[part 1 of 4: package /COM/VECTOR/CFG/WORKFLOW/SYSDESC/SYNC]
AUTOSAR XML (schema 4-3-0)
package /COM/VECTOR/CFG/WORKFLOW/SYSDESC/SYNC
  system SYSTEM: category=ECU_EXTRACT
    system mapping MAPPINGS
      data-mappings:
        sender-receiver-to-signal-mapping={data-element=COMPOSITIONTYPE.NO_VECH_{1..7}.NO_VECH_{1..7}, system-signal=NO_VECH_{1..7}}
        sender-receiver-to-signal-mapping={data-element=COMPOSITIONTYPE.ANFRAGE_ID2.requestedMsgID, system-signal=ANFRAGE_ID2}
        sender-receiver-to-signal-mapping={data-element=COMPOSITIONTYPE.ST_ENERG_FZM.energyState, system-signal=ST_ENERG_FZM}
        sender-receiver-to-signal-mapping={data-element=COMPOSITIONTYPE.ST_ILK_ERRM_FZM.centralErrorLock, system-signal=ST_ILK_ERRM_FZM}
        sender-receiver-to-signal-mapping={data-element=COMPOSITIONTYPE.T_SEC_COU_REL.timeSignal, system-signal=T_SEC_COU_REL}
        sender-receiver-to-signal-group-mapping={data-element=COMPOSITIONTYPE.sigGroup_CON_VEH.sigGroup_CON_VEH, signal-group=sigGroup_CON_VEH, type-mapping=sender-rec-record-type-mapping=record-element-mappings=[{implementation-record-element=ST_CON_VEH, system-signal=ST_CON_VEH}, {implementation-record-element=QU_ST_CON_VEH, system-signal=QU_ST_CON_VEH}, {implementation-record-element=CTR_FKTN_PRTNT, system-signal=CTR_FKTN_PRTNT}, {implementation-record-element=CTR_BS_PRTNT, system-signal=CTR_BS_PRTNT}, {implementation-record-element=CRC_CON_VEH, system-signal=CRC_CON_VEH}, {implementation-record-element=CON_VEH_dummy_56_63, system-signal=CON_VEH_dummy_56_63}, {implementation-record-element=ALIV_CON_VEH, system-signal=ALIV_CON_VEH}]}
        sender-receiver-to-signal-group-mapping={data-element=COMPOSITIONTYPE.sigGroup_OFFS_QUAD_EPS.sigGroup_OFFS_QUAD_EPS, signal-group=sigGroup_OFFS_QUAD_EPS, type-mapping=sender-rec-record-type-mapping=record-element-mappings=[{implementation-record-element=ST_OFFS_QUAD_EPS, system-signal=ST_OFFS_QUAD_EPS}, {implementation-record-element=OFFS_QUAD_RTR_EPS, system-signal=OFFS_QUAD_RTR_EPS}, {implementation-record-element=CRC_OFFS_QUAD_EPS, system-signal=CRC_OFFS_QUAD_EPS}, {implementation-record-element=AVL_PO_IDX_ICM, system-signal=AVL_PO_IDX_ICM}, {implementation-record-element=ALIV_OFFS_QUAD_EPS, system-signal=ALIV_OFFS_QUAD_EPS}]}
        sender-receiver-to-signal-group-mapping={data-element=COMPOSITIONTYPE.sigGroup_V_VEH.sigGroup_V_VEH, signal-group=sigGroup_V_VEH, type-mapping=sender-rec-record-type-mapping=record-element-mappings=[{implementation-record-element=V_VEH_dummy_39_39, system-signal=V_VEH_dummy_39_39}, {implementation-record-element=V_VEH_COG, system-signal=V_VEH_COG}, {implementation-record-element=ST_V_VEH_NSS, system-signal=ST_V_VEH_NSS}, {implementation-record-element=QU_V_VEH_COG, system-signal=QU_V_VEH_COG}, {implementation-record-element=DVCO_VEH, system-signal=DVCO_VEH}, {implementation-record-element=CRC_V_VEH, system-signal=CRC_V_VEH}, {implementation-record-element=ALIV_V_VEH, system-signal=ALIV_V_VEH}]}
        sender-receiver-to-signal-group-mapping={data-element=COMPOSITIONTYPE.sigGroup_DISP_CC_EPS.sigGroup_DISP_CC_EPS, signal-group=sigGroup_DISP_CC_EPS, type-mapping=sender-rec-record-type-mapping=record-element-mappings=[{implementation-record-element=TRANF_CC_EPS, system-signal=TRANF_CC_EPS}, {implementation-record-element=ST_IDC_CC_EPS, system-signal=ST_IDC_CC_EPS}, {implementation-record-element=ST_CC_EPS, system-signal=ST_CC_EPS}, {implementation-record-element=NO_CC_EPS, system-signal=NO_CC_EPS}, {implementation-record-element=CRC_DISP_CC_EPS, system-signal=CRC_DISP_CC_EPS}, {implementation-record-element=CHL_DISP_CC_EPS, system-signal=CHL_DISP_CC_EPS}, {implementation-record-element=ALIV_DISP_CC_EPS, system-signal=ALIV_DISP_CC_EPS}]}
        sender-receiver-to-signal-group-mapping={data-element=COMPOSITIONTYPE.sigGroup_AVL_PO_EPS.sigGroup_AVL_PO_EPS, signal-group=sigGroup_AVL_PO_EPS, type-mapping=sender-rec-record-type-mapping=record-element-mappings=[{implementation-record-element=UN_PO_EPS, system-signal=UN_PO_EPS}, {implementation-record-element=QU_AVL_PO_EPS, system-signal=QU_AVL_PO_EPS}, {implementation-record-element=OFFS_GRD_MID_EPS, system-signal=OFFS_GRD_MID_EPS}, {implementation-record-element=IDX_TORQ_SEN, system-signal=IDX_TORQ_SEN}, {implementation-record-element=CRC_AVL_PO_EPS, system-signal=CRC_AVL_PO_EPS}, {implementation-record-element=AVL_PO_IDX_EPS, system-signal=AVL_PO_IDX_EPS}, {implementation-record-element=AVL_PO_EPS, system-signal=AVL_PO_EPS}, {implementation-record-element=ALIV_AVL_PO_EPS, system-signal=ALIV_AVL_PO_EPS}]}
        sender-receiver-to-signal-mapping={data-element=COMPOSITIONTYPE.TRGG_ENGTORQ_EPS.TRGG_ENGTORQ_EPS, system-signal=TRGG_ENGTORQ_EPS}
        sender-receiver-to-signal-mapping={data-element=COMPOSITIONTYPE.FACT_MO_STE_SO_DXP.FACT_MO_STE_SO_DXP, system-signal=FACT_MO_STE_SO_DXP}
        sender-receiver-to-signal-mapping={data-element=COMPOSITIONTYPE.SU_CLU_STMOM_SFE_DXP.SU_CLU_STMOM_SFE_DXP, system-signal=SU_CLU_STMOM_SFE_DXP}
        sender-receiver-to-signal-group-mapping={data-element=COMPOSITIONTYPE.sigGroup_ST_EST.sigGroup_ST_EST, signal-group=sigGroup_ST_EST, type-mapping=sender-rec-record-type-mapping=record-element-mappings=[{implementation-record-element=ST_EST_dummy_16_23, system-signal=ST_EST_dummy_16_23}, {implementation-record-element=QU_SER_STMOM_DV_ACT, system-signal=QU_SER_STMOM_DV_ACT}, {implementation-record-element=QU_FN_VIB_EPS, system-signal=QU_FN_VIB_EPS}, {implementation-record-element=QU_FN_EST, system-signal=QU_FN_EST}, {implementation-record-element=CRC_ST_EST_FTAX, system-signal=CRC_ST_EST_FTAX}, {implementation-record-element=ALIV_ST_EST_FTAX, system-signal=ALIV_ST_EST_FTAX}]}
        sender-receiver-to-signal-group-mapping={data-element=COMPOSITIONTYPE.sigGroup_SU_EPS.sigGroup_SU_EPS, signal-group=sigGroup_SU_EPS, type-mapping=sender-rec-record-type-mapping=record-element-mappings=[{implementation-record-element=UN_TOT_STR_EPS, system-signal=UN_TOT_STR_EPS}, {implementation-record-element=TOT_STR_EPS, system-signal=TOT_STR_EPS}, {implementation-record-element=SU_EPS_dummy_20_51, system-signal=SU_EPS_dummy_20_51}, {implementation-record-element=SU_EPS_dummy_14_19, system-signal=SU_EPS_dummy_14_19}, {implementation-record-element=CRC_SU_EPS, system-signal=CRC_SU_EPS}, {implementation-record-element=ALIV_SU_EPS, system-signal=ALIV_SU_EPS}]}
        sender-receiver-to-signal-group-mapping={data-element=COMPOSITIONTYPE.sigGroup_ACLNY_MASSCNTR.sigGroup_ACLNY_MASSCNTR, signal-group=sigGroup_ACLNY_MASSCNTR, type-mapping=sender-rec-record-type-mapping=record-element-mappings=[{implementation-record-element=QU_ACLNY_COG, system-signal=QU_ACLNY_COG}, {implementation-record-element=CRC_ACLNY_COG, system-signal=CRC_ACLNY_COG}, {implementation-record-element=ALIV_ACLNY_COG, system-signal=ALIV_ACLNY_COG}, {implementation-record-element=ACLNY_MASSCNTR_dummy_12_15, system-signal=ACLNY_MASSCNTR_dummy_12_15}, {implementation-record-element=ACLNY_COG_ERR_AMP, system-signal=ACLNY_COG_ERR_AMP}, {implementation-record-element=ACLNY_COG, system-signal=ACLNY_COG}]}
        sender-receiver-to-signal-group-mapping={data-element=COMPOSITIONTYPE.sigGroup_TAR_QTA_STRMOM_DV.sigGroup_TAR_QTA_STRMOM_DV, signal-group=sigGroup_TAR_QTA_STRMOM_DV, type-mapping=sender-rec-record-type-mapping=record-element-mappings=[{implementation-record-element=TAR_QTA_STRMOM_DV_dummy_12_15, system-signal=TAR_QTA_STRMOM_DV_dummy_12_15}, {implementation-record-element=TAR_QTA_STMOM_DV, system-signal=TAR_QTA_STMOM_DV}, {implementation-record-element=QU_TAR_QTA_STMOM_DV, system-signal=QU_TAR_QTA_STMOM_DV}, {implementation-record-element=QU_TAR_FACT_STMOM_FTAX, system-signal=QU_TAR_FACT_STMOM_FTAX}, {implementation-record-element=FACT_DMPNG_STMOM_FTAX, system-signal=FACT_DMPNG_STMOM_FTAX}, {implementation-record-element=FACT_CTRR_STMOM_FTAX, system-signal=FACT_CTRR_STMOM_FTAX}, {implementation-record-element=FACT_ASS_STMOM_FTAX, system-signal=FACT_ASS_STMOM_FTAX}, {implementation-record-element=CTR_DEAC_EPS_FNS, system-signal=CTR_DEAC_EPS_FNS}, {implementation-record-element=CRC_TAR_QTA_STMOM_DV, system-signal=CRC_TAR_QTA_STMOM_DV}, {implementation-record-element=ALIV_TAR_QTA_STMOM_DV, system-signal=ALIV_TAR_QTA_STMOM_DV}]}
        sender-receiver-to-signal-group-mapping={data-element=COMPOSITIONTYPE.sigGroup_TAR_STMOM_DV_ACT.sigGroup_TAR_STMOM_DV_ACT, signal-group=sigGroup_TAR_STMOM_DV_ACT, type-mapping=sender-rec-record-type-mapping=record-element-mappings=[{implementation-record-element=TAR_STMOM_DV_ACT_dummy_32_51, system-signal=TAR_STMOM_DV_ACT_dummy_32_51}, {implementation-record-element=TAR_STMOM_DV_ACT_dummy_12_15, system-signal=TAR_STMOM_DV_ACT_dummy_12_15}, {implementation-record-element=TAR_STMOM_DV_ACT, system-signal=TAR_STMOM_DV_ACT}, {implementation-record-element=QU_TAR_STMOM_DV_ACT, system-signal=QU_TAR_STMOM_DV_ACT}, {implementation-record-element=QU_TAR_DMPNG_ADDON_STMOM_FTAX, system-signal=QU_TAR_DMPNG_ADDON_STMOM_FTAX}, {implementation-record-element=FACT_DMPNG_ADDON_STMOM_FTAX, system-signal=FACT_DMPNG_ADDON_STMOM_FTAX}, {implementation-record-element=CRC_TAR_STMOM_DV_ACT, system-signal=CRC_TAR_STMOM_DV_ACT}, {implementation-record-element=ALIV_TAR_STMOM_DV_ACT, system-signal=ALIV_TAR_STMOM_DV_ACT}]}
        sender-receiver-to-signal-group-mapping={data-element=COMPOSITIONTYPE.sigGroup_VYAW_VEH.sigGroup_VYAW_VEH, signal-group=sigGroup_VYAW_VEH, type-mapping=sender-rec-record-type-mapping=record-element-mappings=[{implementation-record-element=VYAW_VEH_dummy_12_15, system-signal=VYAW_VEH_dummy_12_15}, {implementation-record-element=VYAW_VEH_ERR_AMP, system-signal=VYAW_VEH_ERR_AMP}, {implementation-record-element=VYAW_VEH, system-signal=VYAW_VEH}, {implementation-record-element=QU_VYAW_VEH, system-signal=QU_VYAW_VEH}, {implementation-record-element=CRC_VYAW_VEH, system-signal=CRC_VYAW_VEH}, {implementation-record-element=ALIV_VYAW_VEH, system-signal=ALIV_VYAW_VEH}]}
        sender-receiver-to-signal-group-mapping={data-element=COMPOSITIONTYPE.sigGroup_DT_EST.sigGroup_DT_EST, signal-group=sigGroup_DT_EST, type-mapping=sender-rec-record-type-mapping=record-element-mappings=[{implementation-record-element=ST_CULI_EST, system-signal=ST_CULI_EST}, {implementation-record-element=QU_AVL_I_ACT_EST, system-signal=QU_AVL_I_ACT_EST}, {implementation-record-element=DT_EST_dummy_96_127, system-signal=DT_EST_dummy_96_127}, {implementation-record-element=DT_EST_dummy_64_95, system-signal=DT_EST_dummy_64_95}, {implementation-record-element=DT_EST_dummy_16_47, system-signal=DT_EST_dummy_16_47}, {implementation-record-element=DT_EST_dummy_12_15, system-signal=DT_EST_dummy_12_15}, {implementation-record-element=CRC_DT_EST, system-signal=CRC_DT_EST}, {implementation-record-element=AVL_I_ACT_EST, system-signal=AVL_I_ACT_EST}, {implementation-record-element=ALIV_DT_EST, system-signal=ALIV_DT_EST}]}
        sender-receiver-to-signal-mapping={data-element=COMPOSITIONTYPE.AVL_STEA_PNI_OFFS.AVL_STEA_PNI_OFFS, system-signal=AVL_STEA_PNI_OFFS}
        sender-receiver-to-signal-mapping={data-element=COMPOSITIONTYPE.CTR_WARN_DIR_VIB_EPS.CTR_WARN_DIR_VIB_EPS, system-signal=CTR_WARN_DIR_VIB_EPS}
        sender-receiver-to-signal-mapping={data-element=COMPOSITIONTYPE.CTR_WARN_ILVL_VIB_EPS.CTR_WARN_ILVL_VIB_EPS, system-signal=CTR_WARN_ILVL_VIB_EPS}
        sender-receiver-to-signal-mapping={data-element=COMPOSITIONTYPE.CTR_WARN_PTRN_VIB_EPS.CTR_WARN_PTRN_VIB_EPS, system-signal=CTR_WARN_PTRN_VIB_EPS}
        sender-receiver-to-signal-mapping={data-element=COMPOSITIONTYPE.MILE_KM.MILE_KM, system-signal=MILE_KM}
        sender-receiver-to-signal-group-mapping={data-element=COMPOSITIONTYPE.sigGroup_ENERG_DGR_DRDY.sigGroup_ENERG_DGR_DRDY, signal-group=sigGroup_ENERG_DGR_DRDY, type-mapping=sender-rec-record-type-mapping=record-element-mappings=[{implementation-record-element=RQ_CULI_EST_SFY, system-signal=RQ_CULI_EST_SFY}, {implementation-record-element=QU_DGR_AISP_ENERG, system-signal=QU_DGR_AISP_ENERG}, {implementation-record-element=MAX_I_SPEC_EPS, system-signal=MAX_I_SPEC_EPS}, {implementation-record-element=MAX_I_SPEC_BAX_STE, system-signal=MAX_I_SPEC_BAX_STE}, {implementation-record-element=MAX_I_RECUP_SPEC_ARS, system-signal=MAX_I_RECUP_SPEC_ARS}, {implementation-record-element=MAX_I_LD_SPEC_ARS, system-signal=MAX_I_LD_SPEC_ARS}, {implementation-record-element=ENERG_DGR_DRDY_dummy_12_15, system-signal=ENERG_DGR_DRDY_dummy_12_15}, {implementation-record-element=ENERG_AVAI_ARS, system-signal=ENERG_AVAI_ARS}, {implementation-record-element=CRC_ENERG_DGR_DRDY, system-signal=CRC_ENERG_DGR_DRDY}, {implementation-record-element=ALIV_ENERG_DGR_DRDY, system-signal=ALIV_ENERG_DGR_DRDY}]}
        sender-receiver-to-signal-group-mapping={data-element=COMPOSITIONTYPE.sigGroup_AVL_FORC_GRD.sigGroup_AVL_FORC_GRD, signal-group=sigGroup_AVL_FORC_GRD, type-mapping=sender-rec-record-type-mapping=record-element-mappings=[{implementation-record-element=QU_AVL_FORC_GRD, system-signal=QU_AVL_FORC_GRD}, {implementation-record-element=CRC_AVL_FORC_GRD, system-signal=CRC_AVL_FORC_GRD}, {implementation-record-element=AVL_PWR_EL_EPS_COOD, system-signal=AVL_PWR_EL_EPS_COOD}, {implementation-record-element=AVL_FORC_GRD_dummy_12_15, system-signal=AVL_FORC_GRD_dummy_12_15}, {implementation-record-element=AVL_FORC_GRD, system-signal=AVL_FORC_GRD}, {implementation-record-element=ALIV_AVL_FORC_GRD, system-signal=ALIV_AVL_FORC_GRD}]}
        sender-receiver-to-signal-group-mapping={data-element=COMPOSITIONTYPE.sigGroup_AVL_STMOM_DV_ACT.sigGroup_AVL_STMOM_DV_ACT, signal-group=sigGroup_AVL_STMOM_DV_ACT, type-mapping=sender-rec-record-type-mapping=record-element-mappings=[{implementation-record-element=QU_AVL_STMOM_DV_ACT, system-signal=QU_AVL_STMOM_DV_ACT}, {implementation-record-element=CRC_AVL_STMOM_DV_ACT, system-signal=CRC_AVL_STMOM_DV_ACT}, {implementation-record-element=AVL_STMOM_DV_ACT_dummy_12_15, system-signal=AVL_STMOM_DV_ACT_dummy_12_15}, {implementation-record-element=AVL_STMOM_DV_ACT, system-signal=AVL_STMOM_DV_ACT}, {implementation-record-element=ALIV_AVL_STMOM_DV_ACT, system-signal=ALIV_AVL_STMOM_DV_ACT}]}
        sender-receiver-to-signal-mapping={data-element=COMPOSITIONTYPE.BATT_VLTG_EPS.BATT_VLTG_EPS, system-signal=BATT_VLTG_EPS}
        sender-receiver-to-signal-mapping={data-element=COMPOSITIONTYPE.DBG_EPS_BS_MOD_58_BYTE_ID2.DBG_EPS_BS_MOD_58_BYTE_ID2, system-signal=DBG_EPS_BS_MOD_58_BYTE_ID2}
        sender-receiver-to-signal-mapping={data-element=COMPOSITIONTYPE.ECU_TEMP_EPS.ECU_TEMP_EPS, system-signal=ECU_TEMP_EPS}
        sender-receiver-to-signal-mapping={data-element=COMPOSITIONTYPE.MOT_FET_TEMP_EPS.MOT_FET_TEMP_EPS, system-signal=MOT_FET_TEMP_EPS}
        sender-receiver-to-signal-mapping={data-element=COMPOSITIONTYPE.MOT_MAG_TEMP_EPS.MOT_MAG_TEMP_EPS, system-signal=MOT_MAG_TEMP_EPS}
        sender-receiver-to-signal-mapping={data-element=COMPOSITIONTYPE.MOT_TQ_CMD_EPS.MOT_TQ_CMD_EPS, system-signal=MOT_TQ_CMD_EPS}
        sender-receiver-to-signal-mapping={data-element=COMPOSITIONTYPE.MOT_TQ_CMD_LIMD_EPS.MOT_TQ_CMD_LIMD_EPS, system-signal=MOT_TQ_CMD_LIMD_EPS}
        sender-receiver-to-signal-mapping={data-element=COMPOSITIONTYPE.MOT_VEL_EPS.MOT_VEL_EPS, system-signal=MOT_VEL_EPS}
        sender-receiver-to-signal-mapping={data-element=COMPOSITIONTYPE.MOT_WIDG_TEMP_EPS.MOT_WIDG_TEMP_EPS, system-signal=MOT_WIDG_TEMP_EPS}
        sender-receiver-to-signal-mapping={data-element=COMPOSITIONTYPE.PRIM_HW_TQ_SNSR_VLTG_EPS.PRIM_HW_TQ_SNSR_VLTG_EPS, system-signal=PRIM_HW_TQ_SNSR_VLTG_EPS}
        sender-receiver-to-signal-mapping={data-element=COMPOSITIONTYPE.SECDRY_HW_TQ_SNSR_VLTG_EPS.SECDRY_HW_TQ_SNSR_VLTG_EPS, system-signal=SECDRY_HW_TQ_SNSR_VLTG_EPS}
        sender-receiver-to-signal-mapping={data-element=COMPOSITIONTYPE.VEH_SPD_EPS.VEH_SPD_EPS, system-signal=VEH_SPD_EPS}
    root-software-compositions:
      root sw composition prototype COMPOSITIONTYPE: flat-map=FLATMAP, software-composition=COMPOSITIONTYPE
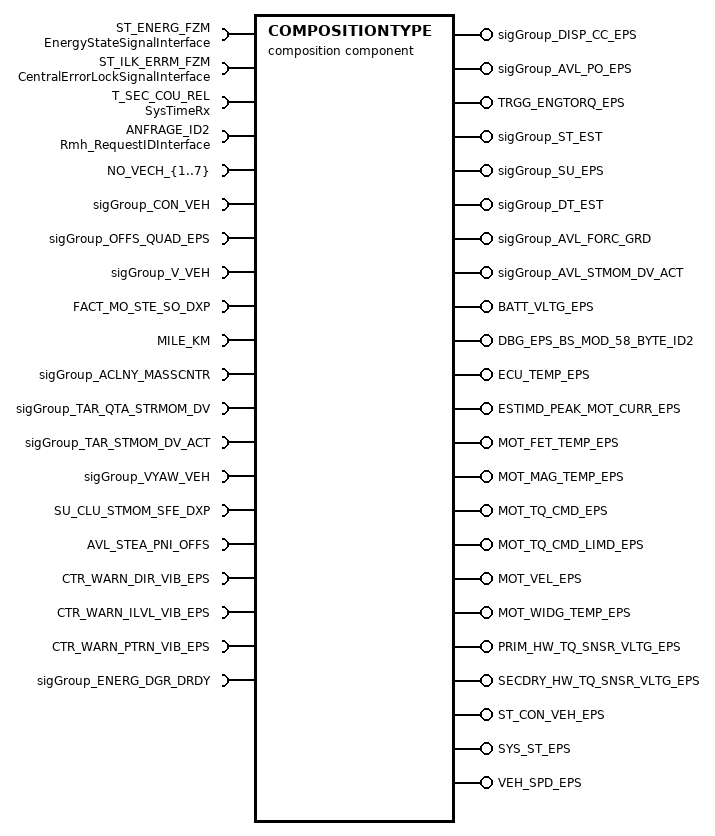
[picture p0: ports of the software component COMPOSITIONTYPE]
  composition sw component type COMPOSITIONTYPE  # UB:Derived from original system description
    14 x require port:
      ST_ENERG_FZM: nonqueued-receiver-com-spec{data-element=energyState, uses-end-to-end-protection=true, alive-timeout=21, enable-update=true, filter=data-filter-type=ALWAYS, init-value=15}, required-interface=EnergyStateSignalInterface
      ST_ILK_ERRM_FZM: nonqueued-receiver-com-spec{data-element=centralErrorLock, alive-timeout=21, filter=data-filter-type=ALWAYS, init-value=3}, required-interface=CentralErrorLockSignalInterface
      T_SEC_COU_REL: nonqueued-receiver-com-spec{data-element=timeSignal, filter=data-filter-type=ALWAYS}, required-interface=SysTimeRx
      ANFRAGE_ID2: nonqueued-receiver-com-spec{data-element=requestedMsgID, filter=data-filter-type=ALWAYS}, required-interface=Rmh_RequestIDInterface
      NO_VECH_{1..7}: nonqueued-receiver-com-spec{data-element=NO_VECH_{1..7}, filter=data-filter-type=ALWAYS}, required-interface=NO_VECH_{1..7}
      sigGroup_CON_VEH: nonqueued-receiver-com-spec{data-element=sigGroup_CON_VEH, uses-end-to-end-protection=true, alive-timeout=0.11, enable-update=true, filter=data-filter-type=ALWAYS, init-value=fields=[0, CON_VEH_dummy_56_63:15, CRC_CON_VEH:0, CTR_BS_PRTNT:15, CTR_FKTN_PRTNT:15, QU_ST_CON_VEH:0, ST_CON_VEH:0]}, required-interface=sigGroup_CON_VEH
      sigGroup_OFFS_QUAD_EPS: nonqueued-receiver-com-spec{data-element=sigGroup_OFFS_QUAD_EPS, uses-end-to-end-protection=true, alive-timeout=1.1, enable-update=true, filter=data-filter-type=ALWAYS, init-value=fields=[AVL_PO_IDX_ICM:65535, ST_OFFS_QUAD_EPS:15, CRC_OFFS_QUAD_EPS:0, OFFS_QUAD_RTR_EPS:255, ALIV_OFFS_QUAD_EPS:0]}, required-interface=sigGroup_OFFS_QUAD_EPS
      sigGroup_V_VEH: nonqueued-receiver-com-spec{data-element=sigGroup_V_VEH, uses-end-to-end-protection=true, alive-timeout=0.02, enable-update=true, filter=data-filter-type=ALWAYS, init-value=fields=[0, CRC_V_VEH:0, DVCO_VEH:0, QU_V_VEH_COG:0, ST_V_VEH_NSS:1, V_VEH_COG:0, V_VEH_dummy_39_39:0]}, required-interface=sigGroup_V_VEH
    5 x provide port:
      sigGroup_DISP_CC_EPS: nonqueued-sender-com-spec{data-element=sigGroup_DISP_CC_EPS, uses-end-to-end-protection=true}, provided-interface=sigGroup_DISP_CC_EPS
      sigGroup_AVL_PO_EPS: nonqueued-sender-com-spec{data-element=sigGroup_AVL_PO_EPS, uses-end-to-end-protection=true}, provided-interface=sigGroup_AVL_PO_EPS
      TRGG_ENGTORQ_EPS: nonqueued-sender-com-spec=data-element=TRGG_ENGTORQ_EPS, provided-interface=TRGG_ENGTORQ_EPS
      sigGroup_ST_EST: nonqueued-sender-com-spec{data-element=sigGroup_ST_EST, uses-end-to-end-protection=true}, provided-interface=sigGroup_ST_EST
      sigGroup_SU_EPS: nonqueued-sender-com-spec{data-element=sigGroup_SU_EPS, uses-end-to-end-protection=true}, provided-interface=sigGroup_SU_EPS
    8 x require port:
      FACT_MO_STE_SO_DXP: nonqueued-receiver-com-spec{data-element=FACT_MO_STE_SO_DXP, alive-timeout=0.045, filter=data-filter-type=ALWAYS, init-value=255}, required-interface=FACT_MO_STE_SO_DXP
      MILE_KM: nonqueued-receiver-com-spec{data-element=MILE_KM, alive-timeout=11, filter=data-filter-type=ALWAYS, init-value=0}, required-interface=MILE_KM
      sigGroup_ACLNY_MASSCNTR: nonqueued-receiver-com-spec{data-element=sigGroup_ACLNY_MASSCNTR, uses-end-to-end-protection=true, alive-timeout=0.015, enable-update=true, filter=data-filter-type=ALWAYS}, required-interface=sigGroup_ACLNY_MASSCNTR
      sigGroup_TAR_QTA_STRMOM_DV: nonqueued-receiver-com-spec{data-element=sigGroup_TAR_QTA_STRMOM_DV, uses-end-to-end-protection=true, alive-timeout=0.015, enable-update=true, filter=data-filter-type=ALWAYS}, required-interface=sigGroup_TAR_QTA_STRMOM_DV
      sigGroup_TAR_STMOM_DV_ACT: nonqueued-receiver-com-spec{data-element=sigGroup_TAR_STMOM_DV_ACT, uses-end-to-end-protection=true, alive-timeout=0.015, enable-update=true, filter=data-filter-type=ALWAYS}, required-interface=sigGroup_TAR_STMOM_DV_ACT
      sigGroup_VYAW_VEH: nonqueued-receiver-com-spec{data-element=sigGroup_VYAW_VEH, uses-end-to-end-protection=true, alive-timeout=0.015, enable-update=true, filter=data-filter-type=ALWAYS}, required-interface=sigGroup_VYAW_VEH
      SU_CLU_STMOM_SFE_DXP: nonqueued-receiver-com-spec{data-element=SU_CLU_STMOM_SFE_DXP, alive-timeout=0.045, filter=data-filter-type=ALWAYS, init-value=15}, required-interface=SU_CLU_STMOM_SFE_DXP
      AVL_STEA_PNI_OFFS: nonqueued-receiver-com-spec{data-element=AVL_STEA_PNI_OFFS, uses-end-to-end-protection=true, alive-timeout=0.11, enable-update=true, filter=data-filter-type=ALWAYS, init-value=2046}, required-interface=AVL_STEA_PNI_OFFS
    provide port sigGroup_DT_EST: nonqueued-sender-com-spec{data-element=sigGroup_DT_EST, uses-end-to-end-protection=true}, provided-interface=sigGroup_DT_EST
    4 x require port:
      CTR_WARN_DIR_VIB_EPS: nonqueued-receiver-com-spec{data-element=CTR_WARN_DIR_VIB_EPS, alive-timeout=0.55, filter=data-filter-type=ALWAYS, init-value=3}, required-interface=CTR_WARN_DIR_VIB_EPS
      CTR_WARN_ILVL_VIB_EPS: nonqueued-receiver-com-spec{data-element=CTR_WARN_ILVL_VIB_EPS, alive-timeout=0.55, filter=data-filter-type=ALWAYS, init-value=15}, required-interface=CTR_WARN_ILVL_VIB_EPS
      CTR_WARN_PTRN_VIB_EPS: nonqueued-receiver-com-spec{data-element=CTR_WARN_PTRN_VIB_EPS, alive-timeout=0.55, filter=data-filter-type=ALWAYS, init-value=15}, required-interface=CTR_WARN_PTRN_VIB_EPS
      sigGroup_ENERG_DGR_DRDY: nonqueued-receiver-com-spec{data-element=sigGroup_ENERG_DGR_DRDY, uses-end-to-end-protection=true, alive-timeout=0.015, enable-update=true, filter=data-filter-type=ALWAYS}, required-interface=sigGroup_ENERG_DGR_DRDY
    17 x provide port:
      sigGroup_AVL_FORC_GRD: nonqueued-sender-com-spec{data-element=sigGroup_AVL_FORC_GRD, uses-end-to-end-protection=true}, provided-interface=sigGroup_AVL_FORC_GRD
      sigGroup_AVL_STMOM_DV_ACT: nonqueued-sender-com-spec{data-element=sigGroup_AVL_STMOM_DV_ACT, uses-end-to-end-protection=true}, provided-interface=sigGroup_AVL_STMOM_DV_ACT
      BATT_VLTG_EPS: nonqueued-sender-com-spec{data-element=BATT_VLTG_EPS, init-value=0}, provided-interface=BATT_VLTG_EPS
      DBG_EPS_BS_MOD_58_BYTE_ID2: nonqueued-sender-com-spec{data-element=DBG_EPS_BS_MOD_58_BYTE_ID2, init-value=SWITCH_CODE:1}, provided-interface=DBG_EPS_BS_MOD_58_BYTE_ID2
      ECU_TEMP_EPS: nonqueued-sender-com-spec=data-element=ECU_TEMP_EPS, provided-interface=ECU_TEMP_EPS
      ESTIMD_PEAK_MOT_CURR_EPS: nonqueued-sender-com-spec=data-element=ESTIMD_PEAK_MOT_CURR_EPS, provided-interface=ESTIMD_PEAK_MOT_CURR_EPS
      MOT_FET_TEMP_EPS: nonqueued-sender-com-spec=data-element=MOT_FET_TEMP_EPS, provided-interface=MOT_FET_TEMP_EPS
      MOT_MAG_TEMP_EPS: nonqueued-sender-com-spec=data-element=MOT_MAG_TEMP_EPS, provided-interface=MOT_MAG_TEMP_EPS
      MOT_TQ_CMD_EPS: nonqueued-sender-com-spec=data-element=MOT_TQ_CMD_EPS, provided-interface=MOT_TQ_CMD_EPS
      MOT_TQ_CMD_LIMD_EPS: nonqueued-sender-com-spec=data-element=MOT_TQ_CMD_LIMD_EPS, provided-interface=MOT_TQ_CMD_LIMD_EPS
      MOT_VEL_EPS: nonqueued-sender-com-spec=data-element=MOT_VEL_EPS, provided-interface=MOT_VEL_EPS
      MOT_WIDG_TEMP_EPS: nonqueued-sender-com-spec=data-element=MOT_WIDG_TEMP_EPS, provided-interface=MOT_WIDG_TEMP_EPS
      PRIM_HW_TQ_SNSR_VLTG_EPS: nonqueued-sender-com-spec=data-element=PRIM_HW_TQ_SNSR_VLTG_EPS, provided-interface=PRIM_HW_TQ_SNSR_VLTG_EPS
      SECDRY_HW_TQ_SNSR_VLTG_EPS: nonqueued-sender-com-spec=data-element=SECDRY_HW_TQ_SNSR_VLTG_EPS, provided-interface=SECDRY_HW_TQ_SNSR_VLTG_EPS
      ST_CON_VEH_EPS: nonqueued-sender-com-spec=data-element=ST_CON_VEH_EPS, provided-interface=ST_CON_VEH_EPS
      SYS_ST_EPS: nonqueued-sender-com-spec=data-element=SYS_ST_EPS, provided-interface=SYS_ST_EPS
      VEH_SPD_EPS: nonqueued-sender-com-spec=data-element=VEH_SPD_EPS, provided-interface=VEH_SPD_EPS
    276 x component:
      BswM: type=BswM
      Det: type=Det
      EcuM: type=EcuM
      Os_OsCore_CORE0_swc: type=Os_OsCore_CORE0_swc
      NvM: type=NvM
      WdgM_Appl10: type=WdgM_Appl10
      McalErrHndlg: type=McalErrHndlg
      CDD_NxtrTi: type=CDD_NxtrTi
      NxtrMath: type=NxtrMath
      McuErrInj: type=McuErrInj
      CDD_ExcpnHndlg: type=CDD_ExcpnHndlg
      DiagcMgr: type=DiagcMgr
      DiagcMgrProxyAppl10: type=DiagcMgrProxyAppl10
      DiagcMgrStub: type=DiagcMgrStub
      SysStMod: type=SysStMod
      CDD_NvMProxy: type=CDD_NvMProxy
      NvMProxy: type=NvMProxy
      CDD_EcmOutpAndDiagc: type=CDD_EcmOutpAndDiagc
      CDD_GuardCfgAndDiagc: type=CDD_GuardCfgAndDiagc
      CDD_SyncCrc: type=CDD_SyncCrc
      FltInj: type=FltInj
      CDD_Adc0CfgAndUse: type=CDD_Adc0CfgAndUse
      CDD_Adc1CfgAndUse: type=CDD_Adc1CfgAndUse
      CDD_AdcDiagc: type=CDD_AdcDiagc
      CDD_DmaCfgAndUse: type=CDD_DmaCfgAndUse
      CDD_MotAg0Meas: type=CDD_MotAg0Meas
      CDD_MotAg1Meas: type=CDD_MotAg1Meas
      CDD_Tauj0CfgAndUse: type=CDD_Tauj0CfgAndUse
      CDD_TSG31CfgAndUse: type=CDD_TSG31CfgAndUse
      CDD_MotCtrlMgr: type=CDD_MotCtrlMgr
      IoHwAb: type=IoHwAb
      CDD_CurrMeas: type=CDD_CurrMeas
      MotAgCorrln: type=MotAgCorrln
      CDD_Bmw5441McuCfg: type=CDD_Bmw5441McuCfg
      BattVltg: type=BattVltg
      BattVltgCorrln: type=BattVltgCorrln
      EcuTMeas: type=EcuTMeas
      CDD_FlsMem: type=CDD_FlsMem
      CDD_RamMem: type=CDD_RamMem
      CDD_ChkPtAppl10: type=CDD_ChkPtAppl10
      ComM: type=ComM
      Dcm: type=Dcm
      Vin: type=Vin
      CmnMfgSrv: type=CmnMfgSrv
      NxtrSwIds: type=NxtrSwIds
      CDD_MotAgCmp: type=CDD_MotAgCmp
      CDD_SinVltgGenn: type=CDD_SinVltgGenn
      GateDrv0Ctrl: type=GateDrv0Ctrl
      PolarityCfg: type=PolarityCfg
      PwrDiscnct: type=PwrDiscnct
      PwrSply: type=PwrSply
      PwrUpSeq: type=PwrUpSeq
      ShtdwnMech: type=ShtdwnMech
      TmplMonr: type=TmplMonr
      CDD_HwTq4Meas: type=CDD_HwTq4Meas
      CDD_HwTq5Meas: type=CDD_HwTq5Meas
      HwTqArbn: type=HwTqArbn
      HwTqCorrln: type=HwTqCorrln
      CDD_MotCurrRegVltgLimr: type=CDD_MotCurrRegVltgLimr
      CDD_MotVel: type=CDD_MotVel
      DutyCycThermProtn: type=DutyCycThermProtn
      ElecPwrCns: type=ElecPwrCns
      HiLoadStallLimr: type=HiLoadStallLimr
      MotCtrlPrmEstimn: type=MotCtrlPrmEstimn
      MotCurrPeakEstimn: type=MotCurrPeakEstimn
      MotCurrRegCfg: type=MotCurrRegCfg
      MotQuadDetn: type=MotQuadDetn
      MotRefMdl: type=MotRefMdl
      PwrLimr: type=PwrLimr
      TEstimn: type=TEstimn
      MotTqCmdSca: type=MotTqCmdSca
      MotTqTranlDampg: type=MotTqTranlDampg
      Swp: type=Swp
      BacComIf: type=BacComIf
      CDD_ChkPtAppl{7..9}: type=CDD_ChkPtAppl{7..9}
      WdgM_Appl9: type=WdgM_Appl9
      WdgM_Appl8: type=WdgM_Appl8
      WdgM_Appl7: type=WdgM_Appl7
      EotProtn: type=EotProtn
      PosnTrakgServo: type=PosnTrakgServo
      StOutpCtrl: type=StOutpCtrl
      SysFricLrng: type=SysFricLrng
      VehSpdLimr: type=VehSpdLimr
      VehSigCdng: type=VehSigCdng
      CmplncErr: type=CmplncErr
      LimrCdng: type=LimrCdng
      TunSelnAuthy: type=TunSelnAuthy
      CDD_CurrMeasArbn: type=CDD_CurrMeasArbn
      CurrMeasCorrln: type=CurrMeasCorrln
      TurnCntrCorrln: type=TurnCntrCorrln
      CDD_McuDiagc: type=CDD_McuDiagc
      MotVelCtrl: type=MotVelCtrl
      CDD_CoreVltgMonr: type=CDD_CoreVltgMonr
      CDD_McuCoreCfgAndDiagc: type=CDD_McuCoreCfgAndDiagc
      CDD_VrfyCritReg: type=CDD_VrfyCritReg
      CDD_DataAndAdrPar: type=CDD_DataAndAdrPar
      BmwMsgSlot107Bas0Repn1BusFrChA: type=BmwMsgSlot107Bas0Repn1BusFrChA
      BmwMsgSlot121Bas1Repn2BusFrChA: type=BmwMsgSlot121Bas1Repn2BusFrChA
      BmwMsgSlot55Bas3Repn4BusFrChA: type=BmwMsgSlot55Bas3Repn4BusFrChA
      DiagcMgrProxyAppl7: type=DiagcMgrProxyAppl7
      BmwHwAgArbnAndEotPosn: type=BmwHwAgArbnAndEotPosn
      LrndRackCentr: type=LrndRackCentr
      LrnPinionCentr: type=LrnPinionCentr
      BmwMsgSlot274Bas2Repn4BusFrChA: type=BmwMsgSlot274Bas2Repn4BusFrChA
      BmwMsgSlot51Bas0Repn2BusFrChA: type=BmwMsgSlot51Bas0Repn2BusFrChA
      BmwFltHndlg: type=BmwFltHndlg
      BmwStReqMgr: type=BmwStReqMgr
      CtrldVelRtn: type=CtrldVelRtn
      DiagcMgrProxyAppl8: type=DiagcMgrProxyAppl8
      DiagcMgrProxyAppl9: type=DiagcMgrProxyAppl9
      BmwDiagcSrvHndlg: type=BmwDiagcSrvHndlg
      CDD_XcpIf: type=CDD_XcpIf
      TunSelnMngt: type=TunSelnMngt
      CDD_XcpIfXcpEve2MilliSecDataAcqn: type=CDD_XcpIfXcpEve2MilliSecDataAcqn
      PhaDiscnct: type=PhaDiscnct
      RvsBattProtn: type=RvsBattProtn
      LoaMgr: type=LoaMgr
      CDD_BattRtnCurr: type=CDD_BattRtnCurr
      BmwVehSpd: type=BmwVehSpd
      Dlog: type=Dlog
      StdDiag: type=StdDiag
      Omc: type=Omc
      Darh: type=Darh
      Stm: type=Stm
      Coding: type=Coding
      Rmh: type=Rmh
      Rmh_Cdd: type=Rmh_Cdd
      SysTime: type=SysTime
      DemMaster_0: type=DemMaster_0
      DemSatellite_0: type=DemSatellite_0
      CmnMfgSrvIf: type=CmnMfgSrvIf
      DemWrapper: type=DemWrapper
      BmwTunSetHndlr: type=BmwTunSetHndlr
      ProgMfgSrv: type=ProgMfgSrv
      CDD_MotAg3Meas: type=CDD_MotAg3Meas
      CDD_MotAg4Meas: type=CDD_MotAg4Meas
      ClsdLoopDampg: type=ClsdLoopDampg
      Effort: type=Effort
      HwRefTqSum: type=HwRefTqSum
      HwTqTrakgCtrl: type=HwTqTrakgCtrl
      MotTqCalcd: type=MotTqCalcd
      SysKineAndEff: type=SysKineAndEff
      TqOscn: type=TqOscn
      EpsStEstimn: type=EpsStEstimn
      BmwMsgSlot234Bas1Repn2BusFrChA: type=BmwMsgSlot234Bas1Repn2BusFrChA
      BmwMsgSlot274Bas0Repn8BusFrChA: type=BmwMsgSlot274Bas0Repn8BusFrChA
      BmwMsgSlot276Bas4Repn8BusFrChA: type=BmwMsgSlot276Bas4Repn8BusFrChA
      BmwMsgSlot53Bas3Repn8BusFrChA: type=BmwMsgSlot53Bas3Repn8BusFrChA
      BmwMsgSlot55Bas0Repn2BusFrChA: type=BmwMsgSlot55Bas0Repn2BusFrChA
      BmwMsgSlot56Bas0Repn2BusFrChA: type=BmwMsgSlot56Bas0Repn2BusFrChA
      BmwMsgSlot68Bas0Repn2BusFrChA: type=BmwMsgSlot68Bas0Repn2BusFrChA
      BmwMsgSlot108Bas0Repn2BusFrChA: type=BmwMsgSlot108Bas0Repn2BusFrChA
      GlbLimr: type=GlbLimr
      BmwMsgSlot269Bas2Repn4BusFrChA: type=BmwMsgSlot269Bas2Repn4BusFrChA
      BmwMsgSlot49Bas1Repn2BusFrChA: type=BmwMsgSlot49Bas1Repn2BusFrChA
      BmwMsgSlot68Bas1Repn2BusFrChA: type=BmwMsgSlot68Bas1Repn2BusFrChA
      BmwDrvgDynStMac: type=BmwDrvgDynStMac
      BmwHwTqOvrlArbn: type=BmwHwTqOvrlArbn
      BmwMotTqOvrlArbn: type=BmwMotTqOvrlArbn
      BmwMsgSlot49Bas0Repn2BusFrChA: type=BmwMsgSlot49Bas0Repn2BusFrChA
      BmwTqOvrlCdngAndDrvgDynFac: type=BmwTqOvrlCdngAndDrvgDynFac
      BmwTrfcJamAssiDampg: type=BmwTrfcJamAssiDampg
      FalbckAssi: type=FalbckAssi
      SteerCmdArbnAndLim: type=SteerCmdArbnAndLim
      ClsdLoopHys: type=ClsdLoopHys
      AAACalRegn01IninOptSetA{00..03}_Dummy: type=AAACalRegn01IninOptSetA01_Dummy
      AAACalRegn02Rt00_Dummy: type=AAACalRegn02Rt01_Dummy
      AAACalRegn02Rt00GroupA_Dummy: type=AAACalRegn02Rt01GroupA_Dummy
      AAACalRegn02Rt00GroupC_Dummy: type=AAACalRegn02Rt01GroupC_Dummy
      AAACalRegn02Rt01_Dummy: type=AAACalRegn02Rt01_Dummy
      AAACalRegn02Rt01GroupA_Dummy: type=AAACalRegn02Rt01GroupA_Dummy
      AAACalRegn02Rt01GroupC_Dummy: type=AAACalRegn02Rt01GroupC_Dummy
      AAACalRegn02Rt02_Dummy: type=AAACalRegn02Rt01_Dummy
      AAACalRegn02Rt02GroupA_Dummy: type=AAACalRegn02Rt01GroupA_Dummy
      AAACalRegn02Rt02GroupC_Dummy: type=AAACalRegn02Rt01GroupC_Dummy
      AAACalRegn02Rt03_Dummy: type=AAACalRegn02Rt01_Dummy
      AAACalRegn02Rt03GroupA_Dummy: type=AAACalRegn02Rt01GroupA_Dummy
      AAACalRegn02Rt03GroupC_Dummy: type=AAACalRegn02Rt01GroupC_Dummy
      CalRegn01Cmn: type=CalRegn01Cmn
      CalRegn01CmnGroupA: type=CalRegn01CmnGroupA
      CalRegn01CmnGroupC: type=CalRegn01CmnGroupC
      CalRegn01CmnGroupD: type=CalRegn01CmnGroupD
      CalRegn01IninOptSetA{00..03}: type=CalRegn01IninOptSetA{00..03}
      CalRegn02Rt00: type=CalRegn02Rt00
      CalRegn02Rt00GroupA: type=CalRegn02Rt00GroupA
      CalRegn02Rt00GroupC: type=CalRegn02Rt00GroupC
      CalRegn02Rt01: type=CalRegn02Rt01
      CalRegn02Rt01GroupA: type=CalRegn02Rt01GroupA
      CalRegn02Rt01GroupC: type=CalRegn02Rt01GroupC
      CalRegn02Rt02: type=CalRegn02Rt02
      CalRegn02Rt02GroupA: type=CalRegn02Rt02GroupA
      CalRegn02Rt02GroupC: type=CalRegn02Rt02GroupC
      CalRegn02Rt03: type=CalRegn02Rt03
      CalRegn02Rt03GroupA: type=CalRegn02Rt03GroupA
      CalRegn02Rt03GroupC: type=CalRegn02Rt03GroupC
      BmwMsgSlot315Bas0Repn1BusFrChA: type=BmwMsgSlot315Bas0Repn1BusFrChA
      BmwHaptcFb: type=BmwHaptcFb
      BmwSplyCurrLim: type=BmwSplyCurrLim
      NxtrCalIds: type=NxtrCalIds
      CalRegn01CmnGroupB: type=CalRegn01CmnGroupB
      BmwPwrPrkgDampg: type=BmwPwrPrkgDampg
      InertiaCmpVel: type=InertiaCmpVel
      PullCmpActv: type=PullCmpActv
      AAACalRegn01Inin00_Dummy: type=AAACalRegn01Inin01_Dummy
      AAACalRegn01Inin00GroupA_Dummy: type=AAACalRegn01Inin01GroupA_Dummy
      AAACalRegn01Inin00GroupC_Dummy: type=AAACalRegn01Inin01GroupC_Dummy
      AAACalRegn01Inin00GroupD_Dummy: type=AAACalRegn01Inin01GroupD_Dummy
      AAACalRegn01Inin01_Dummy: type=AAACalRegn01Inin01_Dummy
      AAACalRegn01Inin01GroupA_Dummy: type=AAACalRegn01Inin01GroupA_Dummy
      AAACalRegn01Inin01GroupC_Dummy: type=AAACalRegn01Inin01GroupC_Dummy
      AAACalRegn01Inin01GroupD_Dummy: type=AAACalRegn01Inin01GroupD_Dummy
      AAACalRegn01Inin02_Dummy: type=AAACalRegn01Inin01_Dummy
      AAACalRegn01Inin02GroupA_Dummy: type=AAACalRegn01Inin01GroupA_Dummy
      AAACalRegn01Inin02GroupC_Dummy: type=AAACalRegn01Inin01GroupC_Dummy
      AAACalRegn01Inin02GroupD_Dummy: type=AAACalRegn01Inin01GroupD_Dummy
      AAACalRegn01Inin03_Dummy: type=AAACalRegn01Inin01_Dummy
      AAACalRegn01Inin03GroupA_Dummy: type=AAACalRegn01Inin01GroupA_Dummy
      AAACalRegn01Inin03GroupC_Dummy: type=AAACalRegn01Inin01GroupC_Dummy
      AAACalRegn01Inin03GroupD_Dummy: type=AAACalRegn01Inin01GroupD_Dummy
      AAACalRegn01Inin04_Dummy: type=AAACalRegn01Inin01_Dummy
      AAACalRegn01Inin04GroupA_Dummy: type=AAACalRegn01Inin01GroupA_Dummy
      AAACalRegn01Inin04GroupC_Dummy: type=AAACalRegn01Inin01GroupC_Dummy
      AAACalRegn01Inin04GroupD_Dummy: type=AAACalRegn01Inin01GroupD_Dummy
      AAACalRegn01Inin05_Dummy: type=AAACalRegn01Inin01_Dummy
      AAACalRegn01Inin05GroupA_Dummy: type=AAACalRegn01Inin01GroupA_Dummy
      AAACalRegn01Inin05GroupC_Dummy: type=AAACalRegn01Inin01GroupC_Dummy
      AAACalRegn01Inin05GroupD_Dummy: type=AAACalRegn01Inin01GroupD_Dummy
      AAACalRegn01Inin06_Dummy: type=AAACalRegn01Inin01_Dummy
      AAACalRegn01Inin06GroupA_Dummy: type=AAACalRegn01Inin01GroupA_Dummy
      AAACalRegn01Inin06GroupC_Dummy: type=AAACalRegn01Inin01GroupC_Dummy
      AAACalRegn01Inin06GroupD_Dummy: type=AAACalRegn01Inin01GroupD_Dummy
      AAACalRegn02Rt{00..03}GroupD_Dummy: type=AAACalRegn02Rt01GroupD_Dummy
      BmwSwFctDi: type=BmwSwFctDi
      CalRegn01Inin00: type=CalRegn01Inin00
      CalRegn01Inin00GroupA: type=CalRegn01Inin00GroupA
      CalRegn01Inin00GroupC: type=CalRegn01Inin00GroupC
      CalRegn01Inin00GroupD: type=CalRegn01Inin00GroupD
      CalRegn01Inin01: type=CalRegn01Inin01
      CalRegn01Inin01GroupA: type=CalRegn01Inin01GroupA
      CalRegn01Inin01GroupC: type=CalRegn01Inin01GroupC
      CalRegn01Inin01GroupD: type=CalRegn01Inin01GroupD
      CalRegn01Inin02: type=CalRegn01Inin02
      CalRegn01Inin02GroupA: type=CalRegn01Inin02GroupA
      CalRegn01Inin02GroupC: type=CalRegn01Inin02GroupC
      CalRegn01Inin02GroupD: type=CalRegn01Inin02GroupD
      CalRegn01Inin03: type=CalRegn01Inin03
      CalRegn01Inin03GroupA: type=CalRegn01Inin03GroupA
      CalRegn01Inin03GroupC: type=CalRegn01Inin03GroupC
      CalRegn01Inin03GroupD: type=CalRegn01Inin03GroupD
      CalRegn01Inin04: type=CalRegn01Inin04
      CalRegn01Inin04GroupA: type=CalRegn01Inin04GroupA
      CalRegn01Inin04GroupC: type=CalRegn01Inin04GroupC
      CalRegn01Inin04GroupD: type=CalRegn01Inin04GroupD
      CalRegn01Inin05: type=CalRegn01Inin05
      CalRegn01Inin05GroupA: type=CalRegn01Inin05GroupA
      CalRegn01Inin05GroupC: type=CalRegn01Inin05GroupC
      CalRegn01Inin05GroupD: type=CalRegn01Inin05GroupD
      CalRegn01Inin06: type=CalRegn01Inin06
      CalRegn01Inin06GroupA: type=CalRegn01Inin06GroupA
      CalRegn01Inin06GroupC: type=CalRegn01Inin06GroupC
      CalRegn01Inin06GroupD: type=CalRegn01Inin06GroupD
      CalRegn02Rt{00..03}GroupD: type=CalRegn02Rt{00..03}GroupD
    connect DiagcMgrProxyAppl10.SetNtcSts10 -> McalErrHndlg.SetNtcSts  # UB:Derived from original system description
    connect NvMProxy.PSProxy_Rte_NvmBlock_DiagcMgr_DiagcMgrApplCrc -> DiagcMgr.DiagcMgrApplCrc
    connect CDD_AdcDiagc.AdcDiagcEndPtrOutp -> CDD_MotCtrlMgr.AdcDiagcEndPtrOutp  # UB:Derived from original system description
    connect CDD_AdcDiagc.AdcDiagcStrtPtrOutp -> CDD_MotCtrlMgr.AdcDiagcStrtPtrOutp  # UB:Derived from original system description
    connect CDD_DmaCfgAndUse.DmaEna2MilliSecToMotCtrlTrf -> CDD_MotCtrlMgr.DmaEna2MilliSecToMotCtrlTrf  # UB:Derived from original system description
    connect CDD_DmaCfgAndUse.DmaWaitForMotCtrlTo2MilliSecTrf -> CDD_MotCtrlMgr.DmaWaitForMotCtrlTo2MilliSecTrf  # UB:Derived from original system description
    connect CDD_MotCtrlMgr.Adc0ScanGroup2Ref1 -> CDD_AdcDiagc.Adc0ScanGroup2Ref1  # UB:Derived from original system description
    connect CDD_MotCtrlMgr.Adc0ScanGroup3Ref0 -> CDD_AdcDiagc.Adc0ScanGroup3Ref0  # UB:Derived from original system description
    connect CDD_MotCtrlMgr.Adc0ScanGroup3Ref1 -> CDD_AdcDiagc.Adc0ScanGroup3Ref1  # UB:Derived from original system description
    connect CDD_MotCtrlMgr.Adc0SelfDiag0 -> CDD_AdcDiagc.Adc0SelfDiag0  # UB:Derived from original system description
    connect CDD_MotCtrlMgr.Adc0SelfDiag2 -> CDD_AdcDiagc.Adc0SelfDiag2  # UB:Derived from original system description
    connect CDD_MotCtrlMgr.Adc0SelfDiag4 -> CDD_AdcDiagc.Adc0SelfDiag4  # UB:Derived from original system description
    connect CDD_MotCtrlMgr.MotAg0ErrReg -> CDD_MotAg0Meas.MotAg0ErrReg  # UB:Derived from original system description
    connect CDD_MotCtrlMgr.MotAg0ParFltCnt -> CDD_MotAg0Meas.MotAg0ParFltCnt  # UB:Derived from original system description
    connect CDD_MotCtrlMgr.MotAg0TurnCntrReg -> CDD_MotAg0Meas.MotAg0TurnCntrReg  # UB:Derived from original system description
    connect CDD_MotCtrlMgr.MotAg0VltgFltCnt -> CDD_MotAg0Meas.MotAg0VltgFltCnt  # UB:Derived from original system description
    connect CDD_MotCtrlMgr.MotAg1ErrReg -> CDD_MotAg1Meas.MotAg1ErrReg  # UB:Derived from original system description
    connect CDD_MotCtrlMgr.MotAg1ParFltCnt -> CDD_MotAg1Meas.MotAg1ParFltCnt  # UB:Derived from original system description
    connect CDD_MotCtrlMgr.MotAg1TurnCntrReg -> CDD_MotAg1Meas.MotAg1TurnCntrReg  # UB:Derived from original system description
    connect CDD_MotCtrlMgr.MotAg1VltgFltCnt -> CDD_MotAg1Meas.MotAg1VltgFltCnt  # UB:Derived from original system description
    connect CDD_MotCtrlMgr.Adc0ScanGroup2Ref0 -> CDD_AdcDiagc.Adc0ScanGroup2Ref0  # UB:Derived from original system description
    connect CDD_MotCtrlMgr.MotCurrAdcVlyA -> CDD_CurrMeas.MotCurrAdcVlyA  # UB:Derived from original system description
    connect CDD_MotCtrlMgr.MotCurrAdcVlyB -> CDD_CurrMeas.MotCurrAdcVlyB  # UB:Derived from original system description
    connect CDD_MotCtrlMgr.MotCurrAdcVlyC -> CDD_CurrMeas.MotCurrAdcVlyC  # UB:Derived from original system description
    connect CDD_MotCtrlMgr.Ntc5DErrCnt -> CDD_CurrMeas.Ntc5DErrCnt  # UB:Derived from original system description
    connect SysStMod.SysSt -> CDD_MotCtrlMgr.SysSt  # UB:Derived from original system description
    connect CDD_NxtrTi.GetRefTmr1MicroSec32bit -> CDD_Bmw5441McuCfg.GetRefTmr1MicroSec32bit  # UB:Derived from original system description
    connect CDD_NxtrTi.GetTiSpan1MicroSec32bit -> CDD_Bmw5441McuCfg.GetTiSpan1MicroSec32bit  # UB:Derived from original system description
    connect CDD_AdcDiagc.Adc0Faild -> CDD_Bmw5441McuCfg.Adc0Faild  # UB:Derived from original system description
    connect CDD_AdcDiagc.Adc1Faild -> CDD_Bmw5441McuCfg.Adc1Faild  # UB:Derived from original system description
    connect CDD_Bmw5441McuCfg.Adc1ScanGroup2Ref1 -> CDD_AdcDiagc.Adc1ScanGroup2Ref1  # UB:Derived from original system description
    connect CDD_Bmw5441McuCfg.Adc1ScanGroup3Ref0 -> CDD_AdcDiagc.Adc1ScanGroup3Ref0  # UB:Derived from original system description
    connect CDD_Bmw5441McuCfg.Adc1ScanGroup3Ref1 -> CDD_AdcDiagc.Adc1ScanGroup3Ref1  # UB:Derived from original system description
    connect CDD_Bmw5441McuCfg.Adc1SelfDiag0 -> CDD_AdcDiagc.Adc1SelfDiag0  # UB:Derived from original system description
    connect CDD_Bmw5441McuCfg.Adc1SelfDiag2 -> CDD_AdcDiagc.Adc1SelfDiag2  # UB:Derived from original system description
    connect CDD_Bmw5441McuCfg.Adc1SelfDiag4 -> CDD_AdcDiagc.Adc1SelfDiag4  # UB:Derived from original system description
    connect CDD_Bmw5441McuCfg.MotCurrAdcVlyAAdcFaild -> CDD_MotCtrlMgr.MotCurrAdcVlyAAdcFaild  # UB:Derived from original system description
    connect CDD_Bmw5441McuCfg.MotCurrAdcVlyBAdcFaild -> CDD_MotCtrlMgr.MotCurrAdcVlyBAdcFaild  # UB:Derived from original system description
    connect CDD_Bmw5441McuCfg.MotCurrAdcVlyCAdcFaild -> CDD_MotCtrlMgr.MotCurrAdcVlyCAdcFaild  # UB:Derived from original system description
    connect CDD_Bmw5441McuCfg.Adc1ScanGroup2Ref0 -> CDD_AdcDiagc.Adc1ScanGroup2Ref0  # UB:Derived from original system description
    connect BattVltg.BrdgVltg -> CDD_MotCtrlMgr.BrdgVltg  # UB:Derived from original system description
    connect EcuTMeas.EcuTFild -> CDD_MotCtrlMgr.EcuTFild  # UB:Derived from original system description
    connect WdgM_Appl10.alive_SE_4ms_Appl10_ChkPt_4ms_Appl10_End -> CDD_ChkPtAppl10.ChkPt_4ms_Appl10_End
    connect WdgM_Appl10.alive_SE_4ms_Appl10_ChkPt_4ms_Appl10_Strt -> CDD_ChkPtAppl10.ChkPt_4ms_Appl10_Strt
    connect WdgM_Appl10.alive_SE_10ms_Appl10_ChkPt_10ms_Appl10_End -> CDD_ChkPtAppl10.ChkPt_10ms_Appl10_End
    connect WdgM_Appl10.alive_SE_10ms_Appl10_ChkPt_10ms_Appl10_Strt -> CDD_ChkPtAppl10.ChkPt_10ms_Appl10_Strt
    connect WdgM_Appl10.alive_SE_100ms_Appl10_ChkPt_100ms_Appl10_End -> CDD_ChkPtAppl10.ChkPt_100ms_Appl10_End
    connect WdgM_Appl10.alive_SE_100ms_Appl10_ChkPt_100ms_Appl10_Strt -> CDD_ChkPtAppl10.ChkPt_100ms_Appl10_Strt
    connect WdgM_Appl10.alive_SE_10msBsw_Appl10_ChkPt_10msBsw_Appl10_End -> CDD_ChkPtAppl10.ChkPt_10msBswAppl10End
    connect WdgM_Appl10.alive_SE_10msBsw_Appl10_ChkPt_10msBsw_Appl10_Strt -> CDD_ChkPtAppl10.ChkPt_10msBswAppl10Strt
    connect BattVltg.BrdgVltg -> CDD_CurrMeas.BrdgVltg  # UB:Derived from original system description
    connect BattVltg.BrdgVltg -> DiagcMgr.BrdgVltg  # UB:Derived from original system description
    connect BattVltgCorrln.BattSwdVltgCorrlnSts -> BattVltg.BattSwdVltgCorrlnSts  # UB:Derived from original system description
    connect CDD_Adc1CfgAndUse.Adc1CfgAndUseAdc1EnaCnvn -> CDD_DmaCfgAndUse.Adc1CfgAndUseAdc1EnaCnvn  # UB:Derived from original system description
    connect CDD_AdcDiagc.AdcDiagcEndPtrOutp -> CDD_Adc1CfgAndUse.AdcDiagcEndPtrOutp  # UB:Derived from original system description
    connect CDD_AdcDiagc.AdcDiagcStrtPtrOutp -> CDD_Adc1CfgAndUse.AdcDiagcStrtPtrOutp  # UB:Derived from original system description
    connect CDD_CurrMeas.CurrMeasWrmIninTestCmpl -> CDD_MotCtrlMgr.CurrMeasWrmIninTestCmpl  # UB:Derived from original system description
    connect CDD_CurrMeas.MotCurrEolCalSt -> CDD_MotCtrlMgr.MotCurrEolCalSt  # UB:Derived from original system description
    connect CDD_CurrMeas.MotCurrEolCalSt -> CDD_TSG31CfgAndUse.MotCurrEolCalSt  # UB:Derived from original system description
    connect CDD_DmaCfgAndUse.MotAg0SnsrCfgDmaStrt -> CDD_MotAg0Meas.MotAg0SnsrCfgDmaStrt  # UB:Derived from original system description
    connect CDD_FlsMem.SwApplCrc -> DiagcMgr.SwApplCrc  # UB:Derived from original system description
    connect CDD_MotAg0Meas.MotAg0SnsrCfgAdr -> CDD_DmaCfgAndUse.MotAg0SnsrCfgAdr  # UB:Derived from original system description
    connect CDD_MotAg1Meas.MotAg1MeclQlfr -> CDD_MotAg0Meas.MotAg1MeclQlfr  # UB:Derived from original system description
    connect CDD_MotAg1Meas.MotAg1TurnCntrQlfr -> CDD_MotAg0Meas.MotAg1TurnCntrQlfr  # UB:Derived from original system description
    connect CDD_NxtrTi.GetRefTmr1MicroSec32bit -> CDD_DmaCfgAndUse.GetRefTmr1MicroSec32bit  # UB:Derived from original system description
    connect CDD_NxtrTi.GetTiSpan1MicroSec32bit -> CDD_DmaCfgAndUse.GetTiSpan1MicroSec32bit  # UB:Derived from original system description
    connect CDD_NxtrTi.GetTiSpan100MicroSec32bit -> CDD_FlsMem.GetTiSpan100MicroSec32bit  # UB:Derived from original system description
    connect CDD_NxtrTi.GetRefTmr100MicroSec32bit -> FltInj.GetRefTmr100MicroSec32bit  # UB:Derived from original system description
    connect CDD_NxtrTi.GetTiSpan100MicroSec32bit -> FltInj.GetTiSpan100MicroSec32bit  # UB:Derived from original system description
    connect CDD_SyncCrc.ResvCrcHwUnit -> CDD_FlsMem.ResvCrcHwUnit  # UB:Derived from original system description
    connect DiagcMgr.ClrDiagcFlgProxy -> DiagcMgrProxyAppl10.ClrDiagcFlgProxy  # UB:Derived from original system description
    connect DiagcMgr.DiagcMgrIninCore -> DiagcMgrProxyAppl10.DiagcMgrIninCore  # UB:Derived from original system description
    connect DiagcMgr.GetNtcActvCore -> DiagcMgrProxyAppl10.GetNtcActvCore  # UB:Derived from original system description
    connect DiagcMgr.GetNtcQlfrStsCore -> DiagcMgrProxyAppl10.GetNtcQlfrStsCore  # UB:Derived from original system description
    connect DiagcMgr.GetNtcStsCore -> DiagcMgrProxyAppl10.GetNtcStsCore  # UB:Derived from original system description
    connect DiagcMgr.SetNtcStsCore -> DiagcMgrProxyAppl10.SetNtcStsCore  # UB:Derived from original system description
    connect DiagcMgr.CnvSnpshtData_f32 -> EcuTMeas.CnvSnpshtData_f32  # UB:Derived from original system description
    connect DiagcMgr.CnvSnpshtData_logl -> EcuTMeas.CnvSnpshtData_logl  # UB:Derived from original system description
    connect DiagcMgrProxyAppl10.SetNtcSts10 -> BattVltgCorrln.SetNtcSts  # UB:Derived from original system description
    connect DiagcMgrProxyAppl10.GetNtcQlfrSts10 -> CDD_AdcDiagc.GetNtcQlfrSts  # UB:Derived from original system description
    connect DiagcMgrProxyAppl10.SetNtcSts10 -> CDD_AdcDiagc.SetNtcSts  # UB:Derived from original system description
    connect DiagcMgrProxyAppl10.SetNtcSts10 -> CDD_CurrMeas.SetNtcSts  # UB:Derived from original system description
    connect DiagcMgrProxyAppl10.SetNtcSts10 -> CDD_ExcpnHndlg.SetNtcSts  # UB:Derived from original system description
    connect DiagcMgrProxyAppl10.SetNtcSts10 -> CDD_FlsMem.SetNtcSts  # UB:Derived from original system description
    connect DiagcMgrProxyAppl10.GetNtcQlfrSts10 -> CDD_MotAg0Meas.GetNtcQlfrSts  # UB:Derived from original system description
    connect DiagcMgrProxyAppl10.GetNtcQlfrSts10 -> CDD_MotAg1Meas.GetNtcQlfrSts  # UB:Derived from original system description
    connect DiagcMgrProxyAppl10.SetNtcSts10 -> CDD_NvMProxy.SetNtcSts  # UB:Derived from original system description
    connect DiagcMgrProxyAppl10.SetNtcSts10 -> CDD_NxtrTi.SetNtcSts  # UB:Derived from original system description
    connect DiagcMgrProxyAppl10.SetNtcSts10 -> CDD_RamMem.SetNtcSts  # UB:Derived from original system description
    connect DiagcMgrProxyAppl10.GetDiagcDataAppl10 -> DiagcMgr.GetDiagcDataAppl10  # UB:Derived from original system description
    connect DiagcMgrProxyAppl10.GetNtcDebCntrAppl10 -> DiagcMgr.GetNtcDebCntrAppl10  # UB:Derived from original system description
    connect DiagcMgrProxyAppl10.GetNtcInfoAppl10 -> DiagcMgr.GetNtcInfoAppl10  # UB:Derived from original system description
    connect DiagcMgrProxyAppl10.GetNtcQlfrSts10 -> MotAgCorrln.GetNtcQlfrSts  # UB:Derived from original system description
    connect DiagcMgrProxyAppl10.SetNtcSts10 -> MotAgCorrln.SetNtcSts  # UB:Derived from original system description
    connect DiagcMgrProxyAppl10.SetNtcSts10 -> NxtrMath.SetNtcSts  # UB:Derived from original system description
    connect EcuTMeas.EcuTFild -> DiagcMgr.EcuTFild  # UB:Derived from original system description
    connect FltInj.FltInj_f32 -> CDD_CurrMeas.FltInj_f32  # UB:Derived from original system description
    connect FltInj.FltInj_u08 -> CDD_CurrMeas.FltInj_u08  # UB:Derived from original system description
    connect FltInj.FltInj_u08 -> MotAgCorrln.FltInj_u08  # UB:Derived from original system description
    connect McuErrInj.ReadErrInjReg -> CDD_AdcDiagc.ReadErrInjReg  # UB:Derived from original system description
    connect McuErrInj.StrtErrInjCntr -> CDD_AdcDiagc.StrtErrInjCntr  # UB:Derived from original system description
    connect McuErrInj.ClrErrInjReg -> CDD_NxtrTi.ClrErrInjReg  # UB:Derived from original system description
    connect McuErrInj.ReadErrInjReg -> CDD_NxtrTi.ReadErrInjReg  # UB:Derived from original system description
    connect SysStMod.SysSt -> BattVltgCorrln.SysSt  # UB:Derived from original system description
    connect SysStMod.SysSt -> CDD_TSG31CfgAndUse.SysSt  # UB:Derived from original system description
    connect SysStMod.SysSt -> DiagcMgr.SysSt  # UB:Derived from original system description
    connect CDD_CurrMeas.CurrMeasEolGainReq -> CmnMfgSrv.CurrMeasEolGainReq  # UB:Derived from original system description
    connect CDD_CurrMeas.CurrMeasEolGainStsReq -> CmnMfgSrv.CurrMeasEolGainStReq  # UB:Derived from original system description
    connect CDD_CurrMeas.CurrMeasEolOffsReq -> CmnMfgSrv.CurrMeasEolOffsReq  # UB:Derived from original system description
    connect CDD_CurrMeas.CurrMeasEolOffsStsReq -> CmnMfgSrv.CurrMeasEolOffsStReq  # UB:Derived from original system description
    connect DiagcMgrProxyAppl10.GetNtcSts10 -> CmnMfgSrv.GetNtcSts  # UB:Derived from original system description
    connect NxtrSwIds.NxtrSwIdsPsrInfoRd -> CmnMfgSrv.NxtrSwIdsPsrInfoRd  # UB:Derived from original system description
    connect NxtrSwIds.NxtrSwIdsSwBuildDateTiRd -> CmnMfgSrv.NxtrSwIdsSwBuildDateTiRd  # UB:Derived from original system description
    connect NxtrSwIds.NxtrSwIdsSwRelInfoRd -> CmnMfgSrv.NxtrSwIdsSwRelInfoRd  # UB:Derived from original system description
    connect NxtrSwIds.NxtrSwIdsSwRelNrRd -> CmnMfgSrv.NxtrSwIdsSwRelNrRd  # UB:Derived from original system description
    connect NxtrSwIds.NxtrSwIdsSwRelVerRd -> CmnMfgSrv.NxtrSwIdsSwRelVerRd  # UB:Derived from original system description
    connect CDD_CurrMeas.CurrMeasWrmIninTestCmpl -> PwrUpSeq.CurrMeasWrmIninTestCmpl  # UB:Derived from original system description
    connect CDD_EcmOutpAndDiagc.CtrlErrOut -> TmplMonr.CtrlErrOut  # UB:Derived from original system description
    connect CDD_FlsMem.CodFlsCrcChkCmpl -> PwrUpSeq.CodFlsCrcChkCmpl  # UB:Derived from original system description
    connect CDD_NxtrTi.GetRefTmr1MicroSec32bit -> TmplMonr.GetRefTmr1MicroSec32bit  # UB:Derived from original system description
    connect CDD_NxtrTi.GetTiSpan1MicroSec32bit -> TmplMonr.GetTiSpan1MicroSec32bit  # UB:Derived from original system description
    connect CDD_Tauj0CfgAndUse.PhaOnTiMeasdA -> GateDrv0Ctrl.PhaOnTiMeasdA  # UB:Derived from original system description
    connect CDD_Tauj0CfgAndUse.PhaOnTiMeasdB -> GateDrv0Ctrl.PhaOnTiMeasdB  # UB:Derived from original system description
    connect CDD_Tauj0CfgAndUse.PhaOnTiMeasdC -> GateDrv0Ctrl.PhaOnTiMeasdC  # UB:Derived from original system description
    connect DiagcMgrProxyAppl10.SetNtcSts10 -> TmplMonr.SetNtcSts  # UB:Derived from original system description
    connect GateDrv0Ctrl.MotDrvr0IninTestCmpl -> PwrUpSeq.MotDrvr0IninTestCmpl  # UB:Derived from original system description
    connect GateDrv0Ctrl.DiagcStsIvtr1Inactv -> ShtdwnMech.DiagcStsIvtr1Inactv  # UB:Derived from original system description
    connect PwrDiscnct.PwrDiscnctATestCmpl -> PwrUpSeq.PwrDiscnctATestCmpl  # UB:Derived from original system description
    connect PwrDiscnct.PwrDiscnctBTestCmpl -> PwrUpSeq.PwrDiscnctBTestCmpl  # UB:Derived from original system description
    connect PwrUpSeq.StrtUpSt -> BattVltgCorrln.StrtUpSt  # UB:Derived from original system description
    connect PwrUpSeq.StrtUpSt -> CDD_CurrMeas.StrtUpSt  # UB:Derived from original system description
    connect PwrUpSeq.StrtUpSt -> GateDrv0Ctrl.StrtUpSt  # UB:Derived from original system description
    connect PwrUpSeq.StrtUpSt -> PwrDiscnct.StrtUpSt  # UB:Derived from original system description
    connect PwrUpSeq.StrtUpSt -> ShtdwnMech.StrtUpSt  # UB:Derived from original system description
    connect PwrUpSeq.StrtUpSt -> SysStMod.StrtUpSt  # UB:Derived from original system description
    connect PwrUpSeq.SysStWrmIninCmpl -> SysStMod.SysStWrmIninCmpl  # UB:Derived from original system description
    connect PwrUpSeq.StrtUpSt -> TmplMonr.StrtUpSt  # UB:Derived from original system description
    connect SysStMod.SysSt -> PwrSply.SysSt  # UB:Derived from original system description
    connect SysStMod.SysSt -> PwrUpSeq.SysSt  # UB:Derived from original system description
    connect SysStMod.SysSt -> TmplMonr.SysSt  # UB:Derived from original system description
    connect TmplMonr.TmplMonrIninTestCmpl -> PwrUpSeq.TmplMonIninTestCmpl  # UB:Derived from original system description
    connect CDD_Bmw5441McuCfg.BattVltgSwd1 -> BattVltg.BattVltgSwd1  # UB:Derived from original system description
    connect CDD_Bmw5441McuCfg.BattVltgAdcFaild -> BattVltgCorrln.BattVltgAdcFaild  # UB:Derived from original system description
    connect CDD_Bmw5441McuCfg.BattVltgSwd1 -> BattVltgCorrln.BattVltgSwd1  # UB:Derived from original system description
    connect CDD_Bmw5441McuCfg.BattVltgSwd1AdcFaild -> BattVltgCorrln.BattVltgSwd1AdcFaild  # UB:Derived from original system description
    connect CDD_Bmw5441McuCfg.EcuT -> EcuTMeas.EcuT  # UB:Derived from original system description
    connect CDD_Bmw5441McuCfg.EcuTAdcFaild -> EcuTMeas.EcuTAdcFaild  # UB:Derived from original system description
    connect CDD_Bmw5441McuCfg.BattVltgSwd1 -> PwrDiscnct.BattVltgSwd1  # UB:Derived from original system description
    connect CDD_MotCtrlMgr.MotAgCumvAlgndMrfRev -> CDD_MotAgCmp.MotAgCumvAlgndMrfRev  # UB:Derived from original system description
    connect CDD_MotCtrlMgr.MotAgCumvInid -> CDD_MotAgCmp.MotAgCumvInid  # UB:Derived from original system description
    connect CDD_MotCtrlMgr.PhaOnTiSumA -> GateDrv0Ctrl.PhaOnTiSumA  # UB:Derived from original system description
    connect CDD_MotCtrlMgr.PhaOnTiSumB -> GateDrv0Ctrl.PhaOnTiSumB  # UB:Derived from original system description
    connect CDD_MotCtrlMgr.PhaOnTiSumC -> GateDrv0Ctrl.PhaOnTiSumC  # UB:Derived from original system description
    connect DiagcMgr.SysStFltOutpReqDi -> SysStMod.SysStFltOutpReqDi  # UB:Derived from original system description
    connect DiagcMgrProxyAppl10.GetNtcQlfrSts10 -> GateDrv0Ctrl.GetNtcQlfrSts  # UB:Derived from original system description
    connect DiagcMgrProxyAppl10.SetNtcSts10 -> GateDrv0Ctrl.SetNtcSts  # UB:Derived from original system description
    connect DiagcMgrProxyAppl10.SetNtcStsAndSnpshtData10 -> GateDrv0Ctrl.SetNtcStsAndSnpshtData  # UB:Derived from original system description
    connect DiagcMgrProxyAppl10.GetNtcQlfrSts10 -> PwrDiscnct.GetNtcQlfrSts  # UB:Derived from original system description
    connect DiagcMgrProxyAppl10.SetNtcSts10 -> PwrDiscnct.SetNtcSts  # UB:Derived from original system description
    connect GateDrv0Ctrl.DiagcStsIvtr1Inactv -> BattVltgCorrln.DiagcStsIvtr1Inactv  # UB:Derived from original system description
    connect GateDrv0Ctrl.DiagcStsIvtr1Inactv -> CDD_CurrMeas.DiagcStsIvtr1Inactv  # UB:Derived from original system description
    connect GateDrv0Ctrl.DiagcStsIvtr1Inactv -> CDD_MotCtrlMgr.DiagcStsIvtr1Inactv  # UB:Derived from original system description
    connect GateDrv0Ctrl.IvtrFetFltPha -> CDD_MotCtrlMgr.IvtrFetFltPha  # UB:Derived from original system description
    connect GateDrv0Ctrl.IvtrFetFltTyp -> CDD_MotCtrlMgr.IvtrFetFltTyp  # UB:Derived from original system description
    connect PolarityCfg.MotAgMecl0Polarity -> CDD_MotAg0Meas.MotAg0Polarity  # UB:Derived from original system description
    connect PolarityCfg.MotAgMecl1Polarity -> CDD_MotAg1Meas.MotAg1Polarity  # UB:Derived from original system description
    connect PolarityCfg.AssiMechPolarity -> CDD_MotAgCmp.AssiMechPolarity  # UB:Derived from original system description
    connect PolarityCfg.MotElecMeclPolarity -> CDD_MotCtrlMgr.MotElecMeclPolarity  # UB:Derived from original system description
    connect PolarityCfg.MotElecMeclPolarity -> CDD_SinVltgGenn.MotElecMeclPolarity  # UB:Derived from original system description
    connect SysStMod.SysSt -> CDD_CurrMeas.SysSt  # UB:Derived from original system description
    connect SysStMod.SysSt -> GateDrv0Ctrl.SysSt  # UB:Derived from original system description
    connect CDD_HwTq4Meas.HwTq4AutTrim -> CmnMfgSrv.HwTq4AutTrim  # UB:Derived from original system description
    connect CDD_HwTq4Meas.HwTq4ClrSnsrSca -> CmnMfgSrv.HwTq4ClrSnsrSca  # UB:Derived from original system description
    connect CDD_HwTq4Meas.HwTq4ClrTrim -> CmnMfgSrv.HwTq4ClrTrim  # UB:Derived from original system description
    connect CDD_HwTq4Meas.HwTq4ReadSnsrSca -> CmnMfgSrv.HwTq4ReadSnsrSca  # UB:Derived from original system description
    connect CDD_HwTq4Meas.HwTq4ReadTrim -> CmnMfgSrv.HwTq4ReadTrim  # UB:Derived from original system description
    connect CDD_HwTq4Meas.HwTq4SnsrScaPrfmdSts -> CmnMfgSrv.HwTq4SnsrScaPrfmdSts  # UB:Derived from original system description
    connect CDD_HwTq4Meas.HwTq4TrimPrfmdSts -> CmnMfgSrv.HwTq4TrimPrfmdSts  # UB:Derived from original system description
    connect CDD_HwTq4Meas.HwTq4WrSnsrSca -> CmnMfgSrv.HwTq4WrSnsrSca  # UB:Derived from original system description
    connect CDD_HwTq4Meas.HwTq4WrTrim -> CmnMfgSrv.HwTq4WrTrim  # UB:Derived from original system description
    connect CDD_HwTq4Meas.HwTq4 -> HwTqArbn.HwTqA  # UB:Derived from original system description
    connect CDD_HwTq4Meas.HwTq4Qlfr -> HwTqArbn.HwTqAQlfr  # UB:Derived from original system description
    connect CDD_HwTq4Meas.HwTq4RollgCntr -> HwTqArbn.HwTqARollgCntr  # UB:Derived from original system description
    connect CDD_HwTq4Meas.HwTq4 -> HwTqCorrln.HwTqA  # UB:Derived from original system description
    connect CDD_HwTq4Meas.HwTq4Qlfr -> HwTqCorrln.HwTqAQlfr  # UB:Derived from original system description
    connect CDD_HwTq4Meas.HwTq4RollgCntr -> HwTqCorrln.HwTqARollgCntr  # UB:Derived from original system description
    connect CDD_HwTq5Meas.HwTq5AutTrim -> CmnMfgSrv.HwTq5AutTrim  # UB:Derived from original system description
    connect CDD_HwTq5Meas.HwTq5ClrSnsrSca -> CmnMfgSrv.HwTq5ClrSnsrSca  # UB:Derived from original system description
    connect CDD_HwTq5Meas.HwTq5ClrTrim -> CmnMfgSrv.HwTq5ClrTrim  # UB:Derived from original system description
    connect CDD_HwTq5Meas.HwTq5ReadSnsrSca -> CmnMfgSrv.HwTq5ReadSnsrSca  # UB:Derived from original system description
    connect CDD_HwTq5Meas.HwTq5ReadTrim -> CmnMfgSrv.HwTq5ReadTrim  # UB:Derived from original system description
    connect CDD_HwTq5Meas.HwTq5SnsrScaPrfmdSts -> CmnMfgSrv.HwTq5SnsrScaPrfmdSts  # UB:Derived from original system description
    connect CDD_HwTq5Meas.HwTq5TrimPrfmdSts -> CmnMfgSrv.HwTq5TrimPrfmdSts  # UB:Derived from original system description
    connect CDD_HwTq5Meas.HwTq5WrSnsrSca -> CmnMfgSrv.HwTq5WrSnsrSca  # UB:Derived from original system description
    connect CDD_HwTq5Meas.HwTq5WrTrim -> CmnMfgSrv.HwTq5WrTrim  # UB:Derived from original system description
    connect CDD_HwTq5Meas.HwTq5 -> HwTqArbn.HwTqB  # UB:Derived from original system description
    connect CDD_HwTq5Meas.HwTq5Qlfr -> HwTqArbn.HwTqBQlfr  # UB:Derived from original system description
    connect CDD_HwTq5Meas.HwTq5RollgCntr -> HwTqArbn.HwTqBRollgCntr  # UB:Derived from original system description
    connect CDD_HwTq5Meas.HwTq5 -> HwTqCorrln.HwTqB  # UB:Derived from original system description
    connect CDD_HwTq5Meas.HwTq5Qlfr -> HwTqCorrln.HwTqBQlfr  # UB:Derived from original system description
    connect CDD_HwTq5Meas.HwTq5RollgCntr -> HwTqCorrln.HwTqBRollgCntr  # UB:Derived from original system description
    connect DiagcMgrProxyAppl10.GetNtcQlfrSts10 -> CDD_HwTq4Meas.GetNtcQlfrSts  # UB:Derived from original system description
    connect DiagcMgrProxyAppl10.SetNtcSts10 -> CDD_HwTq4Meas.SetNtcSts  # UB:Derived from original system description
    connect DiagcMgrProxyAppl10.GetNtcQlfrSts10 -> CDD_HwTq5Meas.GetNtcQlfrSts  # UB:Derived from original system description
    connect DiagcMgrProxyAppl10.SetNtcSts10 -> CDD_HwTq5Meas.SetNtcSts  # UB:Derived from original system description
    connect DiagcMgrProxyAppl10.GetNtcQlfrSts10 -> HwTqCorrln.GetNtcQlfrSts  # UB:Derived from original system description
    connect DiagcMgrProxyAppl10.SetNtcSts10 -> HwTqCorrln.SetNtcSts  # UB:Derived from original system description
    connect FltInj.FltInj_u08 -> HwTqCorrln.FltInj_u08  # UB:Derived from original system description
    connect HwTqCorrln.HwTqCorrlnSts -> HwTqArbn.HwTqCorrlnSts  # UB:Derived from original system description
    connect CDD_MotCtrlMgr.HwTq4RawAdc -> CDD_HwTq4Meas.HwTq4RawAdc  # UB:Derived from original system description
    connect CDD_MotCtrlMgr.HwTq5RawAdc -> CDD_HwTq5Meas.HwTq5RawAdc  # UB:Derived from original system description
    connect NvMProxy.PSProxy_Rte_NvmBlock_CDD_HwTq4Meas_HwTq4Offs_MirrorBlock -> CDD_HwTq4Meas.HwTq4Offs
    connect NvMProxy.PSProxy_Rte_NvmBlock_CDD_HwTq4Meas_HwTq4Sca_MirrorBlock -> CDD_HwTq4Meas.HwTq4Sca
    connect NvMProxy.PSProxy_Rte_NvmBlock_CDD_HwTq5Meas_HwTq5Offs_MirrorBlock -> CDD_HwTq5Meas.HwTq5Offs
    connect NvMProxy.PSProxy_Rte_NvmBlock_CDD_HwTq5Meas_HwTq5Sca_MirrorBlock -> CDD_HwTq5Meas.HwTq5Sca
    connect NvMProxy.PSProxy_Rte_NvmBlock_CmnMfgSrv_CcaHwPartNr -> NxtrSwIds.NvmCcaHwPartNr
    connect NvMProxy.PSProxy_Rte_NvmBlock_CmnMfgSrv_CcaSerlNr -> NxtrSwIds.NvmCcaSerlNr
    connect NvMProxy.PSProxy_Rte_NvmBlock_CmnMfgSrv_DiRestore -> NxtrSwIds.NvmDiRestore
    connect NvMProxy.PSProxy_Rte_NvmBlock_CmnMfgSrv_EpsSysSerlNr -> NxtrSwIds.NvmEpsSysSerlNr
    connect NvMProxy.PSProxy_Rte_NvmBlock_CmnMfgSrv_IgnCntr -> NxtrSwIds.NvmIgnCntr
    connect NvMProxy.PSProxy_Rte_NvmBlock_CmnMfgSrv_NxtrMfgEnaCntr -> NxtrSwIds.NvmMfgEnaCntr
    connect NvMProxy.PSProxy_Rte_NvmBlock_CmnMfgSrv_MfgTmpBuf{0..4} -> NxtrSwIds.NvmMfgTmpBuf{0..4}
    connect NvMProxy.PSProxy_Rte_NvmBlock_CDD_MotAg1Meas_MotAg1CoeffTbl -> CDD_MotAg1Meas.MotAg1CoeffTbl
    connect NvMProxy.PSProxy_Rte_NvmBlock_CDD_MotAg0Meas_MotAg0CoeffTbl -> CDD_MotAg0Meas.MotAg0CoeffTbl
    connect NvMProxy.PSProxy_Rte_NvmBlock_CmnMfgSrv_SeedKey -> CmnMfgSrv.NvmSeedKey
    connect PolarityCfg.HwTq4Polarity -> CDD_HwTq4Meas.HwTq4Polarity  # UB:Derived from original system description
    connect PolarityCfg.HwTq5Polarity -> CDD_HwTq5Meas.HwTq5Polarity  # UB:Derived from original system description
    connect CDD_Bmw5441McuCfg.HwTq4RawAdcAdcFaild -> CDD_HwTq4Meas.HwTq4RawAdcAdcFaild  # UB:Derived from original system description
    connect CDD_Bmw5441McuCfg.HwTq5RawAdcAdcFaild -> CDD_HwTq5Meas.HwTq5RawAdcAdcFaild  # UB:Derived from original system description
    connect BattVltg.BrdgVltg -> CmnMfgSrv.BrdgVltg  # UB:Derived from original system description
    connect BattVltg.BrdgVltg -> ElecPwrCns.BrdgVltg  # UB:Derived from original system description
    connect BattVltg.BrdgVltg -> MotRefMdl.BrdgVltg  # UB:Derived from original system description
    connect BattVltg.BrdgVltg -> PwrLimr.BrdgVltg  # UB:Derived from original system description
    connect CDD_CurrMeas.MotCurrEolCalSt -> MotCurrRegCfg.MotCurrEolCalSt  # UB:Derived from original system description
    connect CDD_MotAgCmp.MotAgCmpBackEmfRead -> CmnMfgSrv.MotAgCmpBackEmfRead  # UB:Derived from original system description
    connect CDD_MotAgCmp.MotAgCmpBackEmfWr -> CmnMfgSrv.MotAgCmpBackEmfWr  # UB:Derived from original system description
    connect CDD_MotAgCmp.MotAgCumvAlgndMrf -> CmnMfgSrv.MotAgCumvAlgndMrf  # UB:Derived from original system description
    connect CDD_MotAgCmp.MotAgCumvAlgndMrf -> MotQuadDetn.MotAgCumvAlgndMrf  # UB:Derived from original system description
    connect CDD_MotCtrlMgr.MotAgBuf -> CDD_MotVel.MotAgBuf  # UB:Derived from original system description
    connect CDD_MotCtrlMgr.MotAgBufIdx -> CDD_MotVel.MotAgBufIdx  # UB:Derived from original system description
    connect CDD_MotCtrlMgr.MotAgTiBuf -> CDD_MotVel.MotAgTiBuf  # UB:Derived from original system description
    connect CDD_MotCtrlMgr.MotAg0Mecl -> CmnMfgSrv.MotAg0Mecl  # UB:Derived from original system description
    connect CDD_MotCtrlMgr.MotAg1Mecl -> CmnMfgSrv.MotAg1Mecl  # UB:Derived from original system description
    connect CDD_MotVel.MotVelMrf -> CDD_CurrMeas.MotVelMrf  # UB:Derived from original system description
    connect CDD_MotVel.MotVelMrf -> CDD_MotCtrlMgr.MotVelMrf  # UB:Derived from original system description
    connect CDD_MotVel.MotVelMrf -> CmnMfgSrv.MotVelMrf  # UB:Derived from original system description
    connect CDD_MotVel.MotVelCrf -> DutyCycThermProtn.MotVelCrf  # UB:Derived from original system description
    connect CDD_MotVel.MotVelCrf -> HiLoadStallLimr.MotVelCrf  # UB:Derived from original system description
    connect CDD_MotVel.MotVelMrf -> MotCurrRegCfg.MotVelMrf  # UB:Derived from original system description
    connect CDD_MotVel.MotVelMrf -> MotRefMdl.MotVelMrf  # UB:Derived from original system description
    connect CDD_MotVel.MotVelMrf -> PwrLimr.MotVelMrf  # UB:Derived from original system description
    connect CDD_NxtrTi.GetRefTmr100MicroSec32bit -> PwrLimr.GetRefTmr100MicroSec32bit  # UB:Derived from original system description
    connect CDD_NxtrTi.GetTiSpan100MicroSec32bit -> PwrLimr.GetTiSpan100MicroSec32bit  # UB:Derived from original system description
    connect CmnMfgSrv.IgnCntr -> DiagcMgr.IgnCntr  # UB:Derived from original system description
    connect CmnMfgSrv.MfgDiagcInhb -> DiagcMgr.MfgDiagcInhb  # UB:Derived from original system description
    connect CmnMfgSrv.MfgEnaSt -> DiagcMgr.MfgEnaSt  # UB:Derived from original system description
    connect CmnMfgSrv.DutyCycThermProtnDi -> DutyCycThermProtn.DutyCycThermProtnDi  # UB:Derived from original system description
    connect CmnMfgSrv.StallMotTqLimDi -> HiLoadStallLimr.StallMotTqLimDi  # UB:Derived from original system description
    connect CmnMfgSrv.SysStImdtTranReqOff -> SysStMod.SysStImdtTranReqOff  # UB:Derived from original system description
    connect CmnMfgSrv.AssiMechTEstimnDi -> TEstimn.AssiMechTEstimnDi  # UB:Derived from original system description
    connect DiagcMgr.ClrAllDiagc -> CmnMfgSrv.ClrAllDiagc  # UB:Derived from original system description
    connect DiagcMgr.ClrSnpshtData -> CmnMfgSrv.ClrSnpshtData  # UB:Derived from original system description
    connect DiagcMgr.ReadNtcFltAry -> CmnMfgSrv.ReadNtcFltAry  # UB:Derived from original system description
    connect DiagcMgr.ReadNtcInfoAndDebCntr -> CmnMfgSrv.ReadNtcInfoAndDebCntr  # UB:Derived from original system description
    connect EcuTMeas.EcuTFild -> CmnMfgSrv.EcuTFild  # UB:Derived from original system description
    connect EcuTMeas.EcuTFild -> DutyCycThermProtn.EcuTFild  # UB:Derived from original system description
    connect EcuTMeas.EcuTFild -> TEstimn.EcuTFild  # UB:Derived from original system description
    connect McuErrInj.UpdErrInjReg -> CmnMfgSrv.UpdErrInjReg  # UB:Derived from original system description
    connect MotAgCorrln.MotAgMeclIdptSig -> CDD_MotVel.MotAgMeclIdptSig  # UB:Derived from original system description
    connect MotCtrlPrmEstimn.MotInduDaxEstimdIvs -> CDD_MotCtrlMgr.MotInduDaxEstimdIvs  # UB:Derived from original system description
    connect MotCtrlPrmEstimn.MotInduQaxEstimdIvs -> CDD_MotCtrlMgr.MotInduQaxEstimdIvs  # UB:Derived from original system description
    connect MotCtrlPrmEstimn.MotREstimd -> CDD_MotCtrlMgr.MotREstimd  # UB:Derived from original system description
    connect MotCtrlPrmEstimn.GetMotPrmNomEol -> CmnMfgSrv.GetMotPrmNomEol  # UB:Derived from original system description
    connect MotCtrlPrmEstimn.SetMotPrmNomEol -> CmnMfgSrv.SetMotPrmNomEol  # UB:Derived from original system description
    connect MotCtrlPrmEstimn.MotInduDaxEstimd -> MotCurrRegCfg.MotInduDaxEstimd  # UB:Derived from original system description
    connect MotCtrlPrmEstimn.MotInduQaxEstimd -> MotCurrRegCfg.MotInduQaxEstimd  # UB:Derived from original system description
    connect MotCtrlPrmEstimn.MotREstimd -> MotCurrRegCfg.MotREstimd  # UB:Derived from original system description
    connect MotCtrlPrmEstimn.MotBackEmfConEstimd -> MotRefMdl.MotBackEmfConEstimd  # UB:Derived from original system description
    connect MotCtrlPrmEstimn.MotInduDaxEstimd -> MotRefMdl.MotInduDaxEstimd  # UB:Derived from original system description
    connect MotCtrlPrmEstimn.MotInduQaxEstimd -> MotRefMdl.MotInduQaxEstimd  # UB:Derived from original system description
    connect MotCtrlPrmEstimn.MotBackEmfConEstimd -> PwrLimr.MotBackEmfConEstimd  # UB:Derived from original system description
    connect MotCurrPeakEstimn.MotCurrPeakEstimd -> DutyCycThermProtn.MotCurrPeakEstimd  # UB:Derived from original system description
    connect MotCurrPeakEstimn.MotCurrPeakEstimdFild -> DutyCycThermProtn.MotCurrPeakEstimdFild  # UB:Derived from original system description
    connect MotCurrPeakEstimn.MotCurrPeakEstimd -> TEstimn.MotCurrPeakEstimd  # UB:Derived from original system description
    connect MotCurrRegCfg.MotAgElecDly -> CDD_MotCtrlMgr.MotAgElecDly  # UB:Derived from original system description
    connect MotCurrRegCfg.MotDampgDax -> CDD_MotCtrlMgr.MotDampgDax  # UB:Derived from original system description
    connect MotCurrRegCfg.MotDampgQax -> CDD_MotCtrlMgr.MotDampgQax  # UB:Derived from original system description
    connect MotCurrRegCfg.MotIntglGainDax -> CDD_MotCtrlMgr.MotIntglGainDax  # UB:Derived from original system description
    connect MotCurrRegCfg.MotIntglGainQax -> CDD_MotCtrlMgr.MotIntglGainQax  # UB:Derived from original system description
    connect MotCurrRegCfg.MotPropGainDax -> CDD_MotCtrlMgr.MotPropGainDax  # UB:Derived from original system description
    connect MotCurrRegCfg.MotPropGainQax -> CDD_MotCtrlMgr.MotPropGainQax  # UB:Derived from original system description
    connect MotQuadDetn.MotQuad -> MotRefMdl.MotQuad  # UB:Derived from original system description
    connect MotRefMdl.MotBackEmfVltg -> CDD_MotCtrlMgr.MotBackEmfVltg  # UB:Derived from original system description
    connect MotRefMdl.MotCurrDaxCmd -> CDD_MotCtrlMgr.MotCurrDaxCmd  # UB:Derived from original system description
    connect MotRefMdl.MotCurrDaxMax -> CDD_MotCtrlMgr.MotCurrDaxMax  # UB:Derived from original system description
    connect MotRefMdl.MotCurrQaxCmd -> CDD_MotCtrlMgr.MotCurrQaxCmd  # UB:Derived from original system description
    connect MotRefMdl.MotReacncDax -> CDD_MotCtrlMgr.MotReacncDax  # UB:Derived from original system description
    connect MotRefMdl.MotReacncQax -> CDD_MotCtrlMgr.MotReacncQax  # UB:Derived from original system description
    connect MotRefMdl.MotVltgDaxFf -> CDD_MotCtrlMgr.MotVltgDaxFf  # UB:Derived from original system description
    connect MotRefMdl.MotVltgQaxFf -> CDD_MotCtrlMgr.MotVltgQaxFf  # UB:Derived from original system description
    connect MotRefMdl.MotCurrDaxCmd -> ElecPwrCns.MotCurrDaxCmd  # UB:Derived from original system description
    connect MotRefMdl.MotCurrQaxCmd -> ElecPwrCns.MotCurrQaxCmd  # UB:Derived from original system description
    connect MotRefMdl.MotCurrDaxCmd -> MotCtrlPrmEstimn.MotCurrDaxCmd  # UB:Derived from original system description
    connect MotRefMdl.MotCurrQaxCmd -> MotCtrlPrmEstimn.MotCurrQaxCmd  # UB:Derived from original system description
    connect MotRefMdl.MotCurrDaxCmd -> MotCurrPeakEstimn.MotCurrDaxCmd  # UB:Derived from original system description
    connect MotRefMdl.MotCurrQaxCmd -> MotCurrPeakEstimn.MotCurrQaxCmd  # UB:Derived from original system description
    connect PolarityCfg.AssiMechPolarity -> CDD_MotVel.AssiMechPolarity  # UB:Derived from original system description
    connect PolarityCfg.PolarityCfgRead -> CmnMfgSrv.PolarityCfgRead  # UB:Derived from original system description
    connect PolarityCfg.PolarityCfgWr -> CmnMfgSrv.PolarityCfgWr  # UB:Derived from original system description
    connect SysStMod.SysSt -> CmnMfgSrv.SysSt  # UB:Derived from original system description
    connect TEstimn.MotFetT -> DutyCycThermProtn.MotFetT  # UB:Derived from original system description
    connect TEstimn.MotMagT -> DutyCycThermProtn.MotMagT  # UB:Derived from original system description
    connect TEstimn.MotWidgT -> DutyCycThermProtn.MotWidgT  # UB:Derived from original system description
    connect TEstimn.MotFetT -> MotCtrlPrmEstimn.MotFetT  # UB:Derived from original system description
    connect TEstimn.MotMagT -> MotCtrlPrmEstimn.MotMagT  # UB:Derived from original system description
    connect TEstimn.MotWidgT -> MotCtrlPrmEstimn.MotWidgT  # UB:Derived from original system description
    connect IoHwAb.SetFctGpioPhaALowrCmd -> CDD_TSG31CfgAndUse.IoHwAb_SetFctGpioPhaALowrCmd  # UB:Derived from original system description
    connect IoHwAb.SetFctGpioPhaAUpprCmd -> CDD_TSG31CfgAndUse.IoHwAb_SetFctGpioPhaAUpprCmd  # UB:Derived from original system description
    connect IoHwAb.SetFctGpioPhaBLowrCmd -> CDD_TSG31CfgAndUse.IoHwAb_SetFctGpioPhaBLowrCmd  # UB:Derived from original system description
    connect IoHwAb.SetFctGpioPhaBUpprCmd -> CDD_TSG31CfgAndUse.IoHwAb_SetFctGpioPhaBUpprCmd  # UB:Derived from original system description
    connect IoHwAb.SetFctGpioPhaCLowrCmd -> CDD_TSG31CfgAndUse.IoHwAb_SetFctGpioPhaCLowrCmd  # UB:Derived from original system description
    connect IoHwAb.SetFctGpioPhaCUpprCmd -> CDD_TSG31CfgAndUse.IoHwAb_SetFctGpioPhaCUpprCmd  # UB:Derived from original system description
    connect IoHwAb.SetFctPeriphPhaALowrCmd -> CDD_TSG31CfgAndUse.IoHwAb_SetFctPeriphPhaALowrCmd  # UB:Derived from original system description
    connect IoHwAb.SetFctPeriphPhaAUpprCmd -> CDD_TSG31CfgAndUse.IoHwAb_SetFctPeriphPhaAUpprCmd  # UB:Derived from original system description
    connect IoHwAb.SetFctPeriphPhaBLowrCmd -> CDD_TSG31CfgAndUse.IoHwAb_SetFctPeriphPhaBLowrCmd  # UB:Derived from original system description
    connect IoHwAb.SetFctPeriphPhaBUpprCmd -> CDD_TSG31CfgAndUse.IoHwAb_SetFctPeriphPhaBUpprCmd  # UB:Derived from original system description
    connect IoHwAb.SetFctPeriphPhaCLowrCmd -> CDD_TSG31CfgAndUse.IoHwAb_SetFctPeriphPhaCLowrCmd  # UB:Derived from original system description
    connect IoHwAb.SetFctPeriphPhaCUpprCmd -> CDD_TSG31CfgAndUse.IoHwAb_SetFctPeriphPhaCUpprCmd  # UB:Derived from original system description
    connect IoHwAb.SetGpioPhaALowrCmd -> CDD_TSG31CfgAndUse.IoHwAb_SetGpioPhaALowrCmd  # UB:Derived from original system description
    connect IoHwAb.SetGpioPhaAUpprCmd -> CDD_TSG31CfgAndUse.IoHwAb_SetGpioPhaAUpprCmd  # UB:Derived from original system description
    connect IoHwAb.SetGpioPhaBLowrCmd -> CDD_TSG31CfgAndUse.IoHwAb_SetGpioPhaBLowrCmd  # UB:Derived from original system description
    connect IoHwAb.SetGpioPhaBUpprCmd -> CDD_TSG31CfgAndUse.IoHwAb_SetGpioPhaBUpprCmd  # UB:Derived from original system description
    connect IoHwAb.SetGpioPhaCLowrCmd -> CDD_TSG31CfgAndUse.IoHwAb_SetGpioPhaCLowrCmd  # UB:Derived from original system description
    connect IoHwAb.SetGpioPhaCUpprCmd -> CDD_TSG31CfgAndUse.IoHwAb_SetGpioPhaCUpprCmd  # UB:Derived from original system description
    connect IoHwAb.GetGpioGateDrv0Diagc -> GateDrv0Ctrl.IoHwAb_GetGpioMotDrvr0Diag  # UB:Derived from original system description
    connect IoHwAb.SetGpioGateDrv0Rst -> GateDrv0Ctrl.IoHwAb_SetGpioGateDrv0Rst  # UB:Derived from original system description
    connect IoHwAb.SetGpioSysFlt2A -> GateDrv0Ctrl.IoHwAb_SetGpioSysFlt2A  # UB:Derived from original system description
    connect IoHwAb.SetGpioPwrTurnOffCtrl -> PwrUpSeq.IoHwAb_SetGpioPwrTurnOffCtrl  # UB:Derived from original system description
    connect IoHwAb.SetGpioSysFlt2A -> ShtdwnMech.IoHwAb_SetGpioSysFlt2A  # UB:Derived from original system description
    connect IoHwAb.GetGpioPwrOutpEnaFb -> TmplMonr.IoHwAb_GetGpioPwrOutpEnaFb  # UB:Derived from original system description
    connect IoHwAb.SetGpioTmplMonrWdg -> TmplMonr.IoHwAb_SetGpioTmplMonrWdg  # UB:Derived from original system description
    connect MotCtrlPrmEstimn.MotREstimd -> MotRefMdl.MotREstimd  # UB:Derived from original system description
    connect MotTqCmdSca.GetMotTqCmdSca -> CmnMfgSrv.GetMotTqCmdSca  # UB:Derived from original system description
    connect MotTqCmdSca.SetMotTqCmdSca -> CmnMfgSrv.SetMotTqCmdSca  # UB:Derived from original system description
    connect MotTqCmdSca.MotTqCmdMrfScad -> DiagcMgr.MotTqCmdMrfScad  # UB:Derived from original system description
    connect MotTqCmdSca.MotTqCmdMrfScad -> MotQuadDetn.MotTqCmd  # UB:Derived from original system description
    connect MotTqCmdSca.MotTqCmdMrfScad -> MotRefMdl.MotTqCmdMrfScad  # UB:Derived from original system description
    connect PwrLimr.MotTqCmdPwrLimd -> MotTqCmdSca.MotTqCmdMrf  # UB:Derived from original system description
    connect CDD_MotVel.MotVelCrf -> MotTqTranlDampg.MotVelCrf  # UB:Derived from original system description
    connect CDD_NxtrTi.GetRefTmr100MicroSec32bit -> MotTqTranlDampg.GetRefTmr100MicroSec32bit  # UB:Derived from original system description
    connect CDD_NxtrTi.GetTiSpan100MicroSec32bit -> MotTqTranlDampg.GetTiSpan100MicroSec32bit  # UB:Derived from original system description
    connect CDD_NxtrTi.GetRefTmr100MicroSec32bit -> Swp.GetRefTmr100MicroSec32bit  # UB:Derived from original system description
    connect CDD_NxtrTi.GetTiSpan100MicroSec32bit -> Swp.GetTiSpan100MicroSec32bit  # UB:Derived from original system description
    connect DiagcMgr.DiagcStsCtrldShtDwnFltPrsnt -> MotTqTranlDampg.DiagcStsCtrldShtDwnFltPrsnt  # UB:Derived from original system description
    connect HwTqArbn.HwTq -> Swp.HwTq  # UB:Derived from original system description
    connect MotTqTranlDampg.MotTqCmdMrfDampd -> PwrLimr.MotTqCmdMrf  # UB:Derived from original system description
    connect PolarityCfg.AssiMechPolarity -> MotTqTranlDampg.AssiMechPolarity  # UB:Derived from original system description
    connect SysStMod.SysSt -> MotTqTranlDampg.SysSt  # UB:Derived from original system description
    connect CDD_MotAg0Meas.MotAg0CoeffTblRead -> CmnMfgSrv.MotAg0MeasMotAg0CoeffTblRead  # UB:Derived from original system description
    connect CDD_MotAg0Meas.MotAg0CoeffTblWr -> CmnMfgSrv.MotAg0MeasMotAg0CoeffTblWr  # UB:Derived from original system description
    connect CDD_MotAg1Meas.MotAg1CoeffTblRead -> CmnMfgSrv.MotAg1MeasMotAg1CoeffTblRead  # UB:Derived from original system description
    connect CDD_MotAg1Meas.MotAg1CoeffTblWr -> CmnMfgSrv.MotAg1MeasMotAg1CoeffTblWr  # UB:Derived from original system description
    connect CDD_NxtrTi.GetRefTmr100MicroSec32bit -> CmnMfgSrv.GetRefTmr100MicroSec32bit1  # UB:Derived from original system description
    connect CDD_NxtrTi.GetTiSpan100MicroSec32bit -> CmnMfgSrv.GetTiSpan100MicroSec32bit1  # UB:Derived from original system description
    connect Dcm.DcmEcuReset -> BswM.Notification_SwcModeNotification_DcmEcuReset
    connect NvMProxy.PSProxy_Rte_NvmBlock_DutyCycThermProtn_FilStVal -> DutyCycThermProtn.FilStVal
    connect NvMProxy.PSProxy_Rte_NvmBlock_MotCtrlPrmEstimn_MotPrmNom -> MotCtrlPrmEstimn.MotPrmNom
    connect BswM.Switch_VinComSwitchPort -> Vin.VinCom
    connect Dlog.LifeCycle -> BswM.Notification_SwcModeNotification_Dlog_LifeCycle
    connect Vin.LifeCycle -> BswM.Notification_SwcModeNotification_Vin_LifeCycle
    connect SysTime.LifeCycle -> BswM.Notification_SwcModeNotification_SysTime_LifeCycle
    connect Omc.LifeCycle -> BswM.Notification_SwcModeNotification_Omc_LifeCycle
    connect NvM.PAdmin_NVM_BLOCK_BOOT_PROG_DATA -> Dlog.NvMAdmin_DlogProgData
    connect NvM.PS_NVM_BLOCK_BOOT_PROG_DATA -> Dlog.NvMService_DlogProgData
    connect NvM.PS_Rte_NvmBlock_Omc -> Omc.NvMServicePort
    connect Vin.NvMNotifyJobFinished_Vin -> NvM.NvM_RpNotifyJobEnd_Rte_NvmBlock_Vin
    connect NvM.PS_Rte_NvmBlock_Vin -> Vin.NvMService_Vin
    connect Dcm.DcmDiagnosticSessionControl -> BswM.Notification_SwcModeNotification_DcmDiagnosticSessionControl
    connect Dlog.Vin -> Dcm.DataServices_DcmDspData_Vin
    connect BacComIf.ComVin -> Vin.ComVin  # UB:Derived from original system description
    delegate BacComIf.NO_VECH_{1..7} <-> outer port NO_VECH_{1..7}  # UB:Derived from original system description
    connect NvMProxy.PSProxy_Rte_NvmBlock_DiagcMgr_DiagcMgrLtchCntrAry -> DiagcMgr.DiagcMgrLtchCntrAry
    connect NvMProxy.PSProxy_Rte_NvmBlock_DiagcMgr_DiagcMgrNtcFltAry -> DiagcMgr.DiagcMgrNtcFltAry
    connect NvMProxy.PSProxy_Rte_NvmBlock_HwTqCorrln_HwTqChACmnModCmpLpFilSt -> HwTqCorrln.HwTqChACmnModCmpLpFilSt
    connect NvMProxy.PSProxy_Rte_NvmBlock_MotTqCmdSca_MotTqScaFac -> MotTqCmdSca.MotTqScaFac
    connect NvMProxy.PSProxy_Rte_NvmBlock_CDD_MotAgCmp_MotAgCmpMotAgBackEmf -> CDD_MotAgCmp.MotAgCmpMotAgBackEmf
    connect NvMProxy.PSProxy_Rte_NvmBlock_CDD_NvMProxy_ShtdwnClsChk -> CDD_NvMProxy.ShtdwnClsChkBlk
    connect NvMProxy.PSProxy_Rte_NvmBlock_CDD_CurrMeas_CurrMeasEolGainCalSetABC -> CDD_CurrMeas.CurrMeasEolGainCalSetABC
    connect NvMProxy.PSProxy_Rte_NvmBlock_CDD_CurrMeas_CurrMeasEolOffsCalSetABC -> CDD_CurrMeas.CurrMeasEolOffsCalSetABC
    connect NvMProxy.PSProxy_Rte_NvmBlock_PolarityCfg_PolarityCfgSaved -> PolarityCfg.PolarityCfgSaved
    connect WdgM_Appl9.alive_SE_2ms_Appl9_ChkPt_2ms_Appl9_End -> CDD_ChkPtAppl9.ChkPt_2ms_Appl9_End
    connect WdgM_Appl9.alive_SE_2ms_Appl9_ChkPt_2ms_Appl9_Strt -> CDD_ChkPtAppl9.ChkPt_2ms_Appl9_Strt
    connect WdgM_Appl9.alive_SE_10ms_Appl9_ChkPt_10ms_Appl9_End -> CDD_ChkPtAppl9.ChkPt_10ms_Appl9_End
    connect WdgM_Appl9.alive_SE_10ms_Appl9_ChkPt_10ms_Appl9_Strt -> CDD_ChkPtAppl9.ChkPt_10ms_Appl9_Strt
    connect WdgM_Appl9.alive_SE_100ms_Appl9_ChkPt_100ms_Appl9_End -> CDD_ChkPtAppl9.ChkPt_100ms_Appl9_End
    connect WdgM_Appl9.alive_SE_100ms_Appl9_ChkPt_100ms_Appl9_Strt -> CDD_ChkPtAppl9.ChkPt_100ms_Appl9_Strt
    connect WdgM_Appl7.alive_SE_2ms_Appl7_ChkPt_2ms_Appl7_End -> CDD_ChkPtAppl7.ChkPt_2ms_Appl7_End
    connect WdgM_Appl7.alive_SE_2ms_Appl7_ChkPt_2ms_Appl7_Strt -> CDD_ChkPtAppl7.ChkPt_2ms_Appl7_Strt
    connect WdgM_Appl7.alive_SE_4ms_Appl7_ChkPt_4ms_Appl7_End -> CDD_ChkPtAppl7.ChkPt_4ms_Appl7_End
    connect WdgM_Appl7.alive_SE_4ms_Appl7_ChkPt_4ms_Appl7_Strt -> CDD_ChkPtAppl7.ChkPt_4ms_Appl7_Strt
    connect WdgM_Appl7.alive_SE_10ms_Appl7_ChkPt_10ms_Appl7_End -> CDD_ChkPtAppl7.ChkPt_10ms_Appl7_End
    connect WdgM_Appl7.alive_SE_10ms_Appl7_ChkPt_10ms_Appl7_Strt -> CDD_ChkPtAppl7.ChkPt_10ms_Appl7_Strt
    connect WdgM_Appl7.alive_SE_100ms_Appl7_ChkPt_100ms_Appl7_End -> CDD_ChkPtAppl7.ChkPt_100ms_Appl7_End
    connect WdgM_Appl7.alive_SE_100ms_Appl7_ChkPt_100ms_Appl7_Strt -> CDD_ChkPtAppl7.ChkPt_100ms_Appl7_Strt
    connect WdgM_Appl8.alive_SE_2ms_Appl8_ChkPt_2ms_Appl8_End -> CDD_ChkPtAppl8.ChkPt_2ms_Appl8_End
    connect WdgM_Appl8.alive_SE_2ms_Appl8_ChkPt_2ms_Appl8_Strt -> CDD_ChkPtAppl8.ChkPt_2ms_Appl8_Strt
    connect WdgM_Appl8.alive_SE_10ms_Appl8_ChkPt_10ms_Appl8_End -> CDD_ChkPtAppl8.ChkPt_10ms_Appl8_End
    connect WdgM_Appl8.alive_SE_10ms_Appl8_ChkPt_10ms_Appl8_Strt -> CDD_ChkPtAppl8.ChkPt_10ms_Appl8_Strt
    connect CDD_NxtrTi.GetRefTmr100MicroSec32bit -> SysFricLrng.GetRefTmr100MicroSec32bit  # UB:Derived from original system description
    connect CDD_NxtrTi.GetTiSpan100MicroSec32bit -> SysFricLrng.GetTiSpan100MicroSec32bit  # UB:Derived from original system description
    connect CmnMfgSrv.FricLrngDi -> SysFricLrng.FricLrngDi  # UB:Derived from original system description
    connect FltInj.FltInj_f32 -> SysFricLrng.FltInj_f32  # UB:Derived from original system description
    connect DiagcMgr.SysDiMotTqCmdSca -> StOutpCtrl.SysDiMotTqCmdSca  # UB:Derived from original system description
    connect DiagcMgr.SysDiRampRate -> StOutpCtrl.SysDiRampRate  # UB:Derived from original system description
    connect DiagcMgrStub.GetDiagcDataStub -> DiagcMgr.GetDiagcDataAppl{0..5}  # UB:Derived from original system description
    connect DiagcMgrStub.GetNtcDebCntrStub -> DiagcMgr.GetNtcDebCntrAppl{0..5}  # UB:Derived from original system description
    connect DiagcMgrStub.GetNtcInfoStub -> DiagcMgr.GetNtcInfoAppl{0..5}  # UB:Derived from original system description
    connect DiagcMgr.DiagcStsCtrldShtDwnFltPrsnt -> StOutpCtrl.DiagcStsCtrldShtDwnFltPrsnt  # UB:Derived from original system description
    connect DiagcMgr.SysStFltOutpReqDi -> StOutpCtrl.SysStFltOutpReqDi  # UB:Derived from original system description
    connect FltInj.FltInj_f32 -> VehSigCdng.FltInj_f32  # UB:Derived from original system description
    connect VehSigCdng.VehLatA -> SysFricLrng.VehLatA  # UB:Derived from original system description
    connect CDD_MotVel.MotVelCrf -> EotProtn.MotVelCrf  # UB:Derived from original system description
    connect CmnMfgSrv.EotProtnDi -> EotProtn.EotProtnDi  # UB:Derived from original system description
    connect StOutpCtrl.SysMotTqCmdSca -> EotProtn.SysMotTqCmdSca  # UB:Derived from original system description
    connect DutyCycThermProtn.ThermMotTqLim -> LimrCdng.ThermMotTqLim  # UB:Derived from original system description
    connect EotProtn.EotAssiSca -> LimrCdng.EotAssiSca  # UB:Derived from original system description
    connect EotProtn.EotMotTqLim -> LimrCdng.EotMotTqLim  # UB:Derived from original system description
    connect FltInj.FltInj_f32 -> LimrCdng.FltInj_f32  # UB:Derived from original system description
    connect HiLoadStallLimr.StallMotTqLim -> LimrCdng.StallMotTqLim  # UB:Derived from original system description
    connect MotTqTranlDampg.MotTqTranlDampgCmpl -> StOutpCtrl.MotTqTranlDampgCmpl  # UB:Derived from original system description
    connect StOutpCtrl.SysMotTqCmdSca -> LimrCdng.SysMotTqCmdSca  # UB:Derived from original system description
    connect VehSpdLimr.VehSpdMotTqLim -> LimrCdng.VehSpdMotTqLim  # UB:Derived from original system description
    connect CDD_CurrMeas.MotCurrEolCalSt -> CurrMeasCorrln.MotCurrEolCalSt  # UB:Derived from original system description
    connect DiagcMgrProxyAppl10.GetNtcQlfrSts10 -> CurrMeasCorrln.GetNtcQlfrSts  # UB:Derived from original system description
    connect DiagcMgrProxyAppl10.SetNtcSts10 -> CurrMeasCorrln.SetNtcSts  # UB:Derived from original system description
    connect FltInj.FltInj_u08 -> CurrMeasCorrln.FltInj_u08  # UB:Derived from original system description
    connect GateDrv0Ctrl.DiagcStsIvtr1Inactv -> CurrMeasCorrln.DiagcStsIvtr1Inactv  # UB:Derived from original system description
    connect SysStMod.SysSt -> CurrMeasCorrln.SysSt  # UB:Derived from original system description
    connect CDD_CurrMeas.MotCurrQlfr1 -> CDD_MotCtrlMgr.MotCurrQlfr1  # UB:Derived from original system description
    connect CurrMeasCorrln.CurrMeasCorrlnSts -> CDD_MotCtrlMgr.CurrMeasCorrlnSts  # UB:Derived from original system description
    connect CDD_MotVel.MotVelCrf -> MotVelCtrl.MotVelCrf  # UB:Derived from original system description
    connect CDD_NxtrTi.GetRefTmr100MicroSec32bit -> MotVelCtrl.GetRefTmr100MicroSec32bit  # UB:Derived from original system description
    connect CDD_NxtrTi.GetTiSpan100MicroSec32bit -> MotVelCtrl.GetTiSpan100MicroSec32bit  # UB:Derived from original system description
    connect DiagcMgrProxyAppl10.SetNtcSts10 -> CDD_McuDiagc.SetNtcSts  # UB:Derived from original system description
    connect MotVelCtrl.GetCtrlPrm -> CmnMfgSrv.GetCtrlPrm  # UB:Derived from original system description
    connect MotVelCtrl.SetCtrlPrm -> CmnMfgSrv.SetCtrlPrm  # UB:Derived from original system description
    connect MotVelCtrl.StopCtrl -> CmnMfgSrv.StopCtrl  # UB:Derived from original system description
    connect MotVelCtrl.StrtCtrl -> CmnMfgSrv.StrtCtrl  # UB:Derived from original system description
    connect SysStMod.SysSt -> CDD_McuDiagc.SysSt  # UB:Derived from original system description
    connect CDD_McuDiagc.LoopCntr2MilliSec -> CDD_MotCtrlMgr.LoopCntr2MilliSec  # UB:Derived from original system description
    connect CDD_MotCtrlMgr.FastLoopCntr -> CDD_McuDiagc.FastLoopCntr  # UB:Derived from original system description
    connect CDD_MotCtrlMgr.SlowLoopCntr -> CDD_McuDiagc.SlowLoopCntr  # UB:Derived from original system description
    connect CDD_VrfyCritReg.MCalReadVrfyFailFltInfo -> McalErrHndlg.MCalReadVrfyFailFltInfo  # UB:Derived from original system description
    connect DiagcMgrProxyAppl10.SetNtcSts10 -> CDD_CoreVltgMonr.SetNtcSts  # UB:Derived from original system description
    connect DiagcMgrProxyAppl10.SetNtcSts10 -> CDD_VrfyCritReg.SetNtcSts  # UB:Derived from original system description
    connect NvMProxy.PSProxy_Rte_NvmBlock_CDD_VrfyCritReg_MCalReadVrfyCritRegFltInfo -> CDD_VrfyCritReg.MCalWrVrfyRegFltInfoStorg
    delegate BmwMsgSlot121Bas1Repn2BusFrChA.sigGroup_CON_VEH <-> outer port sigGroup_CON_VEH  # UB:Derived from original system description
    delegate BmwMsgSlot107Bas0Repn1BusFrChA.sigGroup_OFFS_QUAD_EPS <-> outer port sigGroup_OFFS_QUAD_EPS  # UB:Derived from original system description
    delegate BmwMsgSlot55Bas3Repn4BusFrChA.sigGroup_V_VEH <-> outer port sigGroup_V_VEH  # UB:Derived from original system description
    connect SysFricLrng.ClrFricLrngOperMod -> CmnMfgSrv.ClrFricLrngOperMod  # UB:Derived from original system description
    connect SysFricLrng.GetFricData -> CmnMfgSrv.GetFricData  # UB:Derived from original system description
    connect SysFricLrng.GetFricLrngData -> CmnMfgSrv.GetFricLrngData  # UB:Derived from original system description
    connect SysFricLrng.GetFricOffsOutpDi -> CmnMfgSrv.GetFricOffsOutpDi  # UB:Derived from original system description
    connect SysFricLrng.InitFricLrngTbl -> CmnMfgSrv.InitFricLrngTbl  # UB:Derived from original system description
    connect SysFricLrng.SetFricData -> CmnMfgSrv.SetFricData  # UB:Derived from original system description
    connect SysFricLrng.SetFricLrngData -> CmnMfgSrv.SetFricLrngData  # UB:Derived from original system description
    connect SysFricLrng.SetFricOffsOutpDi -> CmnMfgSrv.SetFricOffsOutpDi  # UB:Derived from original system description
    connect DiagcMgr.ClrDiagcFlgProxy -> DiagcMgrProxyAppl7.ClrDiagcFlgProxy  # UB:Derived from original system description
    connect DiagcMgr.DiagcMgrIninCore -> DiagcMgrProxyAppl7.DiagcMgrIninCore  # UB:Derived from original system description
    connect DiagcMgr.GetNtcActvCore -> DiagcMgrProxyAppl7.GetNtcActvCore  # UB:Derived from original system description
    connect DiagcMgr.GetNtcQlfrStsCore -> DiagcMgrProxyAppl7.GetNtcQlfrStsCore  # UB:Derived from original system description
    connect DiagcMgr.GetNtcStsCore -> DiagcMgrProxyAppl7.GetNtcStsCore  # UB:Derived from original system description
    connect DiagcMgr.SetNtcStsCore -> DiagcMgrProxyAppl7.SetNtcStsCore  # UB:Derived from original system description
    connect DiagcMgrProxyAppl7.GetDiagcDataAppl7 -> DiagcMgr.GetDiagcDataAppl7  # UB:Derived from original system description
    connect DiagcMgrProxyAppl7.GetNtcDebCntrAppl7 -> DiagcMgr.GetNtcDebCntrAppl7  # UB:Derived from original system description
    connect DiagcMgrProxyAppl7.GetNtcInfoAppl7 -> DiagcMgr.GetNtcInfoAppl7  # UB:Derived from original system description
    connect BmwHwAgArbnAndEotPosn.HwAgCcwDetd -> EotProtn.HwAgCcwDetd  # UB:Derived from original system description
    connect BmwHwAgArbnAndEotPosn.HwAgCwDetd -> EotProtn.HwAgCwDetd  # UB:Derived from original system description
    connect BmwHwAgArbnAndEotPosn.HwAgEotCcw -> EotProtn.HwAgEotCcw  # UB:Derived from original system description
    connect BmwHwAgArbnAndEotPosn.HwAgEotCw -> EotProtn.HwAgEotCw  # UB:Derived from original system description
    connect BmwHwAgArbnAndEotPosn.HwAgEotCcw -> VehSpdLimr.HwAgEotCcw  # UB:Derived from original system description
    connect BmwHwAgArbnAndEotPosn.HwAgEotCw -> VehSpdLimr.HwAgEotCw  # UB:Derived from original system description
    connect CDD_MotVel.MotVelCrf -> LrndRackCentr.MotVelCrf  # UB:Derived from original system description
    connect CDD_MotVel.MotVelCrf -> LrnPinionCentr.MotVelCrf  # UB:Derived from original system description
    connect CDD_NxtrTi.GetRefTmr100MicroSec32bit -> BmwHwAgArbnAndEotPosn.GetRefTmr100MicroSec32bit  # UB:Derived from original system description
    connect CDD_NxtrTi.GetTiSpan100MicroSec32bit -> BmwHwAgArbnAndEotPosn.GetTiSpan100MicroSec32bit  # UB:Derived from original system description
    connect CDD_NxtrTi.GetRefTmr100MicroSec32bit -> LrndRackCentr.GetRefTmr100MicroSec32bit  # UB:Derived from original system description
    connect CDD_NxtrTi.GetTiSpan100MicroSec32bit -> LrndRackCentr.GetTiSpan100MicroSec32bit  # UB:Derived from original system description
    connect CDD_NxtrTi.GetRefTmr100MicroSec32bit -> LrnPinionCentr.GetRefTmr100MicroSec32bit  # UB:Derived from original system description
    connect CDD_NxtrTi.GetTiSpan100MicroSec32bit -> LrnPinionCentr.GetTiSpan100MicroSec32bit  # UB:Derived from original system description
    connect CmplncErr.CmplncErrMotToPinion -> BmwHwAgArbnAndEotPosn.CmplncErrMotToPinion  # UB:Derived from original system description
    connect LrndRackCentr.LongTermRackCentrCmpl -> BmwHwAgArbnAndEotPosn.LongTermRackCentrCmpl  # UB:Derived from original system description
    connect LrndRackCentr.RackCentrPinionAg -> BmwHwAgArbnAndEotPosn.RackCentrPinionAg  # UB:Derived from original system description
    connect LrndRackCentr.RstRackCentrMotRev -> BmwHwAgArbnAndEotPosn.RstRackCentrMotRev  # UB:Derived from original system description
    connect LrndRackCentr.TotRackTrvl -> BmwHwAgArbnAndEotPosn.TotRackTrvl  # UB:Derived from original system description
    connect LrnPinionCentr.PinionCentrLrnHwCentr -> LrndRackCentr.PinionCentrLrnHwCentr  # UB:Derived from original system description
    connect LrnPinionCentr.PinionCentrLrnHwTrvl -> LrndRackCentr.PinionCentrLrnHwTrvl  # UB:Derived from original system description
    connect LrnPinionCentr.PinionCentrLrnSt -> LrndRackCentr.PinionCentrLrnSt  # UB:Derived from original system description
    connect MotAgCorrln.MotAgMeclCorrlnSt -> BmwHwAgArbnAndEotPosn.MotAgMeclCorrlnSt  # UB:Derived from original system description
    connect NvMProxy.PSProxy_Rte_NvmBlock_LrndRackCentr_LrndRackCentr -> LrndRackCentr.LrndRackCentrNvm
    connect NvMProxy.PSProxy_Rte_NvmBlock_BmwHwAgArbnAndEotPosn_BmwVehCentrOffs -> BmwHwAgArbnAndEotPosn.BmwVehCentrOffs
    connect BmwHwAgArbnAndEotPosn.BmwPinionAg -> BmwMsgSlot51Bas0Repn2BusFrChA.BmwPinionAg  # UB:Derived from original system description
    delegate BmwMsgSlot274Bas2Repn4BusFrChA.sigGroup_DISP_CC_EPS <-> outer port sigGroup_DISP_CC_EPS  # UB:Derived from original system description
    delegate BmwMsgSlot51Bas0Repn2BusFrChA.sigGroup_AVL_PO_EPS <-> outer port sigGroup_AVL_PO_EPS  # UB:Derived from original system description
    delegate BmwMsgSlot51Bas0Repn2BusFrChA.TRGG_ENGTORQ_EPS <-> outer port TRGG_ENGTORQ_EPS  # UB:Derived from original system description
    connect CDD_ExcpnHndlg.GetMcuDiagcSpplData -> DiagcMgr.GetMcuDiagcSpplData  # UB:Derived from original system description
    connect CDD_MotCtrlMgr.MotAg0WarnReg -> CDD_MotAg0Meas.MotAg0WarnReg  # UB:Derived from original system description
    connect CDD_MotCtrlMgr.MotAg1WarnReg -> CDD_MotAg1Meas.MotAg1WarnReg  # UB:Derived from original system description
    connect EcuTMeas.DiagcStsLimdTPrfmnc -> DutyCycThermProtn.DiagcStsLimdTPrfmnc  # UB:Derived from original system description
    connect TurnCntrCorrln.TurnCntrIdptSig -> CDD_MotAg0Meas.TurnCntrIdptSig  # UB:Derived from original system description
    connect NvMProxy.PSProxy_Rte_NvmBlock_ExcpnHndlg_McuDiagcData -> CDD_ExcpnHndlg.McuDiagcData
    connect CmnMfgSrv.SysMotTqCmdRampRateDi -> StOutpCtrl.SysMotTqCmdRampRateDi  # UB:Derived from original system description
    connect BmwFltHndlg.BmwFltLampReqSts -> BmwMsgSlot274Bas2Repn4BusFrChA.BmwFltLampReqSts  # UB:Derived from original system description
    connect BmwFltHndlg.BmwFltLampReqTyp -> BmwMsgSlot274Bas2Repn4BusFrChA.BmwFltLampReqTyp  # UB:Derived from original system description
    connect BmwMsgSlot121Bas1Repn2BusFrChA.BmwVehCdn -> BmwStReqMgr.BmwVehCdn  # UB:Derived from original system description
    connect BmwMsgSlot121Bas1Repn2BusFrChA.BmwVehCdnVld -> BmwStReqMgr.BmwVehCdnVld  # UB:Derived from original system description
    connect BmwStReqMgr.SysOperMotTqCmdSca -> StOutpCtrl.SysOperMotTqCmdSca  # UB:Derived from original system description
    connect BmwStReqMgr.SysOperRampRate -> StOutpCtrl.SysOperRampRate  # UB:Derived from original system description
    connect BmwStReqMgr.PwrSplyEnaReq -> SysStMod.PwrSplyEnaReq  # UB:Derived from original system description
    connect BmwStReqMgr.SysStReqEna -> SysStMod.SysStReqEna  # UB:Derived from original system description
    connect CDD_NxtrTi.GetRefTmr100MicroSec32bit -> BmwStReqMgr.GetRefTmr100MicroSec32bit  # UB:Derived from original system description
    connect CDD_NxtrTi.GetTiSpan100MicroSec32bit -> BmwStReqMgr.GetTiSpan100MicroSec32bit  # UB:Derived from original system description
    connect CmnMfgSrv.RtnCmdDi -> CtrldVelRtn.RtnCmdDi  # UB:Derived from original system description
    connect DiagcMgr.SysStFltOutpReqDi -> BmwStReqMgr.SysStFltOutpReqDi  # UB:Derived from original system description
    connect HwTqArbn.HwTq -> BmwStReqMgr.HwTq  # UB:Derived from original system description
    connect IoHwAb.GetGpioMcuEna -> BmwStReqMgr.IoHwAb_GetGpioMcuEna  # UB:Derived from original system description
    connect StOutpCtrl.SysStReqDi -> SysStMod.SysStReqDi  # UB:Derived from original system description
    connect SysStMod.SysSt -> BmwStReqMgr.SysSt  # UB:Derived from original system description
    connect CDD_MotCtrlMgr.MotCurrCorrdA -> CurrMeasCorrln.MotCurrCorrdA  # UB:Derived from original system description
    connect CDD_MotCtrlMgr.MotCurrCorrdB -> CurrMeasCorrln.MotCurrCorrdB  # UB:Derived from original system description
    connect CDD_MotCtrlMgr.MotCurrCorrdC -> CurrMeasCorrln.MotCurrCorrdC  # UB:Derived from original system description
    connect CDD_MotCtrlMgr.MotCurrRollgCntr1 -> CurrMeasCorrln.MotCurrRollgCntr1  # UB:Derived from original system description
    connect CDD_MotCtrlMgr.MotCurrDax -> MotCurrPeakEstimn.MotCurrDax  # UB:Derived from original system description
    connect CDD_MotCtrlMgr.MotCurrQax -> MotCurrPeakEstimn.MotCurrQax  # UB:Derived from original system description
    connect CDD_MotCtrlMgr.HwTq4RawFastAdcBuf -> CDD_HwTq4Meas.HwTq4RawFastAdcBuf  # UB:Derived from original system description
    connect CDD_MotCtrlMgr.HwTq5RawFastAdcBuf -> CDD_HwTq5Meas.HwTq5RawFastAdcBuf  # UB:Derived from original system description
    connect BmwHwAgArbnAndEotPosn.BmwRackCentrToVehCentrOffs -> BmwMsgSlot51Bas0Repn2BusFrChA.BmwRackCntrToVehCntrOffs  # UB:Derived from original system description
    connect BmwHwAgArbnAndEotPosn.BmwRackCentrToVehCentrOffsVld -> BmwMsgSlot51Bas0Repn2BusFrChA.BmwRackCntrToVehCntrOffsVld  # UB:Derived from original system description
    connect BmwHwAgArbnAndEotPosn.PinionAgConf -> EotProtn.HwAgAuthy  # UB:Derived from original system description
    connect BmwHwAgArbnAndEotPosn.PinionAg -> LrnPinionCentr.HwAg  # UB:Derived from original system description
    connect BmwHwAgArbnAndEotPosn.PinionAg -> MotTqTranlDampg.HwAg  # UB:Derived from original system description
    connect BmwHwAgArbnAndEotPosn.PinionAg -> PosnTrakgServo.HwAg  # UB:Derived from original system description
    connect BmwHwAgArbnAndEotPosn.PinionAg -> SysFricLrng.HwAg  # UB:Derived from original system description
    connect BmwHwAgArbnAndEotPosn.PinionAg -> VehSpdLimr.HwAg  # UB:Derived from original system description
    connect BmwHwAgArbnAndEotPosn.PinionAgConf -> VehSpdLimr.HwAgAuthy  # UB:Derived from original system description
    connect CDD_MotAg0Meas.MotAg0MeclQlfr -> MotAgCorrln.MotAgAMeclQlfr  # UB:Derived from original system description
    connect CDD_MotAg0Meas.MotAg0TurnCntr -> TurnCntrCorrln.MotAgATurnCntr  # UB:Derived from original system description
    connect CDD_MotAg0Meas.MotAg0TurnCntrQlfr -> TurnCntrCorrln.MotAgATurnCntrQlfr  # UB:Derived from original system description
    connect CDD_MotAg0Meas.MotAg0TurnCntrRollgCntr -> TurnCntrCorrln.MotAgATurnCntrRollgCntr  # UB:Derived from original system description
    connect CDD_MotAg1Meas.MotAg1MeclQlfr -> MotAgCorrln.MotAgBMeclQlfr  # UB:Derived from original system description
    connect CDD_MotAg1Meas.MotAg1TurnCntr -> TurnCntrCorrln.MotAgBTurnCntr  # UB:Derived from original system description
    connect CDD_MotAg1Meas.MotAg1TurnCntrQlfr -> TurnCntrCorrln.MotAgBTurnCntrQlfr  # UB:Derived from original system description
    connect CDD_MotCtrlMgr.MotAg0Mecl -> MotAgCorrln.MotAgAMecl  # UB:Derived from original system description
    connect CDD_MotCtrlMgr.MotAg0MeclRollgCntr -> MotAgCorrln.MotAgAMeclRollgCntr  # UB:Derived from original system description
    connect CDD_MotCtrlMgr.MotAg1Mecl -> MotAgCorrln.MotAgBMecl  # UB:Derived from original system description
    connect CDD_MotCtrlMgr.MotAg1MeclRollgCntr -> MotAgCorrln.MotAgBMeclRollgCntr  # UB:Derived from original system description
    connect CDD_MotVel.MotVelCrf -> PosnTrakgServo.MotVelCrf  # UB:Derived from original system description
    connect DiagcMgr.DiagcStsNonRcvrlReqDiFltPrsnt -> BmwStReqMgr.DiagcStsNonRcvrlReqDiFltPrsnt  # UB:Derived from original system description
    connect DiagcMgrProxyAppl10.SetNtcSts10 -> BmwHwAgArbnAndEotPosn.SetNtcSts  # UB:Derived from original system description
    connect DiagcMgrProxyAppl10.SetNtcSts10 -> BmwMsgSlot107Bas0Repn1BusFrChA.SetNtcSts  # UB:Derived from original system description
    connect DiagcMgrProxyAppl10.SetNtcSts10 -> BmwMsgSlot55Bas3Repn4BusFrChA.SetNtcSts  # UB:Derived from original system description
    connect MotTqTranlDampg.MotTqCmdCrfDampd -> CmplncErr.MotTqCmdCrf  # UB:Derived from original system description
    connect PolarityCfg.AssiMechPolarity -> CtrldVelRtn.AssiMechPolarity  # UB:Derived from original system description
    connect PwrLimr.MotTqCmdPwrLimd -> CtrldVelRtn.MotTqCmdPwrLimd  # UB:Derived from original system description
    connect TEstimn.AssiMechT -> SysFricLrng.AssiMechT  # UB:Derived from original system description
    connect DiagcMgr.ClrDiagcFlgProxy -> DiagcMgrProxyAppl8.ClrDiagcFlgProxy  # UB:Derived from original system description
    connect DiagcMgr.DiagcMgrIninCore -> DiagcMgrProxyAppl8.DiagcMgrIninCore  # UB:Derived from original system description
    connect DiagcMgr.GetNtcActvCore -> DiagcMgrProxyAppl8.GetNtcActvCore  # UB:Derived from original system description
    connect DiagcMgr.GetNtcQlfrStsCore -> DiagcMgrProxyAppl8.GetNtcQlfrStsCore  # UB:Derived from original system description
    connect DiagcMgr.GetNtcStsCore -> DiagcMgrProxyAppl8.GetNtcStsCore  # UB:Derived from original system description
    connect DiagcMgr.SetNtcStsCore -> DiagcMgrProxyAppl8.SetNtcStsCore  # UB:Derived from original system description
    connect DiagcMgr.ClrDiagcFlgProxy -> DiagcMgrProxyAppl9.ClrDiagcFlgProxy  # UB:Derived from original system description
    connect DiagcMgr.DiagcMgrIninCore -> DiagcMgrProxyAppl9.DiagcMgrIninCore  # UB:Derived from original system description
    connect DiagcMgr.GetNtcActvCore -> DiagcMgrProxyAppl9.GetNtcActvCore  # UB:Derived from original system description
    connect DiagcMgr.GetNtcQlfrStsCore -> DiagcMgrProxyAppl9.GetNtcQlfrStsCore  # UB:Derived from original system description
    connect DiagcMgr.GetNtcStsCore -> DiagcMgrProxyAppl9.GetNtcStsCore  # UB:Derived from original system description
    connect DiagcMgr.SetNtcStsCore -> DiagcMgrProxyAppl9.SetNtcStsCore  # UB:Derived from original system description
    connect DiagcMgrProxyAppl7.SetNtcSts7 -> DutyCycThermProtn.SetNtcSts  # UB:Derived from original system description
    connect DiagcMgrProxyAppl8.GetDiagcDataAppl8 -> DiagcMgr.GetDiagcDataAppl8  # UB:Derived from original system description
    connect DiagcMgrProxyAppl8.GetNtcDebCntrAppl8 -> DiagcMgr.GetNtcDebCntrAppl8  # UB:Derived from original system description
    connect DiagcMgrProxyAppl8.GetNtcInfoAppl8 -> DiagcMgr.GetNtcInfoAppl8  # UB:Derived from original system description
    connect DiagcMgrProxyAppl8.GetNtcQlfrSts8 -> TurnCntrCorrln.GetNtcQlfrSts  # UB:Derived from original system description
    connect DiagcMgrProxyAppl8.SetNtcSts8 -> TurnCntrCorrln.SetNtcSts  # UB:Derived from original system description
    connect DiagcMgrProxyAppl9.GetDiagcDataAppl9 -> DiagcMgr.GetDiagcDataAppl9  # UB:Derived from original system description
    connect DiagcMgrProxyAppl9.GetNtcDebCntrAppl9 -> DiagcMgr.GetNtcDebCntrAppl9  # UB:Derived from original system description
    connect DiagcMgrProxyAppl9.GetNtcInfoAppl9 -> DiagcMgr.GetNtcInfoAppl9  # UB:Derived from original system description
    connect DiagcMgrProxyAppl9.GetNtcActv9 -> EcuTMeas.GetNtcActv  # UB:Derived from original system description
    connect DiagcMgrProxyAppl9.SetNtcStsAndSnpshtData9 -> EcuTMeas.SetNtcStsAndSnpshtData  # UB:Derived from original system description
    connect WdgM_Appl10.alive_SE_2msA_Appl10_ChkPt_2msA_Appl10_End -> CDD_ChkPtAppl10.ChkPt_2msA_Appl10_End
    connect WdgM_Appl10.alive_SE_2msA_Appl10_ChkPt_2msA_Appl10_Strt -> CDD_ChkPtAppl10.ChkPt_2msA_Appl10_Strt
    connect WdgM_Appl10.alive_SE_2msB_Appl10_ChkPt_2msB_Appl10_End -> CDD_ChkPtAppl10.ChkPt_2msB_Appl10_End
    connect WdgM_Appl10.alive_SE_2msB_Appl10_ChkPt_2msB_Appl10_Strt -> CDD_ChkPtAppl10.ChkPt_2msB_Appl10_Strt
    connect DiagcMgrProxyAppl10.SetNtcSts10 -> PwrLimr.SetNtcSts  # UB:Derived from original system description
    connect DiagcMgrProxyAppl10.SetNtcSts10 -> PwrSply.SetNtcSts  # UB:Derived from original system description
    connect CDD_CurrMeas.CurrMeasGainReadReqSngIvtr -> CmnMfgSrv.CurrMeasGainReadReqSngIvtr  # UB:Derived from original system description
    connect CDD_CurrMeas.CurrMeasGainWrReqSngIvtr -> CmnMfgSrv.CurrMeasGainWrReqSngIvtr  # UB:Derived from original system description
    connect CDD_CurrMeas.CurrMeasOffsReadReqSngIvtr -> CmnMfgSrv.CurrMeasOffsReadReqSngIvtr  # UB:Derived from original system description
    connect CDD_CurrMeas.CurrMeasOffsWrReqSngIvtr -> CmnMfgSrv.CurrMeasOffsWrReqSngIvtr  # UB:Derived from original system description
    connect CDD_MotAg1Meas.MotAg1TurnCntrRollgCntr -> TurnCntrCorrln.MotAgBTurnCntrRollgCntr  # UB:Derived from original system description
    connect DiagcMgr.ClrLtchCntrData -> CmnMfgSrv.ClrLtchCntrData  # UB:Derived from original system description
    connect DiagcMgr.ReadLtchCntrData -> CmnMfgSrv.ReadLtchCntrData  # UB:Derived from original system description
    connect DiagcMgrProxyAppl10.SetNtcSts10 -> BmwMsgSlot121Bas1Repn2BusFrChA.SetNtcSts  # UB:Derived from original system description
    connect CDD_MotCtrlMgr.MotCurrDax -> CmnMfgSrv.MotCurrDax  # UB:Derived from original system description
    connect CDD_MotCtrlMgr.MotCurrQax -> CmnMfgSrv.MotCurrQax  # UB:Derived from original system description
    connect NvMProxy.PSProxy_Rte_NvmBlock_CmnMfgSrv_CcaHwPartNr -> CmnMfgSrv.NvmCcaHwPartNr
    connect NvMProxy.PSProxy_Rte_NvmBlock_CmnMfgSrv_CcaSerlNr -> CmnMfgSrv.NvmCcaSerlNr
    connect NvMProxy.PSProxy_Rte_NvmBlock_CmnMfgSrv_DiRestore -> CmnMfgSrv.NvmDiRestore
    connect NvMProxy.PSProxy_Rte_NvmBlock_CmnMfgSrv_EpsSysSerlNr -> CmnMfgSrv.NvmEpsSysSerlNr
    connect NvMProxy.PSProxy_Rte_NvmBlock_CmnMfgSrv_IgnCntr -> CmnMfgSrv.NvmIgnCntr
    connect NvMProxy.PSProxy_Rte_NvmBlock_CmnMfgSrv_NxtrMfgEnaCntr -> CmnMfgSrv.NvmMfgEnaCntr
    connect NvMProxy.PSProxy_Rte_NvmBlock_CmnMfgSrv_MfgTmpBuf{0..4} -> CmnMfgSrv.NvmMfgTmpBuf{0..4}
    connect BmwDiagcSrvHndlg.BmwHwAgOffs -> BmwHwAgArbnAndEotPosn.BmwHwAgOffs  # UB:Derived from original system description
    connect BmwDiagcSrvHndlg.LockToLockEna -> LrndRackCentr.PinionCentrLrnEna  # UB:Derived from original system description
    connect BmwDiagcSrvHndlg.LockToLockEna -> LrnPinionCentr.PinionCentrLrnEna  # UB:Derived from original system description
    connect BmwHwAgArbnAndEotPosn.BmwRackCentrToVehCentrOffs -> BmwDiagcSrvHndlg.BmwRackCentrToVehCentrOffs  # UB:Derived from original system description
    connect BmwHwAgArbnAndEotPosn.BmwRackCentrToVehCentrOffsVld -> BmwDiagcSrvHndlg.BmwRackCntrToVehCntrOffsVld  # UB:Derived from original system description
    connect BmwHwAgArbnAndEotPosn.ClrBmwRackCentrToVehCentrOffs -> BmwDiagcSrvHndlg.ClrBmwRackCentrToVehCentrOffs  # UB:Derived from original system description
    connect BmwHwAgArbnAndEotPosn.ClrVehCentrPosn -> BmwDiagcSrvHndlg.ClrVehCentrPosn  # UB:Derived from original system description
    connect BmwHwAgArbnAndEotPosn.PinionAgConf -> BmwDiagcSrvHndlg.PinionAgConf  # UB:Derived from original system description
    connect BmwHwAgArbnAndEotPosn.SetVehCentrPosn -> BmwDiagcSrvHndlg.SetVehCentrPosn  # UB:Derived from original system description
    connect CDD_NxtrTi.GetRefTmr1MicroSec32bit -> BmwDiagcSrvHndlg.GetRefTmr1MicroSec32bit  # UB:Derived from original system description
    connect CDD_NxtrTi.GetTiSpan1MicroSec32bit -> BmwDiagcSrvHndlg.GetTiSpan1MicroSec32bit  # UB:Derived from original system description
    connect HwTqArbn.HwTq -> BmwDiagcSrvHndlg.HwTq  # UB:Derived from original system description
    connect LrndRackCentr.LongTermRackCentrCmpl -> BmwDiagcSrvHndlg.LongTermRackCentrCmpl  # UB:Derived from original system description
    connect LrndRackCentr.RackCentrMotAgErrPrsnt -> BmwDiagcSrvHndlg.RackCentrMotAgErrPrsnt  # UB:Derived from original system description
    connect LrndRackCentr.RstRackCentrMotAg -> BmwDiagcSrvHndlg.RstRackCentrMotAg  # UB:Derived from original system description
    connect LrndRackCentr.RstRackCentrMotRev -> BmwDiagcSrvHndlg.RstRackCentrMotRev  # UB:Derived from original system description
    connect LrndRackCentr.TotRackTrvl -> BmwDiagcSrvHndlg.TotRackTrvl  # UB:Derived from original system description
    connect LrnPinionCentr.PinionCentrLrnHwTrvl -> BmwDiagcSrvHndlg.PinionCentrLrnHwTrvl  # UB:Derived from original system description
    connect LrnPinionCentr.PinionCentrLrnSt -> BmwDiagcSrvHndlg.PinionCentrLrnSt  # UB:Derived from original system description
    connect LrnPinionCentr.SetInpPrm -> BmwDiagcSrvHndlg.SetInpPrm  # UB:Derived from original system description
    connect SysStMod.SysSt -> BmwDiagcSrvHndlg.SysSt  # UB:Derived from original system description
    connect BmwHwAgArbnAndEotPosn.PinionAg -> BmwDiagcSrvHndlg.PinionAg  # UB:Derived from original system description
    connect BmwHwAgArbnAndEotPosn.PinionAg -> CmnMfgSrv.PinionAg  # UB:Derived from original system description
    connect BmwHwAgArbnAndEotPosn.LongTermVehCentrCmpl -> BmwDiagcSrvHndlg.LongTermVehCentrCmpl  # UB:Derived from original system description
    connect BmwHwAgArbnAndEotPosn.PinionAgConf -> CtrldVelRtn.HwAgAuthy  # UB:Derived from original system description
    connect BmwHwAgArbnAndEotPosn.PinionAgConf -> SysFricLrng.HwAgAuthy  # UB:Derived from original system description
    connect BmwMsgSlot107Bas0Repn1BusFrChA.BmwQuadRtrOffs -> BmwHwAgArbnAndEotPosn.BmwQuadRotorOffs  # UB:Derived from original system description
    connect CDD_MotAgCmp.MotAgCumvAlgndMrf -> BmwHwAgArbnAndEotPosn.MotAgCumvAlgndMrf  # UB:Derived from original system description
    connect CDD_NxtrTi.GetRefTmr1MicroSec32bit -> CDD_XcpIf.GetRefTmr1MicroSec32bit  # UB:Derived from original system description
    connect CDD_SyncCrc.Calc32BitCrc_u32 -> TunSelnMngt.Calc32BitCrc_u32  # UB:Derived from original system description
    connect CmnMfgSrv.MfgEnaSt -> CDD_XcpIf.MfgEnaSt  # UB:Derived from original system description
    connect DiagcMgrProxyAppl10.SetNtcSts10 -> TunSelnMngt.SetNtcSts  # UB:Derived from original system description
    connect TunSelnAuthy.XcpCalChgReq -> CDD_XcpIf.XcpCalChgReq  # UB:Derived from original system description
    connect TunSelnAuthy.RtCalChgReq -> TunSelnMngt.RtCalChgReq  # UB:Derived from original system description
    connect TunSelnMngt.ActvGroup -> CDD_XcpIf.ActvGroup  # UB:Derived from original system description
    connect TunSelnMngt.ActvIninIdx -> CDD_XcpIf.ActvIninIdx  # UB:Derived from original system description
    connect TunSelnMngt.ActvRtIdx -> CDD_XcpIf.ActvRtIdx  # UB:Derived from original system description
    connect TunSelnMngt.CalCopySts -> CDD_XcpIf.CalCopySts  # UB:Derived from original system description
    connect TunSelnMngt.CopyCalPageReq -> CDD_XcpIf.CopyCalPageReq  # UB:Derived from original system description
    connect TunSelnMngt.GetCalPageReq -> CDD_XcpIf.GetCalPageReq  # UB:Derived from original system description
    connect TunSelnMngt.GetSegInfoReq -> CDD_XcpIf.GetSegInfoReq  # UB:Derived from original system description
    connect TunSelnMngt.OnlineTunRamAdrMpg -> CDD_XcpIf.OnlineTunRamAdrMpg  # UB:Derived from original system description
    connect TunSelnMngt.SetCalPageReq -> CDD_XcpIf.SetCalPageReq  # UB:Derived from original system description
    connect CDD_CurrMeas.MotCurrQlfr1 -> PhaDiscnct.MotCurrQlfr1  # UB:Derived from original system description
    connect CDD_MotCtrlMgr.MotCurrCorrdA -> PhaDiscnct.MotCurrCorrdA  # UB:Derived from original system description
    connect CDD_MotCtrlMgr.MotCurrCorrdB -> PhaDiscnct.MotCurrCorrdB  # UB:Derived from original system description
    connect CDD_MotCtrlMgr.MotCurrCorrdC -> PhaDiscnct.MotCurrCorrdC  # UB:Derived from original system description
    connect CDD_NxtrTi.GetRefTmr100MicroSec32bit -> PhaDiscnct.GetRefTmr100MicroSec32bit  # UB:Derived from original system description
    connect CDD_NxtrTi.GetTiSpan100MicroSec32bit -> PhaDiscnct.GetTiSpan100MicroSec32bit  # UB:Derived from original system description
    connect DiagcMgr.CnvSnpshtData_f32 -> RvsBattProtn.CnvSnpshtData_f32  # UB:Derived from original system description
    connect DiagcMgrProxyAppl10.SetNtcStsAndSnpshtData10 -> PhaDiscnct.SetNtcStsAndSnpshtData  # UB:Derived from original system description
    connect GateDrv0Ctrl.DiagcStsIvtr1Inactv -> PhaDiscnct.DiagcStsIvtr1Inactv  # UB:Derived from original system description
    connect GateDrv0Ctrl.IvtrFetFltPha -> PhaDiscnct.IvtrFetFltPha  # UB:Derived from original system description
    connect GateDrv0Ctrl.IvtrFetFltTyp -> PhaDiscnct.IvtrFetFltTyp  # UB:Derived from original system description
    connect PhaDiscnct.PhaDiscnctDiagcActv -> CDD_TSG31CfgAndUse.PhaDiscnctDiagcActv  # UB:Derived from original system description
    connect PhaDiscnct.PhaDiscnctWrmIninTestCmpl -> PwrUpSeq.PhaDiscnctWrmIninTestCmpl  # UB:Derived from original system description
    connect PwrUpSeq.StrtUpSt -> PhaDiscnct.StrtUpSt  # UB:Derived from original system description
    connect SysStMod.SysSt -> PhaDiscnct.SysSt  # UB:Derived from original system description
    connect CDD_Bmw5441McuCfg.RvsBattDiagcGndAdc -> RvsBattProtn.RvsBattDiagcGndAdc  # UB:Derived from original system description
    connect CDD_Bmw5441McuCfg.RvsBattDiagcGndAdcFaild -> RvsBattProtn.RvsBattDiagcGndAdcFaild  # UB:Derived from original system description
    connect CDD_Bmw5441McuCfg.RvsBattDiagcRtnAdc -> RvsBattProtn.RvsBattDiagcRtnAdc  # UB:Derived from original system description
    connect CDD_Bmw5441McuCfg.RvsBattDiagcRtnAdcFaild -> RvsBattProtn.RvsBattDiagcRtnAdcFaild  # UB:Derived from original system description
    connect PhaDiscnct.PhaDiscnctDiagcActv -> CDD_MotCtrlMgr.PhaDiscnctDiagcActv  # UB:Derived from original system description
    connect PhaDiscnct.PhaDiscnctDiagcPwmVect -> CDD_MotCtrlMgr.PhaDiscnctDiagcPwmVect  # UB:Derived from original system description
    connect IoHwAb.SetGpioPhaDiscnctA -> PhaDiscnct.IoHwAb_SetGpioPhaDiscnctA  # UB:Derived from original system description
    connect IoHwAb.SetGpioPhaDiscnctB -> PhaDiscnct.IoHwAb_SetGpioPhaDiscnctB  # UB:Derived from original system description
    connect IoHwAb.SetGpioPhaDiscnctC -> PhaDiscnct.IoHwAb_SetGpioPhaDiscnctC  # UB:Derived from original system description
    connect DiagcMgrProxyAppl10.GetNtcQlfrSts10 -> BattVltgCorrln.GetNtcQlfrSts  # UB:Derived from original system description
    connect DiagcMgrProxyAppl10.GetNtcQlfrSts10 -> CDD_CurrMeas.GetNtcQlfrSts  # UB:Derived from original system description
    connect CmnMfgSrv.LoaScaDi -> LoaMgr.LoaScaDi  # UB:Derived from original system description
    connect CurrMeasCorrln.CurrMeasIdptSig -> LoaMgr.CurrMeasIdptSig  # UB:Derived from original system description
    connect DiagcMgrProxyAppl10.SetNtcSts10 -> LoaMgr.SetNtcSts  # UB:Derived from original system description
    connect GateDrv0Ctrl.DiagcStsIvtr1Inactv -> LoaMgr.DiagcStsIvtr1Inactv  # UB:Derived from original system description
    connect GateDrv0Ctrl.IvtrFetFltTyp -> LoaMgr.IvtrFetFltTyp  # UB:Derived from original system description
    connect HwTqCorrln.HwTqIdptSig -> LoaMgr.HwTqIdptSig  # UB:Derived from original system description
    connect LoaMgr.MotAndThermProtnLoaMod -> DutyCycThermProtn.MotAndThermProtnLoaMod  # UB:Derived from original system description
    connect LoaMgr.MotAndThermProtnLoaMod -> ElecPwrCns.MotAndThermProtnLoaMod  # UB:Derived from original system description
    connect LoaMgr.MotAndThermProtnLoaMod -> HiLoadStallLimr.MotAndThermProtnLoaMod  # UB:Derived from original system description
    connect LoaMgr.MotAndThermProtnLoaMod -> MotCtrlPrmEstimn.MotAndThermProtnLoaMod  # UB:Derived from original system description
    connect LoaMgr.MotAndThermProtnLoaMod -> MotCurrPeakEstimn.MotAndThermProtnLoaMod  # UB:Derived from original system description
    connect LoaMgr.MotAndThermProtnLoaMod -> MotCurrRegCfg.MotAndThermProtnLoaMod  # UB:Derived from original system description
    connect LoaMgr.MotAndThermProtnLoaMod -> MotRefMdl.MotAndThermProtnLoaMod  # UB:Derived from original system description
    connect LoaMgr.LoaSt -> MotTqTranlDampg.LoaSt  # UB:Derived from original system description
    connect LoaMgr.MotAndThermProtnLoaMod -> PwrLimr.MotAndThermProtnLoaMod  # UB:Derived from original system description
    connect LoaMgr.LoaRateLim -> StOutpCtrl.LoaRateLim  # UB:Derived from original system description
    connect LoaMgr.LoaSca -> StOutpCtrl.LoaSca  # UB:Derived from original system description
    connect LoaMgr.MotAndThermProtnLoaMod -> TEstimn.MotAndThermProtnLoaMod  # UB:Derived from original system description
    connect MotAgCorrln.MotAgMeclIdptSig -> LoaMgr.MotAgMeclIdptSig  # UB:Derived from original system description
    connect CDD_MotCtrlMgr.MotCurrDax -> ElecPwrCns.MotCurrDax  # UB:Derived from original system description
    connect CDD_MotCtrlMgr.MotCurrQax -> ElecPwrCns.MotCurrQax  # UB:Derived from original system description
    connect LoaMgr.MotAndThermProtnLoaMod -> CDD_MotCtrlMgr.MotAndThermProtnLoaMod  # UB:Derived from original system description
    connect NvMProxy.PSProxy_Rte_NvmBlock_TEstimn_TFilStVal -> TEstimn.TFilStVal
    connect DiagcMgr.CnvSnpshtData_f32 -> CDD_BattRtnCurr.CnvSnpshtData_f32  # UB:Derived from original system description
    connect DiagcMgr.CnvSnpshtData_u08 -> CDD_BattRtnCurr.CnvSnpshtData_u08  # UB:Derived from original system description
    connect DiagcMgrProxyAppl8.GetNtcQlfrSts8 -> CDD_BattRtnCurr.GetNtcQlfrSts  # UB:Derived from original system description
    connect DiagcMgrProxyAppl8.SetNtcStsAndSnpshtData8 -> CDD_BattRtnCurr.SetNtcStsAndSnpshtData  # UB:Derived from original system description
    connect ElecPwrCns.SplyCurrEstim -> CDD_BattRtnCurr.SplyCurrEstim  # UB:Derived from original system description
    connect SysStMod.SysSt -> CDD_BattRtnCurr.SysSt  # UB:Derived from original system description
    connect CDD_Bmw5441McuCfg.BattRtnCurrAdcFaild -> CDD_BattRtnCurr.BattRtnCurrAdcFaild  # UB:Derived from original system description
    connect CDD_MotCtrlMgr.BattRtnCurrAdc -> CDD_BattRtnCurr.BattRtnCurrAdc  # UB:Derived from original system description
    connect CDD_MotCtrlMgr.MotVltgDax -> ElecPwrCns.MotVltgDax  # UB:Derived from original system description
    connect CDD_MotCtrlMgr.MotVltgQax -> ElecPwrCns.MotVltgQax  # UB:Derived from original system description
    connect BmwMsgSlot55Bas3Repn4BusFrChA.BmwCogVehSpd -> BmwVehSpd.BmwCogVehSpd  # UB:Derived from original system description
    connect BmwMsgSlot55Bas3Repn4BusFrChA.BmwCogVehSpdVld -> BmwVehSpd.BmwCogVehSpdVld  # UB:Derived from original system description
    connect BmwMsgSlot55Bas3Repn4BusFrChA.BmwNearStillVehSpdSts -> BmwVehSpd.BmwNearStillVehSpdSts  # UB:Derived from original system description
    connect BmwMsgSlot55Bas3Repn4BusFrChA.BmwNearStillVehSpdStsVld -> BmwVehSpd.BmwNearStillVehSpdStsVld  # UB:Derived from original system description
    connect BmwVehSpd.VehSpd -> BmwDiagcSrvHndlg.VehSpd  # UB:Derived from original system description
    connect BmwVehSpd.VehSpd -> BmwHwAgArbnAndEotPosn.VehSpd  # UB:Derived from original system description
    connect BmwVehSpd.VehSpdVld -> BmwHwAgArbnAndEotPosn.VehSpdVld  # UB:Derived from original system description
    connect BmwVehSpd.VehSpd -> BmwStReqMgr.VehSpd  # UB:Derived from original system description
    connect BmwVehSpd.VehSpd -> CDD_CurrMeas.VehSpd  # UB:Derived from original system description
    connect BmwVehSpd.VehSpdVld -> CDD_CurrMeas.VehSpdVld  # UB:Derived from original system description
    connect BmwVehSpd.VehSpd -> CDD_MotCtrlMgr.VehSpd  # UB:Derived from original system description
    connect BmwVehSpd.VehSpd -> CtrldVelRtn.VehSpd  # UB:Derived from original system description
    connect BmwVehSpd.VehSpd -> EotProtn.VehSpd  # UB:Derived from original system description
    connect BmwVehSpd.VehSpd -> LimrCdng.VehSpd  # UB:Derived from original system description
    connect BmwVehSpd.VehSpd -> MotCurrRegCfg.VehSpd  # UB:Derived from original system description
    connect BmwVehSpd.VehSpd -> MotTqTranlDampg.VehSpd  # UB:Derived from original system description
    connect BmwVehSpd.VehSpd -> PosnTrakgServo.VehSpd  # UB:Derived from original system description
    connect BmwVehSpd.VehSpd -> Swp.VehSpd  # UB:Derived from original system description
    connect BmwVehSpd.VehSpdVld -> Swp.VehSpdVld  # UB:Derived from original system description
    connect BmwVehSpd.VehSpd -> SysFricLrng.VehSpd  # UB:Derived from original system description
    connect BmwVehSpd.VehSpdVld -> SysFricLrng.VehSpdVld  # UB:Derived from original system description
    connect BmwVehSpd.VehSpd -> TunSelnAuthy.VehSpd  # UB:Derived from original system description
    connect BmwVehSpd.VehSpd -> VehSpdLimr.VehSpd  # UB:Derived from original system description
    connect NvMProxy.PSProxy_NVM_BLOCK_DLOG_SVK_ENTRY -> Dlog.NvMService_DlogSvkEntry
    connect BswM.Switch_StdDiagSessionChangeIndicationPort -> StdDiag.SessionChangeIndicationPort
    connect Dcm.DCMServices -> StdDiag.DCMServicesPort
    connect BswM.Switch_StdDiagComControlNormalNotificationPort -> StdDiag.ComControlNormalModeAccessPort
    connect StdDiag.ComControlModeRequestPort -> BswM.Request_StdDiag_ComControlModeRequest
    connect Omc.StdDiagCbk -> StdDiag.AllowOpModeChangeCbkPort  # UB:Derived from original system description
    connect StdDiag.AllowOpModeChangePort -> Omc.StdDiag  # UB:Derived from original system description
    connect Omc.extendedOperatingModeSwitchPort -> StdDiag.ExtendedOperatingModeControlPort  # UB:Derived from original system description
    connect Omc.operatingModeSwitchPort -> StdDiag.OperatingModeControlPort  # UB:Derived from original system description
    connect Darh.RoeStatePort -> StdDiag.RoeStatePort  # UB:Derived from original system description
    delegate Stm.EnergyModeRx <-> outer port ST_ENERG_FZM  # UB:Derived from original system description
    delegate Stm.CentralErrorLockRx <-> outer port ST_ILK_ERRM_FZM  # UB:Derived from original system description
    connect BswM.Switch_ErrorMemoryLockSignalReceptionSwitchPort -> Stm.EMLockSignalReceptionModeNotificationPort
    connect Darh.DmClientTriggerDtcEntry -> Dcm.RoutineServices_DmClientTriggerDtcEntry_Routine
    connect NvM.PS_Rte_NvmBlock_Darh_ErrorQueue -> Darh.ErrorQueueBlock
    connect Darh.StartStopRoutineDiagnoseMaster -> Dcm.RoutineServices_DarhStrtStop_Routine
    connect Omc.ExtendedEnergySavingState -> Dcm.DataServices_DID_100E_ExtendedEnergySavingState
    connect Omc.EnergySavingState -> Dcm.DataServices_DID_100A_EnergySavingState
    connect Omc.ControlExtendedEnergySavingState -> Dcm.RoutineServices_ControlExtendedEnergySavingState_Routine
    connect Omc.ControlEnergySavingState -> Dcm.RoutineServices_Energiesparmode_Routine
    connect StdDiag.DiagCommLoopback -> Dcm.RoutineServices_DiagCommLoopback_Routine
    connect StdDiag.SgbdIndex -> Dcm.DataServices_DID_F150_SgbdIdx
    connect StdDiag.CheckProgrammingPreconditions -> Dcm.RoutineServices_RcCppc_Routine
    connect StdDiag.ActiveSessionState -> Dcm.DataServices_DID_F100_ReadActiveSessionState
    connect StdDiag.ClearSecondaryErrorMemory -> Dcm.RoutineServices_IsLoeschen_Routine
    connect StdDiag.LifeCycle -> BswM.Notification_SwcModeNotification_StdDiag_LifeCycle
    connect BmwDiagcSrvHndlg.DataServices_DID_DB57_EpsRitzelwinkelsensor -> Dcm.DataServices_DID_DB57_EpsRitzelwinkelsensor
    connect BmwDiagcSrvHndlg.DataServices_DID_DB5A_EpsLenkwinkelsensorKalibrierung -> Dcm.DataServices_DID_DB5A_EpsLenkwinkelsensorKalibrierung
    connect BmwDiagcSrvHndlg.DataServices_DID_DFDD_GelernterZahnstangenweg -> Dcm.DataServices_DID_DFDD_GelernterZahnstangenweg
    connect BmwDiagcSrvHndlg.RoutineServices_EpsInitialisierungWerk_Routine -> Dcm.RoutineServices_EpsInitialisierungWerk_Routine
    connect BmwDiagcSrvHndlg.RoutineServices_EpsLenkwinkelsensorKalibrierungReset_Routine -> Dcm.RoutineServices_EpsLenkwinkelsensorKalibrierungReset_Routine
    connect BmwDiagcSrvHndlg.RoutineServices_EpsZahnstangenmitteReset_Routine -> Dcm.RoutineServices_EpsZahnstangenmitteReset_Routine
    connect BmwDiagcSrvHndlg.RoutineServices_SteuernEpsMultiturnwertReset_Routine -> Dcm.RoutineServices_SteuernEpsMultiturnwertReset_Routine
    connect Dlog.SvkCurrent -> Dcm.DataServices_DID_F101_SvkAktuell
    connect Dlog.FlashTimingParameter -> Dcm.DataServices_DID_2504_FlashTimingParameter
    connect Omc.NvMNotifyJobFinished -> NvM.NvM_RpNotifyJobEnd_Rte_NvmBlock_Omc
    connect Dcm.DcmCommunicationControl_ComMConf_ComMChannel_A_FlexRay_372befd6 -> BswM.Notification_SwcModeNotification_DcmCommunicationControl_ComMConf_ComMChannel_A_FlexRay_372befd6
    connect StdDiag.ServiceRequestManufacturerNotificationPort -> Dcm.ServiceRequestManufacturerNotification_StdDiag
    connect Rmh_Cdd.TriggerIPDUSend -> Rmh.TriggerIPDUSend  # UB:Derived from original system description
    delegate Rmh.RxRequestedMsgID <-> outer port ANFRAGE_ID2  # UB:Derived from original system description
    delegate SysTime.SysTimeRx <-> outer port T_SEC_COU_REL  # UB:Derived from original system description
    connect SysTime.SystemTime -> Dcm.DataServices_DID_1701_Systemzeit
    connect Darh.EventDataChangedPort -> DemMaster_0.GeneralCBDataEvt
    connect DemMaster_0.EnableCond_DemEnableCondition_StdDiag -> StdDiag.EnableConditionPort
    connect DemSatellite_0.Event_DmTestAppl -> Darh.DmTestAppl
    connect DemSatellite_0.Event_DmTestCom -> Darh.DmTestCom
    connect Coding.Notification -> Dcm.ServiceRequestManufacturerNotification_Coding
    connect CmnMfgSrv.CmnMfgSrvCmnMfgSrvMaiFct -> CmnMfgSrvIf.CmnMfgSrvCmnMfgSrvMaiFct  # UB:Derived from original system description
    connect Coding.SVK -> Dlog.Coding_Svk
    connect Dlog.EcuInfo -> Vin.DlogEcuInfo
    connect Dlog.ProgId -> Coding.ProgId
    connect Dlog.SvkSysSupplier -> Dcm.DataServices_DID_F102_SvkSysSupplier
    connect Dlog.SvkPlant -> Dcm.DataServices_DID_F103_SvkWerk
    connect Dlog.HWModificationIndex -> Dcm.DataServices_DID_F152_Readhwmodificationindex
    connect Dlog.EcuSerialNumber -> Dcm.DataServices_DID_F18C_EcuSerialNumber
    connect Dlog.DevelopmentInfoField -> Dcm.RoutineServices_RcRswedi_Routine
    connect NvM.PS_NVM_BLOCK_BOOT_SVK_HISTORY -> Dlog.NvMService_DlogSvkHistory
    connect Dlog.NvMNotifyJobFinished_SvkEntry -> NvM.NvM_RpNotifyJobEnd_NVM_BLOCK_DLOG_SVK_ENTRY
    connect Dlog.NvMNotifyJobFinished_DlogProgData -> NvM.NvM_RpNotifyJobEnd_NVM_BLOCK_BOOT_PROG_DATA
    connect Dlog.ManufacturingDate -> Dcm.DataServices_DID_F18B_Herstelldatum
    connect Dlog.InitBlockProgData -> NvM.NvM_RpNotifyInit_NVM_BLOCK_BOOT_PROG_DATA
    connect Darh.DmIsDtcActiveResponse -> Dcm.DataServices_DID_1723_DmIsDtcActiveResponse
    connect NvM.PS_Rte_NvmBlock_Darh_DiagnoseMasterEnable -> Darh.DiagnoseMasterStatus
    connect Darh.NvMNotifyJobFinished -> NvM.NvM_RpNotifyJobEnd_Rte_NvmBlock_Darh_DiagnoseMasterEnable
    connect DemWrapper.DemWrapper_ApplicationDTCInfoPort -> Darh.ApplicationDTCInfoPort
    connect DemWrapper.DemWrapper_Darh_GeneralDiagnosticInfo -> Darh.GeneralDiagnosticInfoPort
    connect DemWrapper.DemWrapper_NetworkDTCInfoPort -> Darh.NetworkDTCInfoPort
    connect DemSatellite_0.GeneralEventInfo -> DemWrapper.DemWrapper_GeneralDiagnosticInfo
    connect DemSatellite_0.EvtInfo_DmTestCom -> DemWrapper.DemWrapper_EvtInfo_DM_TEST_COM
    connect DemSatellite_0.EvtInfo_DmTestAppl -> DemWrapper.DemWrapper_EvtInfo_DM_TEST_APPL
    connect DemWrapper.DemWrapper_CddIf -> StdDiag.ClearDTCPort
    connect DemMaster_0.ClearDTC_DemClient_CDD -> DemWrapper.DemWrapper_ClearDTC
    connect BswM.Switch_SwitchPort_Darh_ReportErrorMode -> Darh.ReportErrorMode
    connect DemMaster_0.EnableCond_DemEnableCondition_Stm -> Stm.CentralErrorLockEnableCondition
    connect Stm.CentralErrorLockModeSwitchPort -> BswM.Notification_SWCModeSwitch_currentCentralErrorLockMode
    connect Coding.CBClrEvt_EventNotCoded -> DemMaster_0.CBClrEvt_CodingEventNotCoded
    connect DemMaster_0.EnableCond_DemEnableCondition_Omc -> Omc.EnableCond_OMC
    connect SysTime.SystemTime -> DemMaster_0.CBReadData_DID_1701_Systemzeit
    connect Darh.LifeCycle -> BswM.Notification_SwcModeNotification_Darh_LifeCycle
    connect Coding.LifeCycle -> BswM.Notification_SwcModeNotification_Coding_LifeCycle
    connect BswM.Provide_MSRP_StdDiag -> StdDiag.LifeCycleRequest
    connect BswM.Provide_MSRP_Dlog -> Dlog.LifeCycleRequest
    connect BswM.Provide_MSRP_Omc -> Omc.LifeCycleRequest
    connect BswM.Provide_MSRP_Darh -> Darh.LifeCycleRequest
    connect BswM.Provide_MSRP_Coding -> Coding.LifeCycleRequest
    connect BswM.Provide_MSRP_SysTime -> SysTime.LifeCycleRequest
    connect Omc.ClearEventAllowedPort -> DemMaster_0.CBClrEvt_VsmEventOpmode
    connect DemSatellite_0.Event_VsmEventOpmode -> Omc.VsmEventOpmode
    connect BswM.Provide_MSRP_Vin -> Vin.LifeCycleRequest
    connect Vin.Vin -> Coding.Vin  # UB:Derived from original system description
    connect DemSatellite_0.Event_CodingEventNotCoded -> Coding.EventNotCoded
    connect DemSatellite_0.Event_CodingEventWrongVehicle -> Coding.EventWrongVehicle
    connect Coding.WriteNCD -> Dcm.RoutineServices_WriteNcd_Routine
    connect Coding.ReadNCD -> Dcm.RoutineServices_ReadNcd_Routine
    connect Coding.ReadProtocolData -> Dcm.DataServices_DID_37FF_ReadProtocolData
    connect Coding.ReadCPS -> Dcm.DataServices_DID_37FE_Cps
    connect Coding.CheckNCD -> Dcm.RoutineServices_CheckNcd_Routine
    connect BmwDiagcSrvHndlg.DataServices_DID_F18A_SystemSupplierIdentifier -> Dcm.DataServices_DID_F18A_SystemSupplierIdentifier
    connect BmwTunSetHndlr.TunVrntRead -> ProgMfgSrv.TunVrntRead  # UB:Derived from original system description
    connect BmwTunSetHndlr.TunVrntWr -> ProgMfgSrv.TunVrntWr  # UB:Derived from original system description
    connect BmwTunSetHndlr.DesIninIdx -> TunSelnMngt.DesIninIdx  # UB:Derived from original system description
    connect BmwTunSetHndlr.DesRtIdx -> TunSelnMngt.DesRtIdx  # UB:Derived from original system description
    connect NvMProxy.PSProxy_Rte_NvmBlock_BmwTunSetHndlr_BmwDesIninIdx -> BmwTunSetHndlr.BmwDesIninIdx
    connect DiagcMgrProxyAppl10.SetNtcSts10 -> BmwTunSetHndlr.SetNtcSts  # UB:Derived from original system description
    connect Coding.NvMNotifyJobFinished -> NvM.NvM_RpNotifyJobEnd_Rte_NvmBlock_Coding_CodingData
    connect NvM.PS_Rte_NvmBlock_Coding_CodingData -> Coding.NvMService
    connect BswM.Switch_Coding_BusComModeSwitch -> Coding.BusCom
    connect CDD_NxtrTi.GetRefTmr100MicroSec32bit -> BmwTunSetHndlr.GetRefTmr100MicroSec32bit  # UB:Derived from original system description
    connect CDD_NxtrTi.GetTiSpan100MicroSec32bit -> BmwTunSetHndlr.GetTiSpan100MicroSec32bit  # UB:Derived from original system description
    connect FltInj.FltInj_f32 -> TqOscn.FltInj_f32  # UB:Derived from original system description
    connect BmwHwAgArbnAndEotPosn.PinionAg -> SysKineAndEff.PinionAg  # UB:Derived from original system description
    connect BmwVehSpd.VehSpd -> ClsdLoopDampg.VehSpd  # UB:Derived from original system description
    connect BmwVehSpd.VehSpd -> Effort.VehSpd  # UB:Derived from original system description
    connect BmwVehSpd.VehSpd -> HwTqTrakgCtrl.VehSpd  # UB:Derived from original system description
    connect CDD_MotAgCmp.MotAgCumvAlgndMrf -> SysKineAndEff.MotAgCumvAlgndMrf  # UB:Derived from original system description
    connect CDD_MotCtrlMgr.MotCurrDax -> MotTqCalcd.MotCurrDax  # UB:Derived from original system description
    connect CDD_MotCtrlMgr.MotCurrQax -> MotTqCalcd.MotCurrQax  # UB:Derived from original system description
    connect CDD_MotVel.MotVelCrf -> EpsStEstimn.MotVelCrf  # UB:Derived from original system description
    connect CDD_MotVel.MotVelCrf -> SysKineAndEff.MotVelCrf  # UB:Derived from original system description
    connect Effort.HwTqCmdEffort -> HwRefTqSum.HwTqCmdEffort  # UB:Derived from original system description
    connect EpsStEstimn.RackFEstimd -> ClsdLoopDampg.RackFEstimd  # UB:Derived from original system description
    connect EpsStEstimn.RackFEstimd -> Effort.RackFEstimd  # UB:Derived from original system description
    connect EpsStEstimn.TorsBarStEstimd -> HwTqTrakgCtrl.TorsBarStEstimd  # UB:Derived from original system description
    connect HwRefTqSum.HwTqCmdSum -> HwTqTrakgCtrl.HwTqCmd  # UB:Derived from original system description
    connect LoaMgr.MotAndThermProtnLoaMod -> MotTqCalcd.MotAndThermProtnLoaMod  # UB:Derived from original system description
    connect MotCtrlPrmEstimn.MotBackEmfConEstimd -> MotTqCalcd.MotBackEmfConEstimd  # UB:Derived from original system description
    connect MotCtrlPrmEstimn.MotInduDaxEstimd -> MotTqCalcd.MotInduDaxEstimd  # UB:Derived from original system description
    connect MotCtrlPrmEstimn.MotInduQaxEstimd -> MotTqCalcd.MotInduQaxEstimd  # UB:Derived from original system description
    connect MotRefMdl.MotCurrDaxCmd -> MotTqCalcd.MotCurrDaxCmd  # UB:Derived from original system description
    connect MotRefMdl.MotCurrQaxCmd -> MotTqCalcd.MotCurrQaxCmd  # UB:Derived from original system description
    connect MotTqCalcd.MotTqEstimd -> EpsStEstimn.MotTqEstimd  # UB:Derived from original system description
    connect SysKineAndEff.HwVel -> BmwDiagcSrvHndlg.HwVel  # UB:Derived from original system description
    connect SysKineAndEff.PinionVel -> ClsdLoopDampg.PinionVel  # UB:Derived from original system description
    connect SysKineAndEff.HwVel -> CtrldVelRtn.HwVel  # UB:Derived from original system description
    connect SysKineAndEff.PinionTqToRackFInstsRat -> EpsStEstimn.PinionTqToRackFInstsRat  # UB:Derived from original system description
    connect SysKineAndEff.SysKineRat -> EpsStEstimn.SysKineRat  # UB:Derived from original system description
    connect SysKineAndEff.SysTqRat -> EpsStEstimn.SysTqRat  # UB:Derived from original system description
    connect SysKineAndEff.HwVel -> FltInj.HwVel  # UB:Derived from original system description
    connect SysKineAndEff.SysTqRat -> HwTqTrakgCtrl.SysTqRat  # UB:Derived from original system description
    connect SysKineAndEff.HwVel -> SysFricLrng.HwVel  # UB:Derived from original system description
    connect SysKineAndEff.HwVel -> TEstimn.HwVel  # UB:Derived from original system description
    connect SysKineAndEff.HwVel -> TunSelnAuthy.HwVel  # UB:Derived from original system description
    connect PolarityCfg.MotAgMecl3Polarity -> CDD_MotAg3Meas.MotAgMecl3Polarity  # UB:Derived from original system description
    connect PolarityCfg.MotAgMecl4Polarity -> CDD_MotAg4Meas.MotAgMecl4Polarity  # UB:Derived from original system description
    connect DiagcMgrProxyAppl10.SetNtcSts10 -> BmwMsgSlot68Bas0Repn2BusFrChA.SetNtcSts  # UB:Derived from original system description
    delegate BmwMsgSlot53Bas3Repn8BusFrChA.FACT_MO_STE_SO_DXP <-> outer port FACT_MO_STE_SO_DXP  # UB:Derived from original system description
    delegate BmwMsgSlot276Bas4Repn8BusFrChA.MILE_KM <-> outer port MILE_KM  # UB:Derived from original system description
    delegate BmwMsgSlot55Bas0Repn2BusFrChA.sigGroup_ACLNY_MASSCNTR <-> outer port sigGroup_ACLNY_MASSCNTR  # UB:Derived from original system description
    delegate BmwMsgSlot234Bas1Repn2BusFrChA.sigGroup_ST_EST <-> outer port sigGroup_ST_EST  # UB:Derived from original system description
    delegate BmwMsgSlot274Bas0Repn8BusFrChA.sigGroup_SU_EPS <-> outer port sigGroup_SU_EPS  # UB:Derived from original system description
    delegate BmwMsgSlot68Bas0Repn2BusFrChA.sigGroup_TAR_QTA_STRMOM_DV <-> outer port sigGroup_TAR_QTA_STRMOM_DV  # UB:Derived from original system description
    delegate BmwMsgSlot68Bas0Repn2BusFrChA.sigGroup_TAR_STMOM_DV_ACT <-> outer port sigGroup_TAR_STMOM_DV_ACT  # UB:Derived from original system description
    delegate BmwMsgSlot56Bas0Repn2BusFrChA.sigGroup_VYAW_VEH <-> outer port sigGroup_VYAW_VEH  # UB:Derived from original system description
    delegate BmwMsgSlot53Bas3Repn8BusFrChA.SU_CLU_STMOM_SFE_DXP <-> outer port SU_CLU_STMOM_SFE_DXP  # UB:Derived from original system description
    connect DiagcMgrProxyAppl10.SetNtcSts10 -> BmwMsgSlot276Bas4Repn8BusFrChA.SetNtcSts  # UB:Derived from original system description
    connect DiagcMgrProxyAppl10.SetNtcSts10 -> BmwMsgSlot53Bas3Repn8BusFrChA.SetNtcSts  # UB:Derived from original system description
    connect DiagcMgrProxyAppl10.SetNtcSts10 -> BmwMsgSlot55Bas0Repn2BusFrChA.SetNtcSts  # UB:Derived from original system description
    connect DiagcMgrProxyAppl10.SetNtcSts10 -> BmwMsgSlot56Bas0Repn2BusFrChA.SetNtcSts  # UB:Derived from original system description
    connect CDD_Bmw5441McuCfg.MotDrvr1IninTestCmpl -> PwrUpSeq.MotDrvr1IninTestCmpl  # UB:Derived from original system description
    connect BmwMsgSlot53Bas3Repn8BusFrChA.BmwRtIdx -> BmwTunSetHndlr.BmwRtIdx  # UB:Derived from original system description
    connect BmwMsgSlot53Bas3Repn8BusFrChA.BmwRtIdxVld -> BmwTunSetHndlr.BmwRtIdxVld  # UB:Derived from original system description
    connect BmwMsgSlot55Bas0Repn2BusFrChA.BmwVehLatA -> VehSigCdng.VehLatASerlCom  # UB:Derived from original system description
    connect BmwMsgSlot55Bas0Repn2BusFrChA.BmwVehLatAVld -> VehSigCdng.VehLatAVldSerlCom  # UB:Derived from original system description
    connect BmwMsgSlot56Bas0Repn2BusFrChA.BmwVehYawRate -> VehSigCdng.VehYawRateSerlCom  # UB:Derived from original system description
    connect BmwMsgSlot56Bas0Repn2BusFrChA.BmwVehYawRateVld -> VehSigCdng.VehYawRateVldSerlCom  # UB:Derived from original system description
    connect HwTqArbn.HwTq -> CmnMfgSrv.HwTq  # UB:Derived from original system description
    connect HwTqArbn.HwTq -> CmplncErr.HwTq  # UB:Derived from original system description
    connect HwTqArbn.HwTq -> DiagcMgr.HwTq  # UB:Derived from original system description
    connect HwTqArbn.HwTq -> EotProtn.HwTq  # UB:Derived from original system description
    connect HwTqArbn.HwTq -> PosnTrakgServo.HwTq  # UB:Derived from original system description
    connect HwTqArbn.HwTq -> SysFricLrng.HwTq  # UB:Derived from original system description
    connect HwTqArbn.HwTq -> TunSelnAuthy.HwTq  # UB:Derived from original system description
    connect HwTqArbn.HwTq -> VehSigCdng.HwTq  # UB:Derived from original system description
    connect DiagcMgr.CnvSnpshtData_s16 -> CDD_MotAg0Meas.CnvSnpshtData_s16  # UB:Derived from original system description
    connect DiagcMgr.CnvSnpshtData_u16 -> CDD_MotAg0Meas.CnvSnpshtData_u16  # UB:Derived from original system description
    connect DiagcMgrProxyAppl10.SetNtcStsAndSnpshtData10 -> CDD_MotAg0Meas.SetNtcStsAndSnpshtData  # UB:Derived from original system description
    connect CDD_MotCtrlMgr.MotAg0SpiMecl -> CDD_MotAg0Meas.MotAg0SpiMecl  # UB:Derived from original system description
    connect CDD_MotCtrlMgr.MotAg3Mecl -> CDD_MotAg0Meas.MotAg3Mecl  # UB:Derived from original system description
    connect CDD_MotAg0Meas.MotAg0QepFaild -> CDD_MotCtrlMgr.MotAg0QepFaild  # UB:Derived from original system description
    connect DiagcMgr.CnvSnpshtData_s16 -> CDD_MotAg1Meas.CnvSnpshtData_s16  # UB:Derived from original system description
    connect DiagcMgr.CnvSnpshtData_u16 -> CDD_MotAg1Meas.CnvSnpshtData_u16  # UB:Derived from original system description
    connect DiagcMgrProxyAppl10.SetNtcStsAndSnpshtData10 -> CDD_MotAg1Meas.SetNtcStsAndSnpshtData  # UB:Derived from original system description
    connect CDD_MotAg1Meas.MotAg1QepFaild -> CDD_MotCtrlMgr.MotAg1QepFaild  # UB:Derived from original system description
    connect CDD_MotCtrlMgr.MotAg1SpiMecl -> CDD_MotAg1Meas.MotAg1SpiMecl  # UB:Derived from original system description
    connect CDD_MotCtrlMgr.MotAg4Mecl -> CDD_MotAg1Meas.MotAg4Mecl  # UB:Derived from original system description
    connect BmwVehSpd.VehSpd -> GlbLimr.VehSpd  # UB:Derived from original system description
    connect DiagcMgrProxyAppl10.SetNtcSts10 -> BmwMsgSlot108Bas0Repn2BusFrChA.SetNtcSts  # UB:Derived from original system description
    connect HwTqTrakgCtrl.MotTqCmdTrakgCtrl -> GlbLimr.MotTqCmd  # UB:Derived from original system description
    connect Swp.HwTqSwp -> CtrldVelRtn.HwTq  # UB:Derived from original system description
    connect Swp.HwTqSwp -> EpsStEstimn.HwTq  # UB:Derived from original system description
    connect Swp.HwTqSwp -> GlbLimr.HwTq  # UB:Derived from original system description
    connect Swp.MotTqCmdSwp -> MotTqTranlDampg.MotTqCmdCrf  # UB:Derived from original system description
    delegate BmwMsgSlot108Bas0Repn2BusFrChA.AVL_STEA_PNI_OFFS <-> outer port AVL_STEA_PNI_OFFS  # UB:Derived from original system description
    connect DiagcMgrProxyAppl7.GetNtcQlfrSts7 -> RvsBattProtn.GetNtcQlfrSts  # UB:Derived from original system description
    connect DiagcMgrProxyAppl7.SetNtcStsAndSnpshtData7 -> RvsBattProtn.SetNtcStsAndSnpshtData  # UB:Derived from original system description
    connect BmwVehSpd.VehSpd -> VehSigCdng.VehSpdSerlCom  # UB:Derived from original system description
    connect BmwVehSpd.VehSpdVld -> VehSigCdng.VehSpdVldSerlCom  # UB:Derived from original system description
    connect CDD_BattRtnCurr.BattRtnCurrAmpr -> BmwMsgSlot49Bas1Repn2BusFrChA.BattRtnCurrAmpr  # UB:Derived from original system description
    connect CDD_BattRtnCurr.BattRtnCurrStsQlfr -> BmwMsgSlot49Bas1Repn2BusFrChA.BattRtnCurrAmprQlfr  # UB:Derived from original system description
    connect DiagcMgrProxyAppl10.SetNtcSts10 -> BmwMsgSlot269Bas2Repn4BusFrChA.SetNtcSts  # UB:Derived from original system description
    connect DiagcMgrProxyAppl10.SetNtcSts10 -> BmwMsgSlot68Bas1Repn2BusFrChA.SetNtcSts  # UB:Derived from original system description
    connect IoHwAb.SetFctGpioMotAg0Clk -> CDD_MotAg0Meas.IoHwAb_SetFctGpioMotAg0Clk  # UB:Derived from original system description
    connect IoHwAb.SetFctGpioMotAg0Cs -> CDD_MotAg0Meas.IoHwAb_SetFctGpioMotAg0Cs  # UB:Derived from original system description
    connect IoHwAb.SetFctGpioMotAg0Mosi -> CDD_MotAg0Meas.IoHwAb_SetFctGpioMotAg0Mosi  # UB:Derived from original system description
    connect IoHwAb.SetGpioMotAg0Clk -> CDD_MotAg0Meas.IoHwAb_SetGpioMotAg0Clk  # UB:Derived from original system description
    connect IoHwAb.SetGpioMotAg0Cs -> CDD_MotAg0Meas.IoHwAb_SetGpioMotAg0Cs  # UB:Derived from original system description
    connect IoHwAb.SetGpioMotAg0Mosi -> CDD_MotAg0Meas.IoHwAb_SetGpioMotAg0Mosi  # UB:Derived from original system description
    connect IoHwAb.SetFctGpioMotAg1Clk -> CDD_MotAg1Meas.IoHwAb_SetFctGpioMotAg1Clk  # UB:Derived from original system description
    connect IoHwAb.SetFctGpioMotAg1Cs -> CDD_MotAg1Meas.IoHwAb_SetFctGpioMotAg1Cs  # UB:Derived from original system description
    connect IoHwAb.SetFctGpioMotAg1Mosi -> CDD_MotAg1Meas.IoHwAb_SetFctGpioMotAg1Mosi  # UB:Derived from original system description
    connect IoHwAb.SetGpioMotAg1Clk -> CDD_MotAg1Meas.IoHwAb_SetGpioMotAg1Clk  # UB:Derived from original system description
    connect IoHwAb.SetGpioMotAg1Cs -> CDD_MotAg1Meas.IoHwAb_SetGpioMotAg1Cs  # UB:Derived from original system description
    connect IoHwAb.SetGpioMotAg1Mosi -> CDD_MotAg1Meas.IoHwAb_SetGpioMotAg1Mosi  # UB:Derived from original system description
    delegate BmwMsgSlot269Bas2Repn4BusFrChA.CTR_WARN_DIR_VIB_EPS <-> outer port CTR_WARN_DIR_VIB_EPS  # UB:Derived from original system description
    delegate BmwMsgSlot269Bas2Repn4BusFrChA.CTR_WARN_ILVL_VIB_EPS <-> outer port CTR_WARN_ILVL_VIB_EPS  # UB:Derived from original system description
    delegate BmwMsgSlot269Bas2Repn4BusFrChA.CTR_WARN_PTRN_VIB_EPS <-> outer port CTR_WARN_PTRN_VIB_EPS  # UB:Derived from original system description
    delegate BmwMsgSlot49Bas1Repn2BusFrChA.sigGroup_DT_EST <-> outer port sigGroup_DT_EST  # UB:Derived from original system description
    delegate BmwMsgSlot68Bas1Repn2BusFrChA.sigGroup_ENERG_DGR_DRDY <-> outer port sigGroup_ENERG_DGR_DRDY  # UB:Derived from original system description
    connect CDD_MotCtrlMgr.BattVltgAdc -> BattVltg.BattVltg  # UB:Derived from original system description
    connect CDD_MotCtrlMgr.BattVltgAdc -> BattVltgCorrln.BattVltg  # UB:Derived from original system description
    connect CDD_MotCtrlMgr.BattVltgAdc -> PwrDiscnct.BattVltg  # UB:Derived from original system description
    connect BmwDiagcSrvHndlg.LockToLockEna -> BmwMotTqOvrlArbn.PinionCentrLrnEna  # UB:Derived from original system description
    connect BmwDrvgDynStMac.DrvgDynIfSt -> BmwHwTqOvrlArbn.DrvgDynIfSt  # UB:Derived from original system description
    connect BmwDrvgDynStMac.DrvgDynActv -> BmwMotTqOvrlArbn.DrvgDynActv  # UB:Derived from original system description
    connect BmwDrvgDynStMac.DrvgDynIfSt -> BmwMsgSlot234Bas1Repn2BusFrChA.DrvgDynIfSt  # UB:Derived from original system description
    connect BmwDrvgDynStMac.DrvgDynActv -> BmwTqOvrlCdngAndDrvgDynFac.DrvgDynActv  # UB:Derived from original system description
    connect BmwDrvgDynStMac.DrvgDynIfSt -> BmwTqOvrlCdngAndDrvgDynFac.DrvgDynIfSt  # UB:Derived from original system description
    connect BmwDrvgDynStMac.OutpTqOvrlRampInEna -> BmwTqOvrlCdngAndDrvgDynFac.OutpTqOvrlRampInEna  # UB:Derived from original system description
    connect BmwHwTqOvrlArbn.HwTqCmdOvrl -> HwRefTqSum.HwTqCmdOvrl  # UB:Derived from original system description
    connect BmwMotTqOvrlArbn.MotTqOvrlCmd -> BmwDrvgDynStMac.MotTqOvrlCmd  # UB:Derived from original system description
    connect BmwMsgSlot121Bas1Repn2BusFrChA.BmwVehCdn -> BmwDrvgDynStMac.BmwVehCdn  # UB:Derived from original system description
    connect BmwMsgSlot55Bas3Repn4BusFrChA.BmwNearStillVehSpdSts -> BmwMotTqOvrlArbn.BmwNearStillVehSpdSts  # UB:Derived from original system description
    connect BmwMsgSlot68Bas0Repn2BusFrChA.BmwDrvgDynEnaRqst -> BmwDrvgDynStMac.BmwDrvgDynEnaReq  # UB:Derived from original system description
    connect BmwMsgSlot68Bas0Repn2BusFrChA.BmwDrvgDynFacQlfr -> BmwDrvgDynStMac.BmwDrvgDynFacQlfr  # UB:Derived from original system description
    connect BmwMsgSlot68Bas0Repn2BusFrChA.BmwDrvgDynFacQlfrVld -> BmwDrvgDynStMac.BmwDrvgDynFacQlfrVld  # UB:Derived from original system description
    connect BmwMsgSlot68Bas0Repn2BusFrChA.BmwTarHwTqOvrlQlfr -> BmwDrvgDynStMac.BmwTarHwTqOvrlQlfr  # UB:Derived from original system description
    connect BmwMsgSlot68Bas0Repn2BusFrChA.BmwTarHwTqOvrlQlfrVld -> BmwDrvgDynStMac.BmwTarHwTqOvrlQlfrVld  # UB:Derived from original system description
    connect BmwMsgSlot68Bas0Repn2BusFrChA.BmwTarSteerTqDrvrActrQlfr -> BmwDrvgDynStMac.BmwTarSteerTqDrvrActrQlfr  # UB:Derived from original system description
    connect BmwMsgSlot68Bas0Repn2BusFrChA.BmwTarSteerTqDrvrActrQlfrVld -> BmwDrvgDynStMac.BmwTarSteerTqDrvrActrQlfrVld  # UB:Derived from original system description
    connect BmwMsgSlot68Bas0Repn2BusFrChA.BmwTrfcJamAssiDampgStReq -> BmwDrvgDynStMac.BmwTrfcJamAssiDampgStReq  # UB:Derived from original system description
    connect BmwMsgSlot68Bas0Repn2BusFrChA.BmwTrfcJamAssiDampgStReqVld -> BmwDrvgDynStMac.BmwTrfcJamAssiDampgStReqVld  # UB:Derived from original system description
    connect BmwMsgSlot68Bas0Repn2BusFrChA.BmwDrvgDynErrIfActv -> BmwHwTqOvrlArbn.BmwDrvgDynErrIfActv  # UB:Derived from original system description
    connect BmwMsgSlot68Bas0Repn2BusFrChA.BmwTarHwTqOvrl -> BmwHwTqOvrlArbn.BmwTarHwTqOvrl  # UB:Derived from original system description
    connect BmwMsgSlot68Bas0Repn2BusFrChA.BmwTarHwTqOvrlQlfr -> BmwHwTqOvrlArbn.BmwTarHwTqOvrlQlfr  # UB:Derived from original system description
    connect BmwMsgSlot68Bas0Repn2BusFrChA.BmwDrvgDynDampgFacReq -> BmwTqOvrlCdngAndDrvgDynFac.BmwDrvgDynDampgFacReq  # UB:Derived from original system description
    connect BmwMsgSlot68Bas0Repn2BusFrChA.BmwDrvgDynEffortFacReq -> BmwTqOvrlCdngAndDrvgDynFac.BmwDrvgDynEffortFacReq  # UB:Derived from original system description
    connect BmwMsgSlot68Bas0Repn2BusFrChA.BmwDrvgDynErrIfActv -> BmwTqOvrlCdngAndDrvgDynFac.BmwDrvgDynErrIfActv  # UB:Derived from original system description
    connect BmwMsgSlot68Bas0Repn2BusFrChA.BmwDrvgDynRtnFacReq -> BmwTqOvrlCdngAndDrvgDynFac.BmwDrvgDynRtnFacReq  # UB:Derived from original system description
    connect BmwMsgSlot68Bas0Repn2BusFrChA.BmwTarSteerTqDrvrActr -> BmwTqOvrlCdngAndDrvgDynFac.BmwTarSteerTqDrvrActr  # UB:Derived from original system description
    connect BmwMsgSlot68Bas0Repn2BusFrChA.BmwTrfcJamAssiDampgScaReq -> BmwTrfcJamAssiDampg.BmwTrfcJamAssiDampgScaReq  # UB:Derived from original system description
    connect BmwMsgSlot68Bas0Repn2BusFrChA.BmwTrfcJamAssiDampgStReq -> BmwTrfcJamAssiDampg.BmwTrfcJamAssiDampgStReq  # UB:Derived from original system description
    connect BmwMsgSlot68Bas0Repn2BusFrChA.BmwTrfcJamAssiDampgStReqVld -> BmwTrfcJamAssiDampg.BmwTrfcJamAssiDampgStReqVld  # UB:Derived from original system description
    connect BmwStReqMgr.StsSteerAssi -> BmwDrvgDynStMac.StsSteerAssi  # UB:Derived from original system description
    connect BmwTqOvrlCdngAndDrvgDynFac.DampgCmdSca -> BmwDrvgDynStMac.DampgCmdSca  # UB:Derived from original system description
    connect BmwTqOvrlCdngAndDrvgDynFac.EffortCmdSca -> BmwDrvgDynStMac.EffortCmdSca  # UB:Derived from original system description
    connect BmwTqOvrlCdngAndDrvgDynFac.RtnCmdSca -> BmwDrvgDynStMac.RtnCmdSca  # UB:Derived from original system description
    connect BmwTqOvrlCdngAndDrvgDynFac.BmwOutpTqOvrlCmd -> BmwMotTqOvrlArbn.BmwOutpTqOvrlCmd  # UB:Derived from original system description
    connect BmwTqOvrlCdngAndDrvgDynFac.DampgCmdSca -> ClsdLoopDampg.DampgCmdSca  # UB:Derived from original system description
    connect BmwTqOvrlCdngAndDrvgDynFac.RtnCmdSca -> CtrldVelRtn.RtnCmdSca  # UB:Derived from original system description
    connect BmwTrfcJamAssiDampg.BmwTrfcJamAssiDampgSt -> BmwMotTqOvrlArbn.BmwTrfcJamAssiDampgSt  # UB:Derived from original system description
    connect BmwTrfcJamAssiDampg.TrfcJamAssiCmd -> BmwMotTqOvrlArbn.TrfcJamAssiCmd  # UB:Derived from original system description
    connect BmwVehSpd.VehSpd -> BmwHwTqOvrlArbn.VehSpd  # UB:Derived from original system description
    connect BmwVehSpd.VehSpd -> BmwMotTqOvrlArbn.VehSpd  # UB:Derived from original system description
    connect BmwVehSpd.VehSpd -> BmwTqOvrlCdngAndDrvgDynFac.VehSpd  # UB:Derived from original system description
    connect BmwVehSpd.VehSpd -> BmwTrfcJamAssiDampg.VehSpd  # UB:Derived from original system description
    connect CDD_MotVel.MotVelCrf -> BmwTqOvrlCdngAndDrvgDynFac.MotVelCrf  # UB:Derived from original system description
    connect CDD_MotVel.MotVelCrf -> BmwTrfcJamAssiDampg.MotVelCrf  # UB:Derived from original system description
    connect CDD_NxtrTi.GetRefTmr100MicroSec32bit -> BmwDrvgDynStMac.GetRefTmr100MicroSec32bit  # UB:Derived from original system description
    connect CDD_NxtrTi.GetTiSpan100MicroSec32bit -> BmwDrvgDynStMac.GetTiSpan100MicroSec32bit  # UB:Derived from original system description
    connect CDD_NxtrTi.GetRefTmr100MicroSec32bit -> BmwHwTqOvrlArbn.GetRefTmr100MicroSec32bit  # UB:Derived from original system description
    connect CDD_NxtrTi.GetTiSpan100MicroSec32bit -> BmwHwTqOvrlArbn.GetTiSpan100MicroSec32bit  # UB:Derived from original system description
    connect CDD_NxtrTi.GetRefTmr100MicroSec32bit -> BmwMotTqOvrlArbn.GetRefTmr100MicroSec32bit  # UB:Derived from original system description
    connect CDD_NxtrTi.GetTiSpan100MicroSec32bit -> BmwMotTqOvrlArbn.GetTiSpan100MicroSec32bit  # UB:Derived from original system description
    connect CDD_NxtrTi.GetRefTmr100MicroSec32bit -> BmwTqOvrlCdngAndDrvgDynFac.GetRefTmr100MicroSec32bit  # UB:Derived from original system description
    connect CDD_NxtrTi.GetTiSpan100MicroSec32bit -> BmwTqOvrlCdngAndDrvgDynFac.GetTiSpan100MicroSec32bit  # UB:Derived from original system description
    connect CDD_NxtrTi.GetRefTmr100MicroSec32bit -> BmwTrfcJamAssiDampg.GetRefTmr100MicroSec32bit  # UB:Derived from original system description
    connect CDD_NxtrTi.GetTiSpan100MicroSec32bit -> BmwTrfcJamAssiDampg.GetTiSpan100MicroSec32bit  # UB:Derived from original system description
    connect DiagcMgr.DiagcStsCtrldShtDwnFltPrsnt -> BmwDrvgDynStMac.DiagcStsCtrldShtDwnFltPrsnt  # UB:Derived from original system description
    connect DiagcMgr.DiagcStsNonRcvrlReqDiFltPrsnt -> BmwDrvgDynStMac.DiagcStsNonRcvrlReqDiFltPrsnt  # UB:Derived from original system description
    connect DiagcMgr.SysStFltOutpReqDi -> BmwDrvgDynStMac.SysStFltOutpReqDi  # UB:Derived from original system description
    connect FltInj.FltInj_f32 -> BmwTqOvrlCdngAndDrvgDynFac.FltInj_f32  # UB:Derived from original system description
    connect HwTqArbn.HwTq -> BmwTqOvrlCdngAndDrvgDynFac.HwTq  # UB:Derived from original system description
    connect LrnPinionCentr.PinionCentrLrnCmd -> BmwMotTqOvrlArbn.PinionCentrLrnCmd  # UB:Derived from original system description
    connect PosnTrakgServo.PosnServoCmd -> BmwMotTqOvrlArbn.PosnServoCmd  # UB:Derived from original system description
    connect PwrLimr.MotTqCmdPwrLimd -> BmwDrvgDynStMac.MotTqCmdPwrLimd  # UB:Derived from original system description
    connect TqOscn.HwOscnActv -> BmwMotTqOvrlArbn.HwOscnActv  # UB:Derived from original system description
    connect TqOscn.HwOscnCmd -> BmwMotTqOvrlArbn.HwOscnCmd  # UB:Derived from original system description
    connect TqOscn.HwOscnDcThdExcdd -> BmwMotTqOvrlArbn.HwOscnDcThdExcdd  # UB:Derived from original system description
    delegate BmwMsgSlot49Bas0Repn2BusFrChA.sigGroup_AVL_FORC_GRD <-> outer port sigGroup_AVL_FORC_GRD  # UB:Derived from original system description
    delegate BmwMsgSlot49Bas0Repn2BusFrChA.sigGroup_AVL_STMOM_DV_ACT <-> outer port sigGroup_AVL_STMOM_DV_ACT  # UB:Derived from original system description
    connect BmwStReqMgr.BmwEpsFctSts -> BmwMsgSlot234Bas1Repn2BusFrChA.BmwEpsFctSts  # UB:Derived from original system description
    connect BmwVehSpd.VehSpd -> FalbckAssi.VehSpd  # UB:Derived from original system description
    connect BmwVehSpd.VehSpd -> SteerCmdArbnAndLim.VehSpd  # UB:Derived from original system description
    connect CDD_Bmw5441McuCfg.HwTq4RawAdcAdcFaild -> CDD_HwTq4Meas.HwTq4RawFastAdcAdcFaild  # UB:Derived from original system description
    connect CDD_Bmw5441McuCfg.HwTq5RawAdcAdcFaild -> CDD_HwTq5Meas.HwTq5RawFastAdcAdcFaild  # UB:Derived from original system description
    connect CDD_NxtrTi.GetRefTmr100MicroSec32bit -> SteerCmdArbnAndLim.GetRefTmr100MicroSec32bit  # UB:Derived from original system description
    connect CDD_NxtrTi.GetTiSpan100MicroSec32bit -> SteerCmdArbnAndLim.GetTiSpan100MicroSec32bit  # UB:Derived from original system description
    connect CmnMfgSrv.AssiLnrGain -> SteerCmdArbnAndLim.AssiLnrGain  # UB:Derived from original system description
    connect CmnMfgSrv.AssiLnrGainEna -> SteerCmdArbnAndLim.AssiLnrGainEna  # UB:Derived from original system description
    connect DiagcMgrProxyAppl10.SetNtcSts10 -> SteerCmdArbnAndLim.SetNtcSts  # UB:Derived from original system description
    connect ElecPwrCns.ElecInpPwrEstim -> BmwMsgSlot49Bas0Repn2BusFrChA.ElecInpPwrEstim  # UB:Derived from original system description
    connect EotProtn.EotAssiSca -> SteerCmdArbnAndLim.EotCtrlSca  # UB:Derived from original system description
    connect FalbckAssi.FalbckAssiMotTqCmd -> SteerCmdArbnAndLim.FalbckAssiMotTqCmd  # UB:Derived from original system description
    connect GlbLimr.LimdMotTqCmd -> SteerCmdArbnAndLim.LimdMotTqCmd  # UB:Derived from original system description
    connect HwTqArbn.HwTq -> FalbckAssi.HwTq  # UB:Derived from original system description
    connect HwTqArbn.HwTq -> HwTqCorrln.HwTqChA  # UB:Derived from original system description
    connect HwTqArbn.HwTq -> SteerCmdArbnAndLim.HwTq  # UB:Derived from original system description
    connect HwTqTrakgCtrl.MotTqCmdTrakgCtrl -> SteerCmdArbnAndLim.MotTqCmd  # UB:Derived from original system description
    connect LimrCdng.StallMotTqLimCdnd -> SteerCmdArbnAndLim.StallMotTqLim  # UB:Derived from original system description
    connect LimrCdng.SysMotTqCmdScaCdnd -> SteerCmdArbnAndLim.SysMotTqCmdSca  # UB:Derived from original system description
    connect LimrCdng.ThermMotTqLimCdnd -> SteerCmdArbnAndLim.ThermMotTqLim  # UB:Derived from original system description
    connect LimrCdng.VehSpdMotTqLimCdnd -> SteerCmdArbnAndLim.VehSpdMotTqLim  # UB:Derived from original system description
    connect SteerCmdArbnAndLim.SetManTqCmd -> CmnMfgSrv.SetManTqCmd  # UB:Derived from original system description
    connect SteerCmdArbnAndLim.MotTqCmdLimdPreStall -> HiLoadStallLimr.MotTqCmdLimdPreStall  # UB:Derived from original system description
    connect SteerCmdArbnAndLim.SetManTqCmd -> MotVelCtrl.SetManTqCmd  # UB:Derived from original system description
    connect SteerCmdArbnAndLim.ArbdMotTqCmd -> Swp.MotTqCmd  # UB:Derived from original system description
    connect TurnCntrCorrln.TurnCntrCorrlnSts -> BmwDiagcSrvHndlg.TurnCntrCorrlnSts  # UB:Derived from original system description
    connect BmwHwAgArbnAndEotPosn.PinionAg -> ClsdLoopHys.HwAg  # UB:Derived from original system description
    connect BmwMsgSlot68Bas0Repn2BusFrChA.BmwTrfcJamAssiDampgScaReqVld -> BmwTrfcJamAssiDampg.BmwTrfcJamAssiDampgScaReqVld  # UB:Derived from original system description
    connect BmwVehSpd.VehSpd -> ClsdLoopHys.VehSpd  # UB:Derived from original system description
    connect Effort.HwTqCmdEffort -> ClsdLoopHys.HwTqCmdEffort  # UB:Derived from original system description
    connect EpsStEstimn.RackFEstimd -> ClsdLoopHys.RackFEstimd  # UB:Derived from original system description
    connect HwTqArbn.HwTq -> ClsdLoopHys.HwTq  # UB:Derived from original system description
    connect SysKineAndEff.HwVel -> ClsdLoopHys.HwVel  # UB:Derived from original system description
    connect BmwTqOvrlCdngAndDrvgDynFac.EffortCmdSca -> Effort.EffortCmdSca  # UB:Derived from original system description
    connect BmwMotTqOvrlArbn.MotTqOvrlCmd -> HwTqTrakgCtrl.MotTqCmdOvrl  # UB:Derived from original system description
    connect CalRegn01Cmn.BattVltgCorrlnAllwdVltgDif -> BattVltgCorrln.BattVltgCorrlnAllwdVltgDif  # UB:Derived from original system description
    connect CalRegn01Cmn.BattVltgCorrlnBattLoVltg -> BattVltgCorrln.BattVltgCorrlnBattLoVltg  # UB:Derived from original system description
    connect CalRegn01Cmn.BattVltgCorrlnBattOverVltg -> BattVltgCorrln.BattVltgCorrlnBattOverVltg  # UB:Derived from original system description
    connect CalRegn01Cmn.BattVltgCorrlnBattUnderVltg -> BattVltgCorrln.BattVltgCorrlnBattUnderVltg  # UB:Derived from original system description
    connect CalRegn01Cmn.BattVltgCorrlnNtc0x03C0x044FailStep -> BattVltgCorrln.BattVltgCorrlnNtc0x03C0x044FailStep  # UB:Derived from original system description
    connect CalRegn01Cmn.BattVltgCorrlnNtc0x03C0x044PassStep -> BattVltgCorrln.BattVltgCorrlnNtc0x03C0x044PassStep  # UB:Derived from original system description
    connect CalRegn01Cmn.BattVltgCorrlnNtc0x0B0FailStep -> BattVltgCorrln.BattVltgCorrlnNtc0x0B0FailStep  # UB:Derived from original system description
    connect CalRegn01Cmn.BattVltgCorrlnNtc0x0B0PassStep -> BattVltgCorrln.BattVltgCorrlnNtc0x0B0PassStep  # UB:Derived from original system description
    connect CalRegn01Cmn.BattVltgCorrlnNtc0x0B1FailStep -> BattVltgCorrln.BattVltgCorrlnNtc0x0B1FailStep  # UB:Derived from original system description
    connect CalRegn01Cmn.BattVltgCorrlnNtc0x0B1PassStep -> BattVltgCorrln.BattVltgCorrlnNtc0x0B1PassStep  # UB:Derived from original system description
    connect CalRegn01Cmn.BattVltgCorrlnNtc0x0B5FailStep -> BattVltgCorrln.BattVltgCorrlnNtc0x0B5FailStep  # UB:Derived from original system description
    connect CalRegn01Cmn.BattVltgCorrlnNtc0x0B5PassStep -> BattVltgCorrln.BattVltgCorrlnNtc0x0B5PassStep  # UB:Derived from original system description
    connect CalRegn01Cmn.BattVltgCorrlnRcvrlBattLoVltg -> BattVltgCorrln.BattVltgCorrlnRcvrlBattLoVltg  # UB:Derived from original system description
    connect CalRegn01Cmn.BattVltgCorrlnRcvrlBattOverVltg -> BattVltgCorrln.BattVltgCorrlnRcvrlBattOverVltg  # UB:Derived from original system description
    connect CalRegn01Cmn.BattVltgCorrlnRcvrlBattUnderVltg -> BattVltgCorrln.BattVltgCorrlnRcvrlBattUnderVltg  # UB:Derived from original system description
    connect CalRegn01Cmn.BattVltgCorrlnSwdMax -> BattVltgCorrln.BattVltgCorrlnSwdMax  # UB:Derived from original system description
    connect CalRegn01Cmn.BattVltgCorrlnSysMinVltg -> BattVltgCorrln.BattVltgCorrlnSysMinVltg  # UB:Derived from original system description
    connect CalRegn01Cmn.BmwTunSetHndlrBmwRtIdxDebThd -> BmwTunSetHndlr.BmwTunSetHndlrBmwRtIdxDebThd  # UB:Derived from original system description
    connect CalRegn01Cmn.AdcDiagcNtc0x032FailStep -> CDD_AdcDiagc.AdcDiagcNtc0x032FailStep  # UB:Derived from original system description
    connect CalRegn01Cmn.AdcDiagcNtc0x032PassStep -> CDD_AdcDiagc.AdcDiagcNtc0x032PassStep  # UB:Derived from original system description
    connect CalRegn01Cmn.AdcDiagcNtc0x033FailStep -> CDD_AdcDiagc.AdcDiagcNtc0x033FailStep  # UB:Derived from original system description
    connect CalRegn01Cmn.AdcDiagcNtc0x033PassStep -> CDD_AdcDiagc.AdcDiagcNtc0x033PassStep  # UB:Derived from original system description
    connect CalRegn01Cmn.CurrMeasEolFixdPwmPerd -> CDD_CurrMeas.CurrMeasEolFixdPwmPerd  # UB:Derived from original system description
    connect CalRegn01Cmn.CurrMeasEolGainMax -> CDD_CurrMeas.CurrMeasEolGainMax  # UB:Derived from original system description
    connect CalRegn01Cmn.CurrMeasEolGainMin -> CDD_CurrMeas.CurrMeasEolGainMin  # UB:Derived from original system description
    connect CalRegn01Cmn.CurrMeasEolGainNom -> CDD_CurrMeas.CurrMeasEolGainNom  # UB:Derived from original system description
    connect CalRegn01Cmn.CurrMeasEolGainNrOfSample -> CDD_CurrMeas.CurrMeasEolGainNrOfSample  # UB:Derived from original system description
    connect CalRegn01Cmn.CurrMeasEolGainNumer -> CDD_CurrMeas.CurrMeasEolGainNumer  # UB:Derived from original system description
    connect CalRegn01Cmn.CurrMeasEolMaxMotVel -> CDD_CurrMeas.CurrMeasEolMaxMotVel  # UB:Derived from original system description
    connect CalRegn01Cmn.CurrMeasEolOffsHiBrdgVltgMin -> CDD_CurrMeas.CurrMeasEolOffsHiBrdgVltgMin  # UB:Derived from original system description
    connect CalRegn01Cmn.CurrMeasEolOffsHiCmuOffs -> CDD_CurrMeas.CurrMeasEolOffsHiCmuOffs  # UB:Derived from original system description
    connect CalRegn01Cmn.CurrMeasEolOffsLoCmuOffs -> CDD_CurrMeas.CurrMeasEolOffsLoCmuOffs  # UB:Derived from original system description
    connect CalRegn01Cmn.CurrMeasEolOffsMax -> CDD_CurrMeas.CurrMeasEolOffsMax  # UB:Derived from original system description
    connect CalRegn01Cmn.CurrMeasEolOffsMin -> CDD_CurrMeas.CurrMeasEolOffsMin  # UB:Derived from original system description
    connect CalRegn01Cmn.CurrMeasEolOffsNom -> CDD_CurrMeas.CurrMeasEolOffsNom  # UB:Derived from original system description
    connect CalRegn01Cmn.CurrMeasEolOffsNrOfSample -> CDD_CurrMeas.CurrMeasEolOffsNrOfSample  # UB:Derived from original system description
    connect CalRegn01Cmn.CurrMeasEolTranCntrThd -> CDD_CurrMeas.CurrMeasEolTranCntrThd  # UB:Derived from original system description
    connect CalRegn01Cmn.CurrMeasMinRqrdPhaOnTi -> CDD_CurrMeas.CurrMeasMinRqrdPhaOnTi  # UB:Derived from original system description
    connect CalRegn01Cmn.CurrMeasMotAgCompuDly -> CDD_CurrMeas.CurrMeasMotAgCompuDly  # UB:Derived from original system description
    connect CalRegn01Cmn.CurrMeasMotCurrAdcVlyWrmIninMax -> CDD_CurrMeas.CurrMeasMotCurrAdcVlyWrmIninMax  # UB:Derived from original system description
    connect CalRegn01Cmn.CurrMeasMotCurrAdcVlyWrmIninMin -> CDD_CurrMeas.CurrMeasMotCurrAdcVlyWrmIninMin  # UB:Derived from original system description
    connect CalRegn01Cmn.CurrMeasNtc0x05DFailStep -> CDD_CurrMeas.CurrMeasNtc0x05DFailStep  # UB:Derived from original system description
    connect CalRegn01Cmn.CurrMeasNtc0x05DPassStep -> CDD_CurrMeas.CurrMeasNtc0x05DPassStep  # UB:Derived from original system description
    connect CalRegn01Cmn.SysGlbPrmMotPoleCnt -> CDD_CurrMeas.SysGlbPrmMotPoleCnt  # UB:Derived from original system description
    connect CalRegn01Cmn.CurrMeasArbnMaxStallCntr -> CDD_CurrMeasArbn.CurrMeasArbnMaxStallCntr  # UB:Derived from original system description
    connect CalRegn01Cmn.HwTq4MeasHwTq4PrtclFltFailStep -> CDD_HwTq4Meas.HwTq4MeasHwTq4PrtclFltFailStep  # UB:Derived from original system description
    connect CalRegn01Cmn.HwTq4MeasHwTq4PrtclFltPassStep -> CDD_HwTq4Meas.HwTq4MeasHwTq4PrtclFltPassStep  # UB:Derived from original system description
    connect CalRegn01Cmn.HwTq4MeasHwTqRngHiLim -> CDD_HwTq4Meas.HwTq4MeasHwTqRngHiLim  # UB:Derived from original system description
    connect CalRegn01Cmn.HwTq4MeasHwTqRngLoLim -> CDD_HwTq4Meas.HwTq4MeasHwTqRngLoLim  # UB:Derived from original system description
    connect CalRegn01Cmn.HwTq4MeasMovgAvrgFilEna -> CDD_HwTq4Meas.HwTq4MeasMovgAvrgFilEna  # UB:Derived from original system description
    connect CalRegn01Cmn.HwTq5MeasHwTq5PrtclFltFailStep -> CDD_HwTq5Meas.HwTq5MeasHwTq5PrtclFltFailStep  # UB:Derived from original system description
    connect CalRegn01Cmn.HwTq5MeasHwTq5PrtclFltPassStep -> CDD_HwTq5Meas.HwTq5MeasHwTq5PrtclFltPassStep  # UB:Derived from original system description
    connect CalRegn01Cmn.HwTq5MeasHwTqRngHiLim -> CDD_HwTq5Meas.HwTq5MeasHwTqRngHiLim  # UB:Derived from original system description
    connect CalRegn01Cmn.HwTq5MeasHwTqRngLoLim -> CDD_HwTq5Meas.HwTq5MeasHwTqRngLoLim  # UB:Derived from original system description
    connect CalRegn01Cmn.HwTq5MeasMovgAvrgFilEna -> CDD_HwTq5Meas.HwTq5MeasMovgAvrgFilEna  # UB:Derived from original system description
    connect CalRegn01Cmn.McuDiagc2MilliSecCntrCompThd -> CDD_McuDiagc.McuDiagc2MilliSecCntrCompThd  # UB:Derived from original system description
    connect CalRegn01Cmn.McuDiagcFltFailStep -> CDD_McuDiagc.McuDiagcFltFailStep  # UB:Derived from original system description
    connect CalRegn01Cmn.McuDiagcFltPassStep -> CDD_McuDiagc.McuDiagcFltPassStep  # UB:Derived from original system description
    connect CalRegn01Cmn.MotAg0MeasSnsrIfErrNtcMask -> CDD_MotAg0Meas.MotAg0MeasSnsrIfErrNtcMask  # UB:Derived from original system description
    connect CalRegn01Cmn.MotAg1MeasOffs -> CDD_MotAg1Meas.MotAg1MeasOffs  # UB:Derived from original system description
    connect CalRegn01Cmn.MotAg1MeasSnsrIfErrNtcMask -> CDD_MotAg1Meas.MotAg1MeasSnsrIfErrNtcMask  # UB:Derived from original system description
    connect CalRegn01Cmn.SysGlbPrmMotPoleCnt -> CDD_MotAgCmp.SysGlbPrmMotPoleCnt  # UB:Derived from original system description
    connect CalRegn01Cmn.MotCurrRegCfgCurrLoopSecOrderTrfFctEna -> CDD_MotCurrRegVltgLimr.MotCurrRegCfgCurrLoopSecOrderTrfFctEna  # UB:Derived from original system description
    connect CalRegn01Cmn.MotCurrRegVltgLimrMotCurrPredEna -> CDD_MotCurrRegVltgLimr.MotCurrRegVltgLimrMotCurrPredEna  # UB:Derived from original system description
    connect CalRegn01Cmn.MotCurrRegVltgLimrMotCurrPredTi -> CDD_MotCurrRegVltgLimr.MotCurrRegVltgLimrMotCurrPredTi  # UB:Derived from original system description
    connect CalRegn01Cmn.MotCurrRegVltgLimrMotCurrQaxRefMdfnRplEna -> CDD_MotCurrRegVltgLimr.MotCurrRegVltgLimrMotCurrQaxRefMdfnRplEna  # UB:Derived from original system description
    connect CalRegn01Cmn.MotCurrRegVltgLimrMotVltgBrdgFilEna -> CDD_MotCurrRegVltgLimr.MotCurrRegVltgLimrMotVltgBrdgFilEna  # UB:Derived from original system description
    connect CalRegn01Cmn.MotCurrRegVltgLimrMotVltgQaxFfFilEna -> CDD_MotCurrRegVltgLimr.MotCurrRegVltgLimrMotVltgQaxFfFilEna  # UB:Derived from original system description
    connect CalRegn01Cmn.MotRefMdlFbCtrlDi -> CDD_MotCurrRegVltgLimr.MotRefMdlFbCtrlDi  # UB:Derived from original system description
    connect CalRegn01Cmn.MotRefMdlIvtrDeadTiBrdgVltgSca -> CDD_MotCurrRegVltgLimr.MotRefMdlIvtrDeadTiBrdgVltgSca  # UB:Derived from original system description
    connect CalRegn01Cmn.SinVltgGennDthrEna -> CDD_SinVltgGenn.SinVltgGennDthrEna  # UB:Derived from original system description
    connect CalRegn01Cmn.SinVltgGennDthrLpFilCoeff -> CDD_SinVltgGenn.SinVltgGennDthrLpFilCoeff  # UB:Derived from original system description
    connect CalRegn01Cmn.CurrMeasEolFixdPwmPerd -> CDD_TSG31CfgAndUse.CurrMeasEolFixdPwmPerd  # UB:Derived from original system description
    connect CalRegn01Cmn.CurrMeasEolOffsHiCmuOffs -> CDD_TSG31CfgAndUse.CurrMeasEolOffsHiCmuOffs  # UB:Derived from original system description
    connect CalRegn01Cmn.CurrMeasEolOffsLoCmuOffs -> CDD_TSG31CfgAndUse.CurrMeasEolOffsLoCmuOffs  # UB:Derived from original system description
    connect CalRegn01Cmn.PhaDiscnctFixdPhaOnTi -> CDD_TSG31CfgAndUse.PhaDiscnctFixdPhaOnTi  # UB:Derived from original system description
    connect CalRegn01Cmn.PhaDiscnctFixdPwmPerd -> CDD_TSG31CfgAndUse.PhaDiscnctFixdPwmPerd  # UB:Derived from original system description
    connect CalRegn01Cmn.TSG31CfgAndUseAdcStrtOfCnvn2Offs -> CDD_TSG31CfgAndUse.TSG31CfgAndUseAdcStrtOfCnvn2Offs  # UB:Derived from original system description
    connect CalRegn01Cmn.TSG31CfgAndUseAdcStrtOfCnvnMotCtrlPeakOffs -> CDD_TSG31CfgAndUse.TSG31CfgAndUseAdcStrtOfCnvnMotCtrlPeakOffs  # UB:Derived from original system description
    connect CalRegn01Cmn.TSG31CfgAndUseAdcStrtOfCnvnMotCtrlVlyOffs -> CDD_TSG31CfgAndUse.TSG31CfgAndUseAdcStrtOfCnvnMotCtrlVlyOffs  # UB:Derived from original system description
    connect CalRegn01Cmn.TSG31CfgAndUseMtrAg0SPIStart -> CDD_TSG31CfgAndUse.TSG31CfgAndUseMtrAg0SPIStart  # UB:Derived from original system description
    connect CalRegn01Cmn.TSG31CfgAndUsePwmDbnd -> CDD_TSG31CfgAndUse.TSG31CfgAndUsePwmDbnd  # UB:Derived from original system description
    connect CalRegn01Cmn.CmplncErrHwAgNonLinCmplncDepTblY -> CmplncErr.CmplncErrHwAgNonLinCmplncDepTblY  # UB:Derived from original system description
    connect CalRegn01Cmn.CmplncErrHwAgNonLinCmplncIndTblX -> CmplncErr.CmplncErrHwAgNonLinCmplncIndTblX  # UB:Derived from original system description
    connect CalRegn01Cmn.CmplncErrMotAgNonLinCmplncDepTblY -> CmplncErr.CmplncErrMotAgNonLinCmplncDepTblY  # UB:Derived from original system description
    connect CalRegn01Cmn.CmplncErrMotAgNonLinCmplncIndTblX -> CmplncErr.CmplncErrMotAgNonLinCmplncIndTblX  # UB:Derived from original system description
    connect CalRegn01Cmn.CurrMeasCorrlnMaxErrCurr -> CurrMeasCorrln.CurrMeasCorrlnMaxErrCurr  # UB:Derived from original system description
    connect CalRegn01Cmn.CurrMeasCorrlnMaxStallCntr -> CurrMeasCorrln.CurrMeasCorrlnMaxStallCntr  # UB:Derived from original system description
    connect CalRegn01Cmn.CurrMeasCorrlnNtc0x04DFailStep -> CurrMeasCorrln.CurrMeasCorrlnNtc0x04DFailStep  # UB:Derived from original system description
    connect CalRegn01Cmn.CurrMeasCorrlnNtc0x04DPassStep -> CurrMeasCorrln.CurrMeasCorrlnNtc0x04DPassStep  # UB:Derived from original system description
    connect CalRegn01Cmn.DiagcMgrFltResp -> DiagcMgr.DiagcMgrFltResp  # UB:Derived from original system description
    connect CalRegn01Cmn.DiagcMgrFltResp -> DiagcMgrProxyAppl10.DiagcMgrFltResp  # UB:Derived from original system description
    connect CalRegn01Cmn.DiagcMgrFltResp -> DiagcMgrProxyAppl{7..9}.DiagcMgrFltResp  # UB:Derived from original system description
    connect CalRegn01Cmn.ElecPwrCnsCtrlrInpR -> ElecPwrCns.ElecPwrCnsCtrlrInpR  # UB:Derived from original system description
    connect CalRegn01Cmn.GateDrv0CtrlErrFilFrq -> GateDrv0Ctrl.GateDrv0CtrlErrFilFrq  # UB:Derived from original system description
    connect CalRegn01Cmn.GateDrv0CtrlErrOffs -> GateDrv0Ctrl.GateDrv0CtrlErrOffs  # UB:Derived from original system description
    connect CalRegn01Cmn.GateDrv0CtrlErrThd -> GateDrv0Ctrl.GateDrv0CtrlErrThd  # UB:Derived from original system description
    connect CalRegn01Cmn.GateDrv0CtrlNtcNr0x050FailStep -> GateDrv0Ctrl.GateDrv0CtrlNtcNr0x050FailStep  # UB:Derived from original system description
    connect CalRegn01Cmn.GateDrv0CtrlNtcNr0x050PassStep -> GateDrv0Ctrl.GateDrv0CtrlNtcNr0x050PassStep  # UB:Derived from original system description
    connect CalRegn01Cmn.GateDrv0CtrlNtcNr0x051FailStep -> GateDrv0Ctrl.GateDrv0CtrlNtcNr0x051FailStep  # UB:Derived from original system description
    connect CalRegn01Cmn.GateDrv0CtrlNtcNr0x051PassStep -> GateDrv0Ctrl.GateDrv0CtrlNtcNr0x051PassStep  # UB:Derived from original system description
    connect CalRegn01Cmn.GateDrv0CtrlNtcNr0x055FailStep -> GateDrv0Ctrl.GateDrv0CtrlNtcNr0x055FailStep  # UB:Derived from original system description
    connect CalRegn01Cmn.GateDrv0CtrlNtcNr0x055PassStep -> GateDrv0Ctrl.GateDrv0CtrlNtcNr0x055PassStep  # UB:Derived from original system description
    connect CalRegn01Cmn.GateDrv0CtrlUnit0Cfg{2..4}WrVal -> GateDrv0Ctrl.GateDrv0CtrlUnit0Cfg{2..4}WrVal  # UB:Derived from original system description
    connect CalRegn01Cmn.GateDrv0CtrlUnit0Cfg7WrVal -> GateDrv0Ctrl.GateDrv0CtrlUnit0Cfg7WrVal  # UB:Derived from original system description
    connect CalRegn01Cmn.HiLoadStallLimrMotTqCmdFetMtgtnEnaFilFrq -> HiLoadStallLimr.HiLoadStallLimrMotTqCmdFetMtgtnEnaFilFrq  # UB:Derived from original system description
    connect CalRegn01Cmn.HiLoadStallLimrMotTqCmdFilFrq -> HiLoadStallLimr.HiLoadStallLimrMotTqCmdFilFrq  # UB:Derived from original system description
    connect CalRegn01Cmn.HwTqCorrlnChACmnModCmpLpFilActvnThd -> HwTqCorrln.HwTqCorrlnChACmnModCmpLpFilActvnThd  # UB:Derived from original system description
    connect CalRegn01Cmn.HwTqCorrlnChACmnModCmpLpFilFrq -> HwTqCorrln.HwTqCorrlnChACmnModCmpLpFilFrq  # UB:Derived from original system description
    connect CalRegn01Cmn.HwTqCorrlnChACmnModCmpLpFilOutpLim -> HwTqCorrln.HwTqCorrlnChACmnModCmpLpFilOutpLim  # UB:Derived from original system description
    connect CalRegn01Cmn.HwTqCorrlnChAImdtCorrlnChkFailThd -> HwTqCorrln.HwTqCorrlnChAImdtCorrlnChkFailThd  # UB:Derived from original system description
    connect CalRegn01Cmn.HwTqCorrlnChAImdtCorrlnChkPassThd -> HwTqCorrln.HwTqCorrlnChAImdtCorrlnChkPassThd  # UB:Derived from original system description
    connect CalRegn01Cmn.HwTqCorrlnChAStabStClrFltThd -> HwTqCorrln.HwTqCorrlnChAStabStClrFltThd  # UB:Derived from original system description
    connect CalRegn01Cmn.HwTqCorrlnChAStabStLpFilFrq -> HwTqCorrln.HwTqCorrlnChAStabStLpFilFrq  # UB:Derived from original system description
    connect CalRegn01Cmn.HwTqCorrlnChAStabStSetFltThd -> HwTqCorrln.HwTqCorrlnChAStabStSetFltThd  # UB:Derived from original system description
    connect CalRegn01Cmn.HwTqCorrlnChATqSumMaxLim -> HwTqCorrln.HwTqCorrlnChATqSumMaxLim  # UB:Derived from original system description
    connect CalRegn01Cmn.HwTqCorrlnChATraLpFilX -> HwTqCorrln.HwTqCorrlnChATraLpFilX  # UB:Derived from original system description
    connect CalRegn01Cmn.HwTqCorrlnChATraLpFilY -> HwTqCorrln.HwTqCorrlnChATraLpFilY  # UB:Derived from original system description
    connect CalRegn01Cmn.HwTqCorrlnChATraSumClrFltThd -> HwTqCorrln.HwTqCorrlnChATraSumClrFltThd  # UB:Derived from original system description
    connect CalRegn01Cmn.HwTqCorrlnChATraSumSetFltThd -> HwTqCorrln.HwTqCorrlnChATraSumSetFltThd  # UB:Derived from original system description
    connect CalRegn01Cmn.LimrCdngGainDecSlew -> LimrCdng.LimrCdngGainDecSlew  # UB:Derived from original system description
    connect CalRegn01Cmn.LimrCdngGainIncSlewX -> LimrCdng.LimrCdngGainIncSlewX  # UB:Derived from original system description
    connect CalRegn01Cmn.LimrCdngGainIncSlewY -> LimrCdng.LimrCdngGainIncSlewY  # UB:Derived from original system description
    connect CalRegn01Cmn.LimrCdngTqDecSlew -> LimrCdng.LimrCdngTqDecSlew  # UB:Derived from original system description
    connect CalRegn01Cmn.LimrCdngTqIncSlewX -> LimrCdng.LimrCdngTqIncSlewX  # UB:Derived from original system description
    connect CalRegn01Cmn.LimrCdngTqIncSlewY -> LimrCdng.LimrCdngTqIncSlewY  # UB:Derived from original system description
    connect CalRegn01Cmn.LoaMgrCurrIvtrMtgtnRate -> LoaMgr.LoaMgrCurrIvtrMtgtnRate  # UB:Derived from original system description
    connect CalRegn01Cmn.LoaMgrCurrIvtrMtgtnSca -> LoaMgr.LoaMgrCurrIvtrMtgtnSca  # UB:Derived from original system description
    connect CalRegn01Cmn.LoaMgrCurrIvtrMtgtnScaZeroEna -> LoaMgr.LoaMgrCurrIvtrMtgtnScaZeroEna  # UB:Derived from original system description
    connect CalRegn01Cmn.LoaMgrCurrMeasIdptSig{0..2}Resp -> LoaMgr.LoaMgrCurrMeasIdptSig{0..2}Resp  # UB:Derived from original system description
    connect CalRegn01Cmn.LoaMgrCurrMeasIdptSigFltThd -> LoaMgr.LoaMgrCurrMeasIdptSigFltThd  # UB:Derived from original system description
    connect CalRegn01Cmn.LoaMgrCurrMeasMtgtnRate -> LoaMgr.LoaMgrCurrMeasMtgtnRate  # UB:Derived from original system description
